VERSION ""

NS_ :

BS_:

BU_: SBW iBooster IMG ESB EBB TM ACC SRS SMART NAVI AHU FCM EPS HDS SS30 METER CVT STR ENG ABS VSA EAT RTC PUH EPT2 EPT1 EPB ASC ACM BCM E4WD ANC TPMS APS

BO_ 3221225472 VECTOR__INDEPENDENT_SIG_MSG: 0 Vector__XXX
 SG_ VSA_MC_PRESSURE_05D_2 : 0|10@1- (1,0) [0|0] "" Vector__XXX
 SG_ VSA_ACC_INHBIT_ACC_BRK_PAD_TMP_1 : 0|1@0+ (1,0) [0|1] "" Vector__XXX
 SG_ VSA_INH_MODE13_2 : 0|1@0+ (1,0) [0|1] "" Vector__XXX
 SG_ VSA_INH_MODE15_2 : 0|1@0+ (1,0) [0|1] "" Vector__XXX
 SG_ VSA_INH_MODE14_2 : 0|1@0+ (1,0) [0|1] "" Vector__XXX
 SG_ VSA_INH_MODE6_2 : 0|1@0+ (1,0) [0|1] "" Vector__XXX
 SG_ VSA_INH_MODE5_2 : 0|1@0+ (1,0) [0|1] "" Vector__XXX
 SG_ VSA_INH_MODE4_2 : 0|1@0+ (1,0) [0|1] "" Vector__XXX
 SG_ VSA_INH_MODE_CHANGE_2 : 0|1@0+ (1,0) [0|1] "" Vector__XXX
 SG_ VSA_INH_MODE0_2 : 0|1@0+ (1,0) [0|1] "" Vector__XXX
 SG_ VSA_INH_MODE1_2 : 0|1@0+ (1,0) [0|1] "" Vector__XXX
 SG_ VSA_INH_MODE2_2 : 0|1@0+ (1,0) [0|1] "" Vector__XXX
 SG_ VSA_INH_MODE3_2 : 0|1@0+ (1,0) [0|1] "" Vector__XXX
 SG_ VSA_INH_MODE7_2 : 0|1@0+ (1,0) [0|1] "" Vector__XXX
 SG_ ENG_CAS_REQ_2 : 0|1@0+ (1,0) [0|1] "" Vector__XXX
 SG_ IMG_REQ_BRKRELAY_STATUS_2 : 0|1@0+ (1,0) [0|1] "" Vector__XXX
 SG_ METER_STRG_SW_PUSH_FOR_VSA_OFF_2 : 0|1@0+ (1,0) [0|0] "" Vector__XXX

BO_ 2209174799 VSA_03AD550F_CH2: 3 VSA
 SG_ VSA_ALIVE_COUNTER_03AD550F_2 : 21|2@0+ (1,0) [0|3] ""  EPS
 SG_ VSA_CHECKSUM_03AD550F_2 : 19|4@0+ (1,0) [0|15] ""  EPS
 SG_ VSA_MAC_stRegMacKey_2 : 15|3@0+ (1,0) [0|7] ""  EPS
 SG_ VSA_MAC_stCompMacAccum_2 : 7|2@0+ (1,0) [0|3] ""  EPS
 SG_ VSA_MAC_stCompMacCont_2 : 5|3@0+ (1,0) [0|7] ""  EPS
 SG_ VSA_MAC_stGenMac_2 : 2|3@0+ (1,0) [0|7] ""  EPS

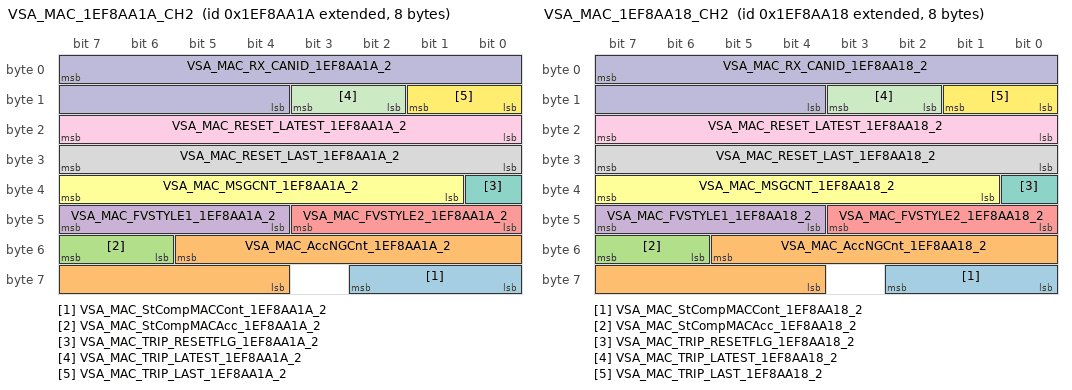
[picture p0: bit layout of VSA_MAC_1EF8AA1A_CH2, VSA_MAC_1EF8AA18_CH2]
BO_ 2667096602 VSA_MAC_1EF8AA1A_CH2: 8 Vector__XXX
 SG_ VSA_MAC_StCompMACCont_1EF8AA1A_2 : 58|3@0+ (1,0) [0|7] ""  SRS
 SG_ VSA_MAC_AccNGCnt_1EF8AA1A_2 : 53|10@0+ (1,0) [0|1023] ""  SRS
 SG_ VSA_MAC_StCompMACAcc_1EF8AA1A_2 : 55|2@0+ (1,0) [0|3] ""  SRS
 SG_ VSA_MAC_FVSTYLE1_1EF8AA1A_2 : 47|4@0+ (1,0) [0|15] ""  SRS
 SG_ VSA_MAC_FVSTYLE2_1EF8AA1A_2 : 43|4@0+ (1,0) [0|15] ""  SRS
 SG_ VSA_MAC_MSGCNT_1EF8AA1A_2 : 39|7@0+ (1,0) [0|127] ""  SRS
 SG_ VSA_MAC_TRIP_RESETFLG_1EF8AA1A_2 : 32|1@0+ (1,0) [0|1] ""  SRS
 SG_ VSA_MAC_RESET_LAST_1EF8AA1A_2 : 31|8@0+ (1,0) [0|255] ""  SRS
 SG_ VSA_MAC_RESET_LATEST_1EF8AA1A_2 : 23|8@0+ (1,0) [0|255] ""  SRS
 SG_ VSA_MAC_RX_CANID_1EF8AA1A_2 : 7|12@0+ (1,0) [0|4095] ""  SRS
 SG_ VSA_MAC_TRIP_LATEST_1EF8AA1A_2 : 11|2@0+ (1,0) [0|3] ""  SRS
 SG_ VSA_MAC_TRIP_LAST_1EF8AA1A_2 : 9|2@0+ (1,0) [0|3] ""  SRS

BO_ 2667096600 VSA_MAC_1EF8AA18_CH2: 8 VSA
 SG_ VSA_MAC_StCompMACCont_1EF8AA18_2 : 58|3@0+ (1,0) [0|7] ""  EBB
 SG_ VSA_MAC_AccNGCnt_1EF8AA18_2 : 53|10@0+ (1,0) [0|1023] ""  EBB
 SG_ VSA_MAC_StCompMACAcc_1EF8AA18_2 : 55|2@0+ (1,0) [0|3] ""  EBB
 SG_ VSA_MAC_FVSTYLE1_1EF8AA18_2 : 47|4@0+ (1,0) [0|15] ""  EBB
 SG_ VSA_MAC_FVSTYLE2_1EF8AA18_2 : 43|4@0+ (1,0) [0|15] ""  EBB
 SG_ VSA_MAC_MSGCNT_1EF8AA18_2 : 39|7@0+ (1,0) [0|127] ""  EBB
 SG_ VSA_MAC_TRIP_RESETFLG_1EF8AA18_2 : 32|1@0+ (1,0) [0|1] ""  EBB
 SG_ VSA_MAC_RESET_LAST_1EF8AA18_2 : 31|8@0+ (1,0) [0|255] ""  EBB
 SG_ VSA_MAC_RESET_LATEST_1EF8AA18_2 : 23|8@0+ (1,0) [0|255] ""  EBB
 SG_ VSA_MAC_RX_CANID_1EF8AA18_2 : 7|12@0+ (1,0) [0|4095] ""  EBB
 SG_ VSA_MAC_TRIP_LATEST_1EF8AA18_2 : 11|2@0+ (1,0) [0|3] ""  EBB
 SG_ VSA_MAC_TRIP_LAST_1EF8AA18_2 : 9|2@0+ (1,0) [0|3] ""  EBB

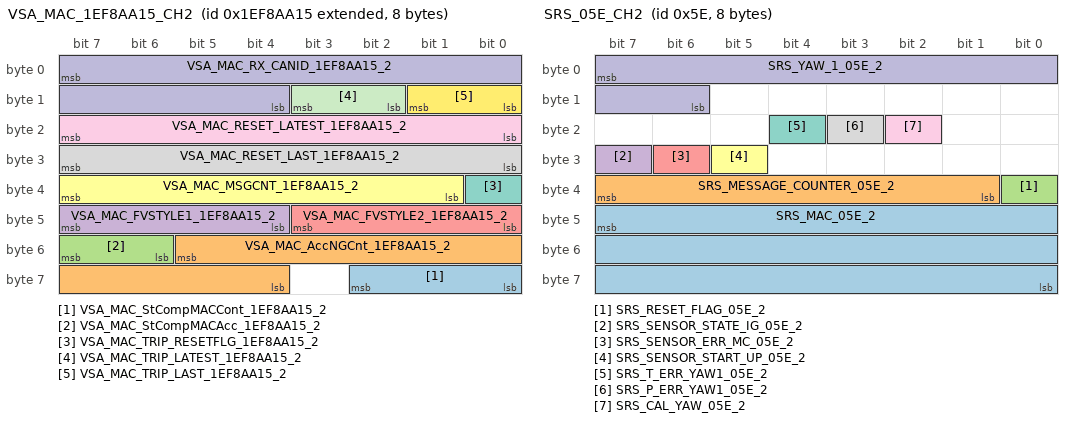
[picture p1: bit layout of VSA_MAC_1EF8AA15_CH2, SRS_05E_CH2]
BO_ 2667096597 VSA_MAC_1EF8AA15_CH2: 8 VSA
 SG_ VSA_MAC_StCompMACCont_1EF8AA15_2 : 58|3@0+ (1,0) [0|7] ""  ESB
 SG_ VSA_MAC_AccNGCnt_1EF8AA15_2 : 53|10@0+ (1,0) [0|1023] ""  ESB
 SG_ VSA_MAC_StCompMACAcc_1EF8AA15_2 : 55|2@0+ (1,0) [0|3] ""  ESB
 SG_ VSA_MAC_FVSTYLE1_1EF8AA15_2 : 47|4@0+ (1,0) [0|15] ""  ESB
 SG_ VSA_MAC_FVSTYLE2_1EF8AA15_2 : 43|4@0+ (1,0) [0|15] ""  ESB
 SG_ VSA_MAC_MSGCNT_1EF8AA15_2 : 39|7@0+ (1,0) [0|127] ""  ESB
 SG_ VSA_MAC_TRIP_RESETFLG_1EF8AA15_2 : 32|1@0+ (1,0) [0|1] ""  ESB
 SG_ VSA_MAC_RESET_LAST_1EF8AA15_2 : 31|8@0+ (1,0) [0|255] ""  ESB
 SG_ VSA_MAC_RESET_LATEST_1EF8AA15_2 : 23|8@0+ (1,0) [0|255] ""  ESB
 SG_ VSA_MAC_RX_CANID_1EF8AA15_2 : 7|12@0+ (1,0) [0|4095] ""  ESB
 SG_ VSA_MAC_TRIP_LATEST_1EF8AA15_2 : 11|2@0+ (1,0) [0|3] ""  ESB
 SG_ VSA_MAC_TRIP_LAST_1EF8AA15_2 : 9|2@0+ (1,0) [0|3] ""  ESB

BO_ 524 EBB_20C_CH2: 8 iBooster
 SG_ EBB_MAC_20C_2 : 47|24@0+ (1,0) [0|16777216] "-"  VSA
 SG_ EBB_MESSAGE_COUNTER_20C_2 : 39|7@0+ (1,0) [0|127] "-"  VSA
 SG_ EBB_RESET_FLAG_20C_2 : 32|1@0+ (1,0) [0|1] "-"  VSA
 SG_ EBB_TARGET_PRESSURE_20C_2 : 15|10@0+ (1,0) [0|1023] "-"  VSA
 SG_ EBB_STATUS_20C_2 : 2|3@0+ (1,0) [0|7] "-"  VSA
 SG_ EBB_BRKMODE_STATUS_20C_2 : 7|3@0+ (1,0) [0|7] "-"  VSA

BO_ 94 SRS_05E_CH2: 8 SRS
 SG_ SRS_MAC_05E_2 : 47|24@0+ (1,0) [0|16777216] ""  VSA
 SG_ SRS_MESSAGE_COUNTER_05E_2 : 39|7@0+ (1,0) [0|127] ""  VSA
 SG_ SRS_RESET_FLAG_05E_2 : 32|1@0+ (1,0) [0|1] ""  VSA
 SG_ SRS_SENSOR_STATE_IG_05E_2 : 31|1@0+ (1,0) [0|1] ""  VSA
 SG_ SRS_SENSOR_ERR_MC_05E_2 : 30|1@0+ (1,0) [0|1] "-"  VSA
 SG_ SRS_SENSOR_START_UP_05E_2 : 29|1@0+ (1,0) [0|1] ""  VSA
 SG_ SRS_T_ERR_YAW1_05E_2 : 20|1@0+ (1,0) [0|1] "-"  VSA
 SG_ SRS_P_ERR_YAW1_05E_2 : 19|1@0+ (1,0) [0|1] "-"  VSA
 SG_ SRS_CAL_YAW_05E_2 : 18|1@0+ (1,0) [0|1] "-"  VSA
 SG_ SRS_YAW_1_05E_2 : 7|10@0+ (0.244141,-125) [0|124.756] "deg/sec"  VSA

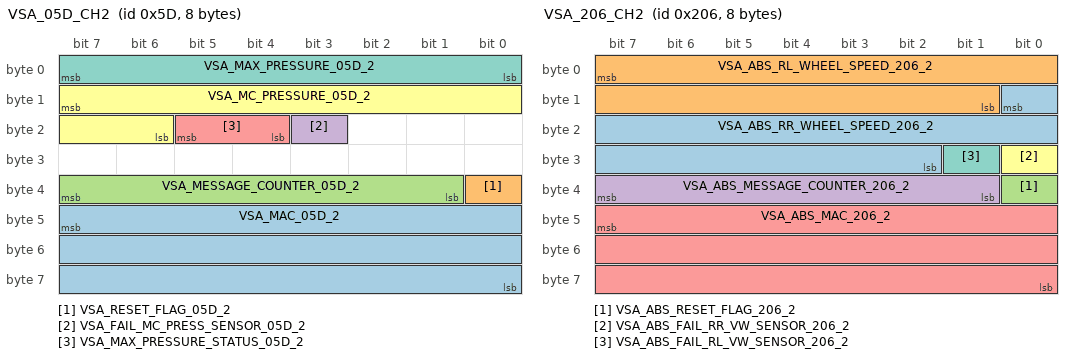
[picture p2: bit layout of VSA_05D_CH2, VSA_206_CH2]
BO_ 93 VSA_05D_CH2: 8 VSA
 SG_ VSA_MAC_05D_2 : 47|24@0+ (1,0) [0|16777215] ""  iBooster
 SG_ VSA_RESET_FLAG_05D_2 : 32|1@0+ (1,0) [0|1] ""  iBooster
 SG_ VSA_MESSAGE_COUNTER_05D_2 : 39|7@0+ (1,0) [0|127] ""  iBooster
 SG_ VSA_FAIL_MC_PRESS_SENSOR_05D_2 : 19|1@0+ (1,0) [0|1] ""  iBooster
 SG_ VSA_MAX_PRESSURE_STATUS_05D_2 : 21|2@0+ (1,0) [0|3] ""  iBooster
 SG_ VSA_MC_PRESSURE_05D_2 : 15|10@0+ (30,-3000) [-3000|27690] "KPa"  iBooster
 SG_ VSA_MAX_PRESSURE_05D_2 : 7|8@0+ (100,0) [0|25500] ""  iBooster

BO_ 777 METER_309_CH2: 8 METER
 SG_ METER_CHECKSUM_309_2 : 59|4@0+ (1,0) [0|0] ""  VSA
 SG_ METER_ALIVE_COUNTER_309_2 : 61|2@0+ (1,0) [0|0] ""  VSA
 SG_ METER_SPEED_UNIT_2 : 63|1@0+ (1,0) [0|0] ""  VSA
 SG_ METER_DIGITAL_SPEED_DISPLAY_2 : 31|8@0+ (1,0) [0|0] "km/h or mp/h"  VSA

BO_ 2588256839 VSA_1A45AA47_CH2: 8 VSA
 SG_ VSA_ALIVE_COUNTER_1A45AA47_2 : 61|2@0+ (1,0) [0|3] "" Vector__XXX
 SG_ VSA_CHECKSUM_1A45AA47_2 : 59|4@0+ (1,0) [0|15] "" Vector__XXX
 SG_ VSA_SUBRECO_UPDATE_2 : 19|2@0+ (1,0) [0|3] "" Vector__XXX
 SG_ VSA_FREEZE_UPDATE_2 : 17|2@0+ (1,0) [0|0] "" Vector__XXX
 SG_ VSA_OBS_UPDATE_2 : 3|2@0+ (1,0) [0|3] "" Vector__XXX
 SG_ VSA_DTC_UPDATE_2 : 1|2@0+ (1,0) [0|3] "" Vector__XXX

BO_ 1 New_Message_92: 8 Vector__XXX
 SG_ New_Signal_819 : 40|8@1+ (1,0) [0|0] "" Vector__XXX

BO_ 315 ENG_13B_CH2: 7 ENG
 SG_ VSA_CHECKSUM_13B_2 : 51|4@0+ (1,0) [0|15] ""  VSA
 SG_ VSA_ALIVE_COUNTER_13B_2 : 53|2@0+ (1,0) [0|3] ""  VSA
 SG_ ENG_POWER_PLANT_SPEED_2 : 7|15@0+ (1,0) [0|32767] "rpm"  VSA

BO_ 179 IMG_0B3_CH2: 8 IMG
 SG_ IMG_CHECKSUM_0B3_2 : 59|4@0+ (1,0) [0|15] ""  VSA
 SG_ IMG_ALIVE_COUNTER_0B3_2 : 61|2@0+ (1,0) [0|4] ""  VSA
 SG_ EBB_BRKMODE_STATUS_0B3_2 : 12|3@0+ (1,0) [0|8] ""  VSA
 SG_ EBB_TARGET_PRESSURE_0B3_2 : 7|10@0+ (25,0) [0|25575] "Kpa"  VSA

BO_ 780 ACC_30C_CH2: 8 ACC
 SG_ ACC_CHECKSUM_30C_2 : 59|4@0+ (1,0) [0|15] ""  VSA
 SG_ ACC_ALIVE_COUNTER_30C_2 : 61|2@0+ (1,0) [0|3] ""  VSA
 SG_ ACC_INFO_IND_ACCLSF_ENGAGE_2 : 32|1@0+ (1,0) [0|1] ""  VSA

BO_ 0 SBW_358_CH2: 7 SBW
 SG_ SBW_MID_N_HOLD_2 : 20|1@0+ (1,0) [0|1] ""  VSA
 SG_ SBW_CHECKSUM_358_2 : 51|4@0+ (1,0) [0|15] ""  VSA
 SG_ SBW_ALIVE_COUNTER_358_2 : 53|2@0+ (1,0) [0|3] ""  VSA

BO_ 669 VSA_29D_CH2: 8 VSA
 SG_ VSA_RESET_COUNTER_29D_2 : 7|24@0+ (1,0) [0|16777215] "-" Vector__XXX
 SG_ VSA_MAC_29D_2 : 31|40@0+ (1,0) [0|1099511627775] "-" Vector__XXX

BO_ 668 VSA_29C_CH2: 8 VSA
 SG_ VSA_TRIP_COUNTER_29C_2 : 7|24@0+ (1,0) [0|16777215] "-" Vector__XXX
 SG_ VSA_MAC_29C_2 : 31|40@0+ (1,0) [0|1099511627775] "-" Vector__XXX

BO_ 518 VSA_206_CH2: 8 VSA
 SG_ VSA_ABS_RR_WHEEL_SPEED_206_2 : 8|15@0+ (0.01,0) [0|327.67] "km/h" Vector__XXX
 SG_ VSA_ABS_RL_WHEEL_SPEED_206_2 : 7|15@0+ (0.01,0) [0|327.67] "km/h" Vector__XXX
 SG_ VSA_ABS_RESET_FLAG_206_2 : 32|1@1- (1,0) [0|1] "-" Vector__XXX
 SG_ VSA_ABS_MESSAGE_COUNTER_206_2 : 39|7@0+ (1,0) [0|127] "" Vector__XXX
 SG_ VSA_ABS_MAC_206_2 : 47|24@0+ (1,0) [0|16777215] "-" Vector__XXX
 SG_ VSA_ABS_FAIL_RR_VW_SENSOR_206_2 : 24|1@0+ (1,0) [0|1] "-" Vector__XXX
 SG_ VSA_ABS_FAIL_RL_VW_SENSOR_206_2 : 25|1@0+ (1,0) [0|1] "-" Vector__XXX

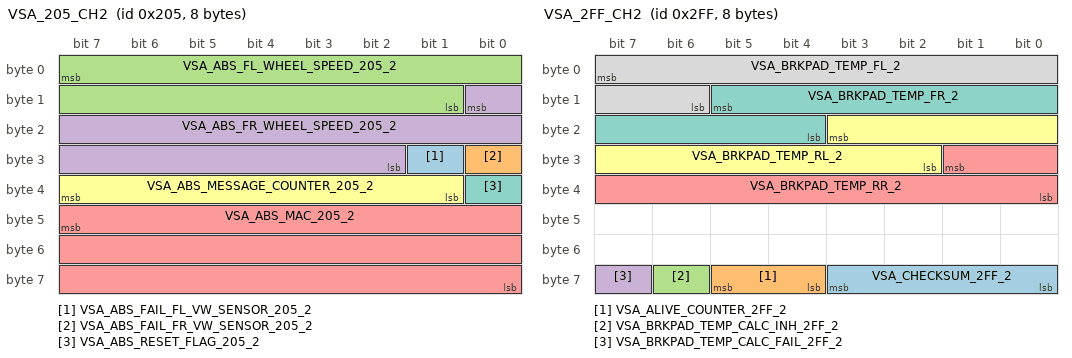
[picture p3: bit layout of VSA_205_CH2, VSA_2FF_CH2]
BO_ 517 VSA_205_CH2: 8 VSA
 SG_ VSA_ABS_FAIL_FL_VW_SENSOR_205_2 : 25|1@0+ (1,0) [0|1] "-" Vector__XXX
 SG_ VSA_ABS_FAIL_FR_VW_SENSOR_205_2 : 24|1@0+ (1,0) [0|1] "-" Vector__XXX
 SG_ VSA_ABS_FL_WHEEL_SPEED_205_2 : 7|15@0+ (0.01,0) [0|327.67] "km/h" Vector__XXX
 SG_ VSA_ABS_FR_WHEEL_SPEED_205_2 : 8|15@0+ (0.01,0) [0|327.67] "km/h" Vector__XXX
 SG_ VSA_ABS_MAC_205_2 : 47|24@0+ (1,0) [0|16777215] "-" Vector__XXX
 SG_ VSA_ABS_MESSAGE_COUNTER_205_2 : 39|7@0+ (1,0) [0|127] "-" Vector__XXX
 SG_ VSA_ABS_RESET_FLAG_205_2 : 32|1@0+ (1,0) [0|1] "-" Vector__XXX

BO_ 425 VSA_1A9_CH2: 8 VSA
 SG_ VSA_FZR_LIM_B_2 : 0|1@0+ (1,0) [0|1] ""  E4WD
 SG_ VSA_FZR_CTCS_B_2 : 4|1@0+ (1,0) [0|1] ""  E4WD
 SG_ VSA_E4WD_TRQ_UP_REQ_2 : 31|8@0+ (10,0) [0|2550] "Nm"  E4WD
 SG_ VSA_E4WD_TRQ_LIMITER_REQ_2 : 15|8@0+ (10,0) [0|2550] "Nm"  E4WD
 SG_ VSA_CHECKSUM_1A9_2 : 59|4@0+ (1,0) [0|15] ""  E4WD
 SG_ VSA_ALIVE_COUNTER_1A9_2 : 61|2@0+ (1,0) [0|3] ""  E4WD

BO_ 332 ESB_14C_CH2: 8 ESB
 SG_ ESB_RESET_FLAG_14C_2 : 32|1@0+ (1,0) [0|1] "" Vector__XXX
 SG_ ESB_REQ_HBC_14C_2 : 7|1@0+ (1,0) [0|1] "" Vector__XXX
 SG_ ESB_MESSAGE_COUNTER_14C_2 : 39|7@0+ (1,0) [0|127] "-" Vector__XXX
 SG_ ESB_MAC_14C_2 : 47|24@0+ (1,0) [0|16777215] ""  VSA

BO_ 767 VSA_2FF_CH2: 8 VSA
 SG_ VSA_CHECKSUM_2FF_2 : 59|4@0+ (1,0) [0|15] "" Vector__XXX
 SG_ VSA_ALIVE_COUNTER_2FF_2 : 61|2@0+ (1,0) [0|3] "" Vector__XXX
 SG_ VSA_BRKPAD_TEMP_CALC_INH_2FF_2 : 62|1@0+ (1,0) [0|1] "" Vector__XXX
 SG_ VSA_BRKPAD_TEMP_CALC_FAIL_2FF_2 : 63|1@0+ (1,0) [0|1] "" Vector__XXX
 SG_ VSA_BRKPAD_TEMP_RR_2 : 25|10@0+ (1,0) [0|1023] "degc" Vector__XXX
 SG_ VSA_BRKPAD_TEMP_RL_2 : 19|10@0+ (1,0) [0|1023] "degc" Vector__XXX
 SG_ VSA_BRKPAD_TEMP_FR_2 : 13|10@0+ (1,0) [0|1023] "degc" Vector__XXX
 SG_ VSA_BRKPAD_TEMP_FL_2 : 7|10@0+ (1,0) [0|1023] "degc" Vector__XXX

BO_ 555 IMG_22B_CH2: 8 IMG
 SG_ IMG_CHECKSUM_22B_2 : 59|4@0+ (1,0) [0|15] ""  VSA
 SG_ IMG_ALIVE_COUNTER_22B_2 : 61|2@0+ (1,0) [0|3] ""  VSA
 SG_ IMG_IDS_GRP_A3_MODE_2 : 15|4@0+ (1,0) [0|15] ""  VSA

BO_ 562 APS_232_CH2: 4 APS
 SG_ APS_ALIVE_COUNTER_232_2 : 29|2@0+ (1,0) [0|3] "" Vector__XXX
 SG_ APS_CHECKSUM_232_2 : 27|4@0+ (1,0) [0|16] "" Vector__XXX
 SG_ APS_SYSTEM_ACTIVE_2 : 2|1@0+ (1,0) [0|1] "" Vector__XXX

BO_ 1646 VSA_66E_CH2: 8 VSA
 SG_ VSA_CHECKSUM_66E_2 : 59|4@0+ (1,0) [0|15] ""  NAVI
 SG_ VSA_ALIVE_COUNTER_66E_2 : 61|2@0+ (1,0) [0|3] ""  NAVI
 SG_ VSA_OBS_OVERWRITE_2 : 62|1@0+ (1,0) [0|1] ""  NAVI
 SG_ VSA_OBS_TRIGGER_2 : 63|1@0+ (1,0) [0|1] ""  NAVI
 SG_ VSA_MCPS_OFFSET_2 : 35|4@0+ (100,-700) [0|0] ""  NAVI
 SG_ VSA_CALIB_STATUS_STR_2 : 36|1@0+ (1,0) [0|1] ""  NAVI
 SG_ VSA_CALIB_STATUS_LONG_2 : 37|1@0+ (1,0) [0|1] ""  NAVI
 SG_ VSA_CALIB_STATUS_LATG_2 : 38|1@0+ (1,0) [0|1] ""  NAVI
 SG_ VSA_CALIB_STATUS_YAW_2 : 39|1@0+ (1,0) [0|1] ""  NAVI
 SG_ VSA_ADDFUNC_ACT_2 : 27|4@0+ (1,0) [0|15] ""  NAVI
 SG_ VSA_MAINFUNC_ACT_AHA_2 : 31|1@0+ (1,0) [0|1] ""  NAVI
 SG_ VSA_MAINFUNC_ACT_ABH_2 : 16|1@0+ (1,0) [0|1] ""  NAVI
 SG_ VSA_MAINFUNC_ACT_HSA_2 : 17|1@0+ (1,0) [0|1] ""  NAVI
 SG_ VSA_MAINFUNC_ACT_AYC_2 : 18|1@0+ (1,0) [0|1] ""  NAVI
 SG_ VSA_MAINFUNC_ACT_ETCS_2 : 19|1@0+ (1,0) [0|1] ""  NAVI
 SG_ VSA_MAINFUNC_ACT_BTCS_2 : 20|1@0+ (1,0) [0|1] ""  NAVI
 SG_ VSA_MAINFUNC_ACT_BAS_2 : 21|1@0+ (1,0) [0|1] ""  NAVI
 SG_ VSA_MAINFUNC_ACT_ABS_2 : 22|1@0+ (1,0) [0|1] ""  NAVI
 SG_ VSA_MAINFUNC_ACT_EBD_2 : 23|1@0+ (1,0) [0|1] ""  NAVI
 SG_ VSA_OFFMODE_INFO_2 : 11|2@0+ (1,0) [0|3] ""  NAVI
 SG_ VSA_VEHICLE_MODE_INFO_2 : 15|4@0+ (1,0) [0|15] ""  NAVI
 SG_ VSA_IG_VOLTAGE_2 : 7|8@0+ (0.1,0) [0|255] ""  NAVI

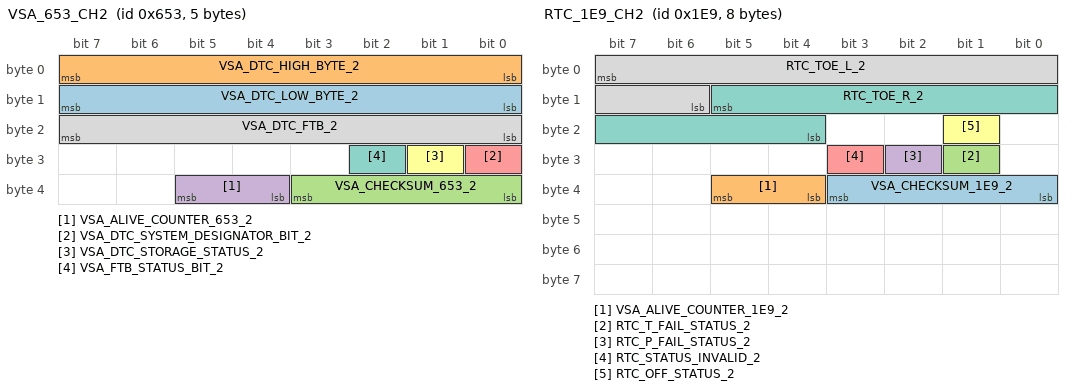
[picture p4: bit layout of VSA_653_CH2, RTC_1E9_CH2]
BO_ 1619 VSA_653_CH2: 5 VSA
 SG_ VSA_DTC_LOW_BYTE_2 : 15|8@0+ (1,0) [0|0] "" Vector__XXX
 SG_ VSA_DTC_HIGH_BYTE_2 : 7|8@0+ (1,0) [0|0] "" Vector__XXX
 SG_ VSA_CHECKSUM_653_2 : 35|4@0+ (1,0) [0|15] "" Vector__XXX
 SG_ VSA_ALIVE_COUNTER_653_2 : 37|2@0+ (1,0) [0|3] "" Vector__XXX
 SG_ VSA_DTC_SYSTEM_DESIGNATOR_BIT_2 : 24|1@0+ (1,0) [0|1] "" Vector__XXX
 SG_ VSA_DTC_STORAGE_STATUS_2 : 25|1@0+ (1,0) [0|1] "" Vector__XXX
 SG_ VSA_FTB_STATUS_BIT_2 : 26|1@0+ (1,0) [0|1] "" Vector__XXX
 SG_ VSA_DTC_FTB_2 : 23|8@0+ (1,0) [0|0] "" Vector__XXX

BO_ 546 METER_222_CH2: 3 METER
 SG_ METER_CHECKSUM_222_2 : 19|4@0+ (1,0) [0|15] "" Vector__XXX
 SG_ METER_ALIVE_COUNTER_222_2 : 21|2@0+ (1,0) [0|3] "" Vector__XXX
 SG_ METER_IDS_MODE_2 : 7|2@0+ (1,0) [0|3] "" Vector__XXX

BO_ 845 VSA_34D_CH2: 2 VSA
 SG_ VSA_CHECKSUM_34D_2 : 11|4@0+ (1,0) [0|15] "" Vector__XXX
 SG_ VSA_ALIVE_COUNTER_34D_2 : 13|2@0+ (1,0) [0|3] "" Vector__XXX
 SG_ VSA_VSA_MODE_STATUS_2 : 2|3@0+ (1,0) [0|7] "" Vector__XXX

BO_ 489 RTC_1E9_CH2: 8 RTC
 SG_ VSA_CHECKSUM_1E9_2 : 35|4@0+ (1,0) [0|15] ""  VSA
 SG_ VSA_ALIVE_COUNTER_1E9_2 : 37|2@0+ (1,0) [0|3] ""  VSA
 SG_ RTC_T_FAIL_STATUS_2 : 25|1@0+ (1,0) [0|1] ""  VSA
 SG_ RTC_P_FAIL_STATUS_2 : 26|1@0+ (1,0) [0|1] ""  VSA
 SG_ RTC_STATUS_INVALID_2 : 27|1@0+ (1,0) [0|1] ""  VSA
 SG_ RTC_OFF_STATUS_2 : 17|1@0+ (1,0) [0|1] ""  VSA
 SG_ RTC_TOE_R_2 : 13|10@0- (0.0043,0) [-2.2016|2.2016] "deg"  VSA
 SG_ RTC_TOE_L_2 : 7|10@0- (0.0043,0) [-2.2016|2.2016] "deg"  VSA

BO_ 493 ENG_1ED_CH2: 8 ENG
 SG_ ENG_CHECKSUM_1ED_2 : 43|4@0+ (1,0) [0|15] ""  VSA
 SG_ ENG_ALIVE_COUNTER_1ED_2 : 45|2@0+ (1,0) [0|3] ""  VSA
 SG_ ENG_POWER_PLANT_SPEED_2 : 29|15@0+ (1,0) [0|32767] "rpm"  VSA

BO_ 446 EBB_1BE_CH2: 3 EBB
 SG_ EBB_BRAKE_PEDAL_ON_STATUS : 3|2@0+ (1,0) [0|0] ""  VSA
 SG_ EBB_IG_ON_2 : 1|1@0+ (1,0) [0|1] ""  VSA
 SG_ EBB_BRAKE_PEDAL_ON : 4|1@0+ (1,0) [0|1] ""  VSA
 SG_ EBB_CHECKSUM_1BE_2 : 19|4@0+ (1,0) [0|15] ""  VSA
 SG_ EBB_ALIVE_COUNTER_1BE_2 : 21|2@0+ (1,0) [0|3] ""  VSA
 SG_ EBB_STATUS_1BE_2 : 7|3@0+ (1,0) [0|7] ""  VSA

BO_ 1108 ENG_454_CH2: 8 ENG
 SG_ ENG_CHECKSUM_454_2 : 59|4@0+ (1,0) [0|15] "" Vector__XXX
 SG_ ENG_ALIVE_COUNTER_454_2 : 61|2@0+ (1,0) [0|3] "" Vector__XXX
 SG_ ENG_FAIL_PA_2 : 20|1@0+ (1,0) [0|1] ""  VSA
 SG_ ENG_ATMOSPHERIC_PRESSURE_2 : 15|8@0+ (2.685,91.4) [91.4|776.075] "mmHg"  VSA

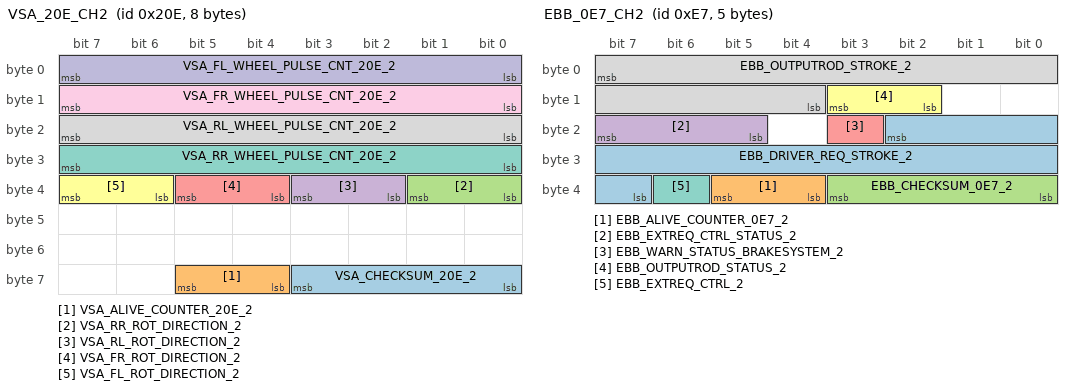
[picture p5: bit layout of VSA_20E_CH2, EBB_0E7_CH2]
BO_ 526 VSA_20E_CH2: 8 VSA
 SG_ VSA_CHECKSUM_20E_2 : 59|4@0+ (1,0) [0|15] "" Vector__XXX
 SG_ VSA_ALIVE_COUNTER_20E_2 : 61|2@0+ (1,0) [0|3] "" Vector__XXX
 SG_ VSA_RR_ROT_DIRECTION_2 : 33|2@0+ (1,0) [0|3] "" Vector__XXX
 SG_ VSA_RL_ROT_DIRECTION_2 : 35|2@0+ (1,0) [0|3] "" Vector__XXX
 SG_ VSA_FR_ROT_DIRECTION_2 : 37|2@0+ (1,0) [0|3] "" Vector__XXX
 SG_ VSA_FL_ROT_DIRECTION_2 : 39|2@0+ (1,0) [0|3] "" Vector__XXX
 SG_ VSA_RR_WHEEL_PULSE_CNT_20E_2 : 31|8@0+ (1,0) [0|255] "" Vector__XXX
 SG_ VSA_RL_WHEEL_PULSE_CNT_20E_2 : 23|8@0+ (1,0) [0|255] "" Vector__XXX
 SG_ VSA_FR_WHEEL_PULSE_CNT_20E_2 : 15|8@0+ (1,0) [0|255] "" Vector__XXX
 SG_ VSA_FL_WHEEL_PULSE_CNT_20E_2 : 7|8@0+ (1,0) [0|255] "" Vector__XXX

BO_ 1571 VSA_623_CH2: 3 VSA
 SG_ VSA_CHECKSUM_623_2 : 19|4@0+ (1,0) [0|0] "" Vector__XXX
 SG_ VSA_ALIVE_COUNTER_623_2 : 21|2@0+ (1,0) [0|0] "" Vector__XXX
 SG_ VSA_ID_2 : 7|16@0+ (1,0) [0|0] ""  BCM

BO_ 1302 METER_516_CH2: 8 METER
 SG_ METER_UNDER10V_516_2 : 42|1@0+ (1,0) [0|1] ""  VSA
 SG_ METER_CHECKSUM_516_2 : 59|4@0+ (1,0) [0|15] ""  VSA
 SG_ METER_ALIVE_COUNTER_516_2 : 61|2@0+ (1,0) [0|3] ""  VSA
 SG_ METER_ODO_DATA_2 : 7|24@0+ (1,0) [0|16777215] "Km"  VSA

BO_ 1568 BCM_620_CH2: 2 BCM
 SG_ BCM_CHECKSUM_620_2 : 11|4@0+ (1,0) [0|0] ""  VSA
 SG_ BCM_ALIVE_COUNTER_620_2 : 13|2@0+ (1,0) [0|0] ""  VSA
 SG_ BCM_ID_REQ_VSA_REC_2 : 3|1@0+ (1,0) [0|0] ""  VSA
 SG_ BCM_ID_REQ_VSA_2 : 6|1@0+ (1,0) [0|0] ""  VSA

BO_ 231 EBB_0E7_CH2: 5 EBB
 SG_ EBB_DRIVER_REQ_STROKE_2 : 18|12@0+ (0.015625,-5) [-5|58.984375] "mm"  VSA
 SG_ EBB_ALIVE_COUNTER_0E7_2 : 37|2@0+ (1,0) [0|3] ""  VSA
 SG_ EBB_CHECKSUM_0E7_2 : 35|4@0+ (1,0) [0|15] ""  VSA
 SG_ EBB_EXTREQ_CTRL_STATUS_2 : 23|3@0+ (1,0) [0|7] ""  VSA
 SG_ EBB_WARN_STATUS_BRAKESYSTEM_2 : 19|1@0+ (1,0) [0|1] ""  VSA
 SG_ EBB_OUTPUTROD_STATUS_2 : 11|2@0+ (1,0) [0|3] ""  VSA
 SG_ EBB_EXTREQ_CTRL_2 : 38|1@0+ (1,0) [0|1] ""  VSA
 SG_ EBB_OUTPUTROD_STROKE_2 : 7|12@0+ (0.015625,-5) [-5|58.9844] "mm"  VSA

BO_ 929 METER_3A1_CH2: 8 METER
 SG_ METER_CHECKSUM_3A1_2 : 59|4@0+ (1,0) [0|15] ""  VSA
 SG_ METER_ALIVE_COUNTER_3A1_2 : 61|2@0+ (1,0) [0|3] ""  VSA
 SG_ METER_DWS_INIT_REQ_SW_2 : 18|1@0+ (1,0) [0|1] ""  VSA
 SG_ METER_DWS_INIT_REQ_2 : 19|1@0+ (1,0) [0|1] ""  VSA

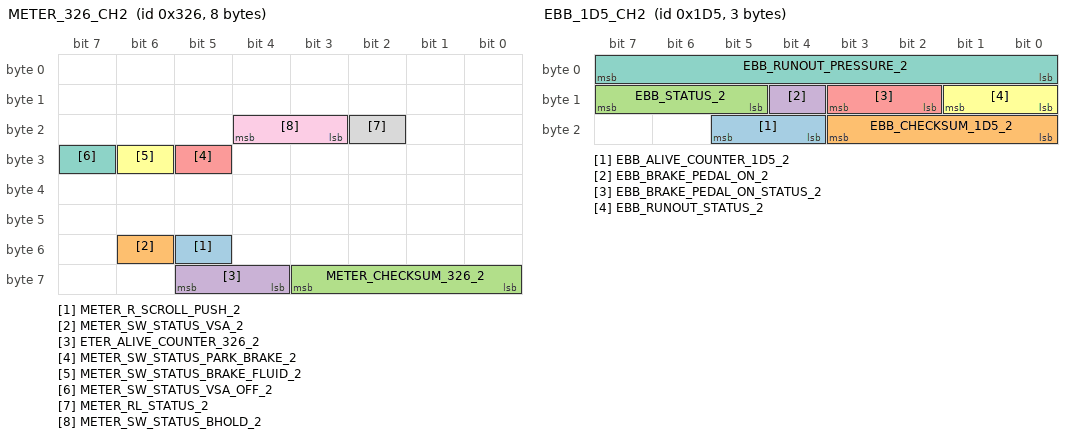
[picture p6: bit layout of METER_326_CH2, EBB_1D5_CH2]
BO_ 806 METER_326_CH2: 8 METER
 SG_ METER_R_SCROLL_PUSH_2 : 53|1@0+ (1,0) [0|1] ""  VSA
 SG_ METER_SW_STATUS_VSA_2 : 54|1@0+ (1,0) [0|1] ""  VSA
 SG_ METER_CHECKSUM_326_2 : 59|4@0+ (1,0) [0|15] ""  VSA
 SG_ ETER_ALIVE_COUNTER_326_2 : 61|2@0+ (1,0) [0|3] ""  VSA
 SG_ METER_SW_STATUS_PARK_BRAKE_2 : 29|1@0+ (1,0) [0|1] ""  VSA
 SG_ METER_SW_STATUS_BRAKE_FLUID_2 : 30|1@0+ (1,0) [0|1] ""  VSA
 SG_ METER_SW_STATUS_VSA_OFF_2 : 31|1@0+ (1,0) [0|1] ""  VSA
 SG_ METER_RL_STATUS_2 : 18|1@0+ (1,0) [0|1] ""  VSA
 SG_ METER_SW_STATUS_BHOLD_2 : 20|2@0+ (1,0) [0|3] ""  VSA

BO_ 469 EBB_1D5_CH2: 3 EBB
 SG_ EBB_ALIVE_COUNTER_1D5_2 : 21|2@0+ (1,0) [0|3] ""  VSA
 SG_ EBB_CHECKSUM_1D5_2 : 19|4@0+ (1,0) [0|15] ""  VSA
 SG_ EBB_STATUS_2 : 15|3@0+ (1,0) [0|7] ""  VSA
 SG_ EBB_BRAKE_PEDAL_ON_2 : 12|1@0+ (1,0) [0|1] ""  VSA
 SG_ EBB_BRAKE_PEDAL_ON_STATUS_2 : 11|2@0+ (1,0) [0|3] ""  VSA
 SG_ EBB_RUNOUT_STATUS_2 : 9|2@0+ (1,0) [0|3] ""  VSA
 SG_ EBB_RUNOUT_PRESSURE_2 : 7|8@0+ (100,0) [0|25500] "KPa"  VSA

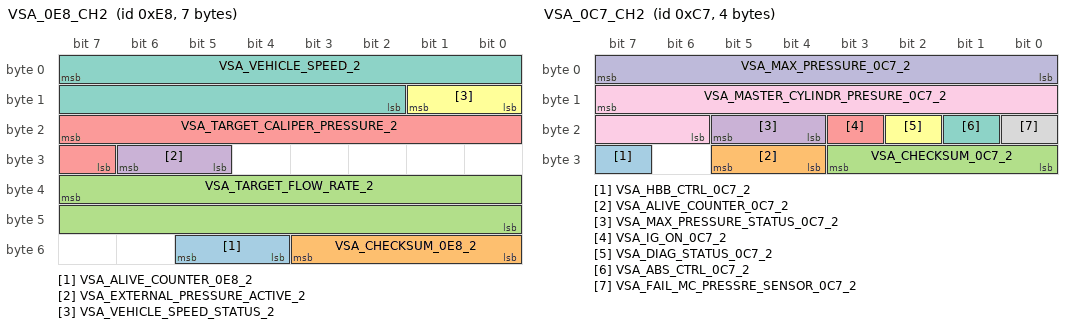
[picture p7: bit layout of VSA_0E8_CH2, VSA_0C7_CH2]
BO_ 232 VSA_0E8_CH2: 7 VSA
 SG_ VSA_ALIVE_COUNTER_0E8_2 : 53|2@0+ (1,0) [0|3] ""  ENG
 SG_ VSA_CHECKSUM_0E8_2 : 51|4@0+ (1,0) [0|15] "" Vector__XXX
 SG_ VSA_TARGET_FLOW_RATE_2 : 39|16@0+ (0.0078125,-252) [-252|252] "ml/s" Vector__XXX
 SG_ VSA_EXTERNAL_PRESSURE_ACTIVE_2 : 30|2@0+ (1,0) [0|3] "" Vector__XXX
 SG_ VSA_TARGET_CALIPER_PRESSURE_2 : 23|9@0+ (12.5,0) [0|6387.5] "KPa" Vector__XXX
 SG_ VSA_VEHICLE_SPEED_STATUS_2 : 9|2@0+ (1,0) [0|3] "" Vector__XXX
 SG_ VSA_VEHICLE_SPEED_2 : 7|14@0+ (0.015625,0) [0|255.984375] "m/s" Vector__XXX

BO_ 199 VSA_0C7_CH2: 4 VSA
 SG_ VSA_HBB_CTRL_0C7_2 : 31|1@0+ (1,0) [0|1] ""  EBB
 SG_ VSA_ALIVE_COUNTER_0C7_2 : 29|2@0+ (1,0) [0|3] ""  EBB
 SG_ VSA_CHECKSUM_0C7_2 : 27|4@0+ (1,0) [0|15] ""  EBB
 SG_ VSA_MAX_PRESSURE_STATUS_0C7_2 : 21|2@0+ (1,0) [0|3] ""  EBB
 SG_ VSA_IG_ON_0C7_2 : 19|1@0+ (1,0) [0|1] ""  EBB
 SG_ VSA_DIAG_STATUS_0C7_2 : 18|1@0+ (1,0) [0|1] ""  EBB
 SG_ VSA_ABS_CTRL_0C7_2 : 17|1@0+ (1,0) [0|1] ""  EBB
 SG_ VSA_FAIL_MC_PRESSRE_SENSOR_0C7_2 : 16|1@0+ (1,0) [0|1] ""  EBB
 SG_ VSA_MASTER_CYLINDR_PRESURE_0C7_2 : 15|10@0+ (30,-3000) [-3000|27690] "KPa"  EBB
 SG_ VSA_MAX_PRESSURE_0C7_2 : 7|8@0+ (100,0) [0|25000] "KPa"  EBB

BO_ 465 VSA_1D1_CH2: 4 VSA
 SG_ VSA_MP_PRESSURE_START_UP_2 : 12|1@0+ (1,0) [0|1] ""  ENG
 SG_ VSA_MP_PRESSURE_ERR_1_2 : 13|1@0+ (1,0) [0|1] ""  ENG
 SG_ VSA_MP_PRESSURE_1_2 : 7|10@0+ (0.1,0) [-102.3|0] "kPa"  ENG
 SG_ VSA_CHECKSUM_1D1_2 : 27|4@0+ (1,0) [0|15] ""  ENG
 SG_ VSA_ALIVE_COUNTER_1D1_2 : 29|2@0+ (1,0) [0|3] ""  ENG

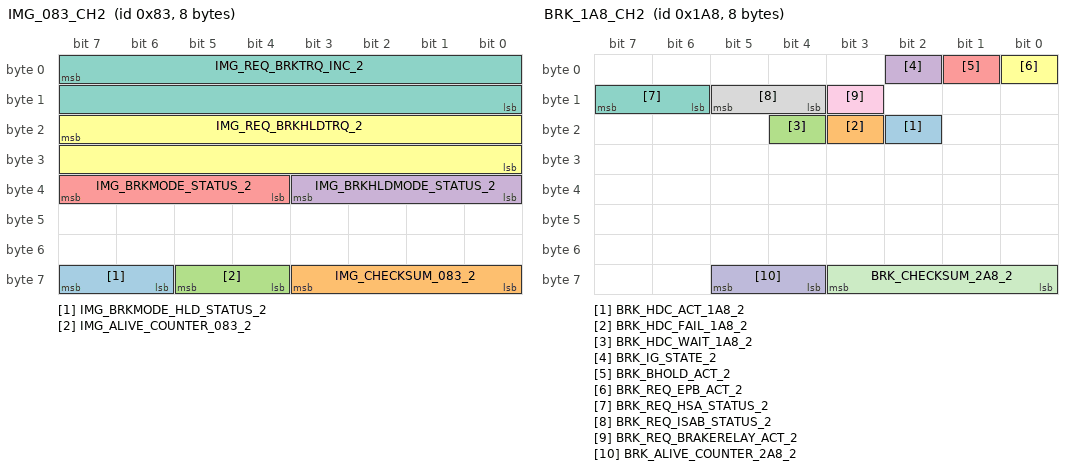
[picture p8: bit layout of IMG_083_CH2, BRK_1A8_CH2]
BO_ 131 IMG_083_CH2: 8 IMG
 SG_ IMG_BRKMODE_HLD_STATUS_2 : 63|2@0+ (1,0) [0|3] ""  VSA
 SG_ IMG_CHECKSUM_083_2 : 59|4@0+ (1,0) [0|15] ""  VSA
 SG_ IMG_ALIVE_COUNTER_083_2 : 61|2@0+ (1,0) [0|3] ""  VSA
 SG_ IMG_BRKHLDMODE_STATUS_2 : 35|4@0+ (1,0) [0|15] ""  VSA
 SG_ IMG_BRKMODE_STATUS_2 : 39|4@0+ (1,0) [0|15] ""  VSA
 SG_ IMG_REQ_BRKHLDTRQ_2 : 23|16@0+ (0.1,0) [0|6553.5] "Nm"  VSA
 SG_ IMG_REQ_BRKTRQ_INC_2 : 7|16@0+ (1,0) [0|65535] "Nm"  VSA

BO_ 424 BRK_1A8_CH2: 8 IMG
 SG_ BRK_HDC_ACT_1A8_2 : 18|1@0+ (1,0) [0|1] "" Vector__XXX
 SG_ BRK_HDC_FAIL_1A8_2 : 19|1@0+ (1,0) [0|1] "" Vector__XXX
 SG_ BRK_HDC_WAIT_1A8_2 : 20|1@0+ (1,0) [0|1] "" Vector__XXX
 SG_ BRK_IG_STATE_2 : 2|1@0+ (1,0) [0|1] ""  VSA
 SG_ BRK_BHOLD_ACT_2 : 1|1@0+ (1,0) [0|1] ""  VSA
 SG_ BRK_REQ_EPB_ACT_2 : 0|1@0+ (1,0) [0|1] ""  VSA
 SG_ BRK_REQ_HSA_STATUS_2 : 15|2@0+ (1,0) [0|3] ""  VSA
 SG_ BRK_REQ_ISAB_STATUS_2 : 13|2@0+ (1,0) [0|3] ""  VSA
 SG_ BRK_REQ_BRAKERELAY_ACT_2 : 11|1@0+ (1,0) [0|1] ""  VSA
 SG_ BRK_ALIVE_COUNTER_2A8_2 : 61|2@0+ (1,0) [0|3] ""  VSA
 SG_ BRK_CHECKSUM_2A8_2 : 59|4@0+ (1,0) [0|15] ""  VSA

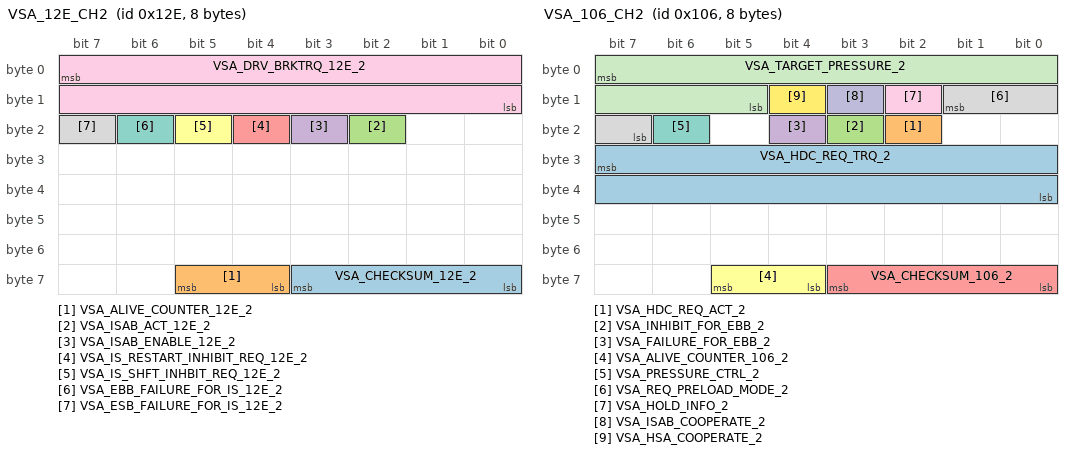
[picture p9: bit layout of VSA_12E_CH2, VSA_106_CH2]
BO_ 302 VSA_12E_CH2: 8 VSA
 SG_ VSA_CHECKSUM_12E_2 : 59|4@0+ (1,0) [0|15] "" Vector__XXX
 SG_ VSA_ALIVE_COUNTER_12E_2 : 61|2@0+ (1,0) [0|3] "" Vector__XXX
 SG_ VSA_ISAB_ACT_12E_2 : 18|1@0+ (1,0) [0|1] "" Vector__XXX
 SG_ VSA_ISAB_ENABLE_12E_2 : 19|1@0+ (1,0) [0|1] "" Vector__XXX
 SG_ VSA_IS_RESTART_INHIBIT_REQ_12E_2 : 20|1@0+ (1,0) [0|1] "" Vector__XXX
 SG_ VSA_IS_SHFT_INHBIT_REQ_12E_2 : 21|1@0+ (1,0) [0|1] "" Vector__XXX
 SG_ VSA_EBB_FAILURE_FOR_IS_12E_2 : 22|1@0+ (1,0) [0|1] "" Vector__XXX
 SG_ VSA_ESB_FAILURE_FOR_IS_12E_2 : 23|1@0+ (1,0) [0|1] "" Vector__XXX
 SG_ VSA_DRV_BRKTRQ_12E_2 : 7|16@0+ (1,0) [0|65535] "Nm" Vector__XXX

BO_ 262 VSA_106_CH2: 8 VSA
 SG_ VSA_HDC_REQ_TRQ_2 : 31|16@0+ (1,0) [0|65535] "" Vector__XXX
 SG_ VSA_HDC_REQ_ACT_2 : 18|1@0+ (1,0) [0|1] "" Vector__XXX
 SG_ VSA_INHIBIT_FOR_EBB_2 : 19|1@0+ (1,0) [0|1] "" Vector__XXX
 SG_ VSA_FAILURE_FOR_EBB_2 : 20|1@0+ (1,0) [0|1] "" Vector__XXX
 SG_ VSA_CHECKSUM_106_2 : 59|4@0+ (1,0) [0|15] "" Vector__XXX
 SG_ VSA_ALIVE_COUNTER_106_2 : 61|2@0+ (1,0) [0|3] "" Vector__XXX
 SG_ VSA_PRESSURE_CTRL_2 : 22|1@0+ (1,0) [0|1] "" Vector__XXX
 SG_ VSA_REQ_PRELOAD_MODE_2 : 9|3@0+ (1,0) [0|7] "" Vector__XXX
 SG_ VSA_HOLD_INFO_2 : 10|1@0+ (1,0) [0|1] "" Vector__XXX
 SG_ VSA_ISAB_COOPERATE_2 : 11|1@0+ (1,0) [0|1] "" Vector__XXX
 SG_ VSA_TARGET_PRESSURE_2 : 7|11@0+ (23.96,0) [0|49046.12] "kPa" Vector__XXX
 SG_ VSA_HSA_COOPERATE_2 : 12|1@0+ (1,0) [0|1] "" Vector__XXX

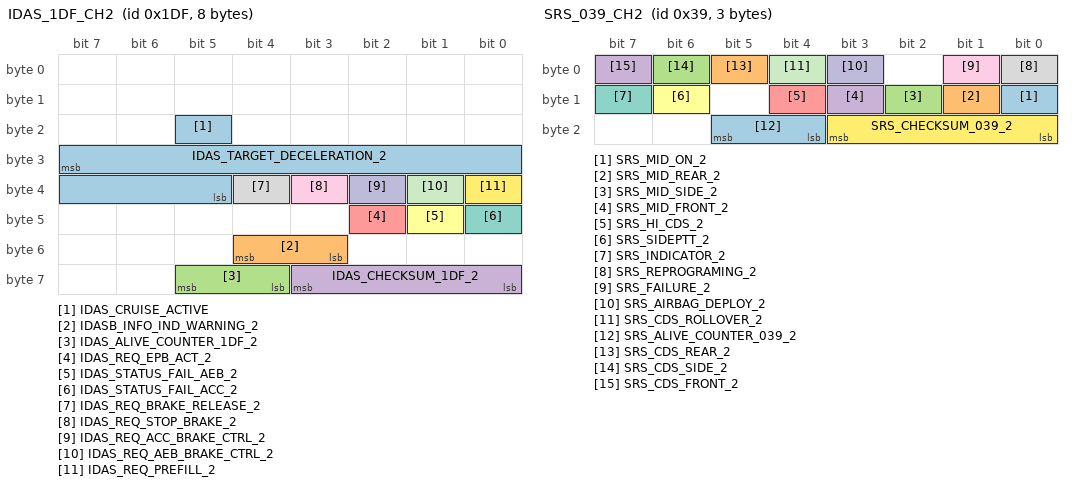
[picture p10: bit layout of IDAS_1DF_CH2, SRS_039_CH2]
BO_ 479 IDAS_1DF_CH2: 8 ACC
 SG_ IDAS_CRUISE_ACTIVE : 21|1@0+ (1,0) [0|1] "" Vector__XXX
 SG_ IDASB_INFO_IND_WARNING_2 : 52|2@0+ (1,0) [0|3] "" Vector__XXX
 SG_ IDAS_ALIVE_COUNTER_1DF_2 : 61|2@0+ (1,0) [0|3] ""  VSA
 SG_ IDAS_CHECKSUM_1DF_2 : 59|4@0+ (1,0) [0|15] ""  VSA
 SG_ IDAS_REQ_EPB_ACT_2 : 42|1@0+ (1,0) [0|1] ""  VSA
 SG_ IDAS_STATUS_FAIL_AEB_2 : 41|1@0+ (1,0) [0|1] ""  VSA
 SG_ IDAS_STATUS_FAIL_ACC_2 : 40|1@0+ (1,0) [0|1] ""  VSA
 SG_ IDAS_REQ_BRAKE_RELEASE_2 : 36|1@0+ (1,0) [0|1] ""  VSA
 SG_ IDAS_REQ_STOP_BRAKE_2 : 35|1@0+ (1,0) [0|1] ""  VSA
 SG_ IDAS_REQ_ACC_BRAKE_CTRL_2 : 34|1@0+ (1,0) [0|1] ""  VSA
 SG_ IDAS_REQ_AEB_BRAKE_CTRL_2 : 33|1@0+ (1,0) [0|1] ""  VSA
 SG_ IDAS_REQ_PREFILL_2 : 32|1@0+ (1,0) [0|1] ""  VSA
 SG_ IDAS_TARGET_DECELERATION_2 : 31|11@0- (0.01,0) [-10.24|10.23] "m/s2"  VSA

BO_ 423 EAT_1A7_CH2: 2 EAT
 SG_ EAT_CHECKSUM_1A7_2 : 11|4@0+ (1,0) [0|15] ""  VSA
 SG_ EAT_ALIVE_COUNTER_1A7_2 : 13|2@0+ (1,0) [0|3] ""  VSA
 SG_ EAT_FAILURE_FOR_EPB_2 : 5|1@0+ (1,0) [0|1] ""  VSA
 SG_ EAT_ATRVS_SW_STATUS_2 : 6|1@0+ (1,0) [0|1] ""  VSA
 SG_ EAT_ATFWD_SW_STATUS_2 : 7|1@0+ (1,0) [0|1] ""  VSA

BO_ 57 SRS_039_CH2: 3 SRS
 SG_ SRS_MID_ON_2 : 8|1@0+ (1,0) [0|1] ""  VSA
 SG_ SRS_MID_REAR_2 : 9|1@0+ (1,0) [0|1] ""  VSA
 SG_ SRS_MID_SIDE_2 : 10|1@0+ (1,0) [0|1] ""  VSA
 SG_ SRS_MID_FRONT_2 : 11|1@0+ (1,0) [0|1] ""  VSA
 SG_ SRS_HI_CDS_2 : 12|1@0+ (1,0) [0|1] ""  VSA
 SG_ SRS_SIDEPTT_2 : 14|1@0+ (1,0) [0|1] ""  VSA
 SG_ SRS_INDICATOR_2 : 15|1@0+ (1,0) [0|1] ""  VSA
 SG_ SRS_REPROGRAMING_2 : 0|1@0+ (1,0) [0|1] ""  VSA
 SG_ SRS_FAILURE_2 : 1|1@0+ (1,0) [0|1] ""  VSA
 SG_ SRS_AIRBAG_DEPLOY_2 : 3|1@0+ (1,0) [0|1] ""  VSA
 SG_ SRS_CDS_ROLLOVER_2 : 4|1@0+ (1,0) [0|1] ""  VSA
 SG_ SRS_CHECKSUM_039_2 : 19|4@0+ (1,0) [0|15] ""  VSA
 SG_ SRS_ALIVE_COUNTER_039_2 : 21|2@0+ (1,0) [0|3] ""  VSA
 SG_ SRS_CDS_REAR_2 : 5|1@0+ (1,0) [0|1] ""  VSA
 SG_ SRS_CDS_SIDE_2 : 6|1@0+ (1,0) [0|1] ""  VSA
 SG_ SRS_CDS_FRONT_2 : 7|1@0+ (1,0) [0|1] ""  VSA

BO_ 773 SRS_305_CH2: 7 SRS
 SG_ SRS_CHECKSUM_305_2 : 51|4@0+ (1,0) [0|15] ""  VSA
 SG_ SRS_ALIVE_COUNTER_305_2 : 53|2@0+ (1,0) [0|3] ""  VSA
 SG_ SRS_DR_BELT_STATUS_2 : 13|2@0+ (1,0) [0|3] ""  VSA
 SG_ SRS_DR_BELT_2 : 7|1@0+ (1,0) [0|1] ""  VSA

BO_ 320 ENG_140_CH2: 8 ENG
 SG_ ENG_REQUEST_EPB_ACT_2 : 6|1@0+ (1,0) [0|1] "" Vector__XXX
 SG_ ENG_DEC_NSS_BHOLD_2 : 7|1@0+ (1,0) [0|1] ""  VSA,SMART,METER,EPS
 SG_ ENG_CHECKSUM_140_2 : 59|4@0+ (1,0) [0|15] ""  VSA,SMART,METER,EPS
 SG_ ENG_ALIVE_COUNTER_140_2 : 61|2@0+ (1,0) [0|3] ""  VSA,SMART,METER,EPS

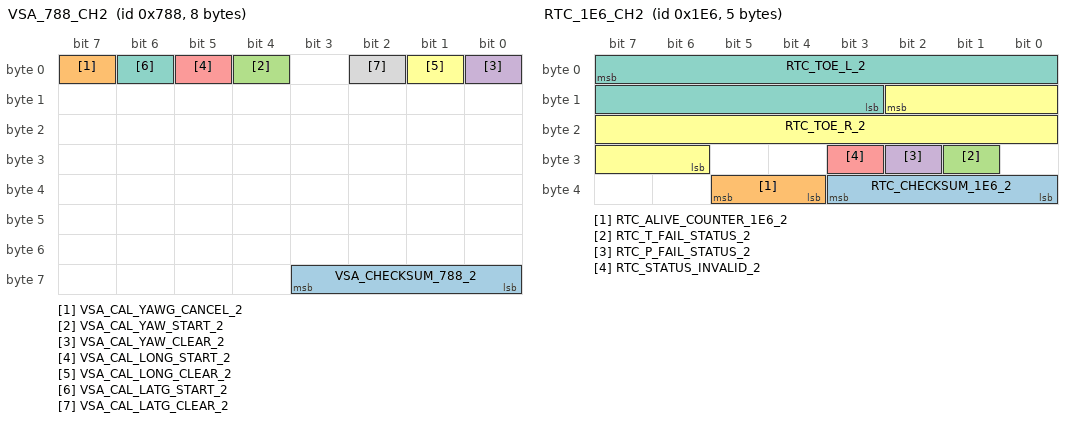
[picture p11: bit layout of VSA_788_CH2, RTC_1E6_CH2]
BO_ 1928 VSA_788_CH2: 8 VSA
 SG_ VSA_CHECKSUM_788_2 : 59|4@0+ (1,0) [0|15] "" Vector__XXX
 SG_ VSA_CAL_YAWG_CANCEL_2 : 7|1@0+ (1,0) [0|1] "" Vector__XXX
 SG_ VSA_CAL_YAW_START_2 : 4|1@0+ (1,0) [0|1] "" Vector__XXX
 SG_ VSA_CAL_YAW_CLEAR_2 : 0|1@0+ (1,0) [0|1] "" Vector__XXX
 SG_ VSA_CAL_LONG_START_2 : 5|1@0+ (1,0) [0|1] "" Vector__XXX
 SG_ VSA_CAL_LONG_CLEAR_2 : 1|1@0+ (1,0) [0|1] "" Vector__XXX
 SG_ VSA_CAL_LATG_START_2 : 6|1@0+ (1,0) [0|1] ""  SRS
 SG_ VSA_CAL_LATG_CLEAR_2 : 2|1@0+ (1,0) [0|1] "" Vector__XXX

BO_ 148 SRS_094_CH2: 8 SRS
 SG_ SRS_STATE_MAC_KEY_2 : 43|1@0+ (1,0) [0|1] ""  VSA
 SG_ SRS_POST_COLLISION_BRK_FAILURE_2 : 40|1@0+ (1,0) [0|1] ""  VSA
 SG_ SRS_POST_COLLISION_BRK_2 : 42|2@0+ (1,0) [0|3] ""  VSA
 SG_ SRS_SENSOR_STATE_IG_2 : 49|1@0+ (1,0) [0|1] ""  VSA,EPS,CVT
 SG_ SRS_SENSOR_START_UP_2 : 63|1@0+ (1,0) [0|1] ""  VSA,SS30,EPS,CVT
 SG_ SRS_SENSOR_ERR_MC_2 : 48|1@0+ (1,0) [0|1] ""  VSA,EPS,CVT
 SG_ SRS_YAW_1_2 : 7|10@0+ (0.244140625,-125) [-125|124.75585938] "deg/sec"  VSA,SS30,EPS
 SG_ SRS_T_ERR_YAW1_2 : 47|1@0+ (1,0) [0|1] ""  VSA,EPS
 SG_ SRS_T_ERR_LON_G_2 : 44|1@0+ (1,0) [0|1] ""  VSA,CVT
 SG_ SRS_T_ERR_LAT_G_2 : 45|1@0+ (1,0) [0|1] ""  VSA,EPS
 SG_ SRS_T_ERR_DEGC_2 : 46|1@0+ (1,0) [0|1] ""  VSA
 SG_ SRS_P_ERR_YAW1_2 : 55|1@0+ (1,0) [0|1] ""  VSA,EPS
 SG_ SRS_P_ERR_LON_G_2 : 52|1@0+ (1,0) [0|1] ""  VSA,CVT
 SG_ SRS_P_ERR_LAT_G_2 : 53|1@0+ (1,0) [0|1] ""  VSA,EPS
 SG_ SRS_P_ERR_DEGC_2 : 54|1@0+ (1,0) [0|1] ""  VSA
 SG_ SRS_LON_G_2 : 25|10@0+ (0.047851563,-24.5) [-24.5|24.452148949] "m/sec^2"  VSA,CVT
 SG_ SRS_LAT_G_2 : 19|10@0+ (0.047851563,-24.5) [-24.5|24.452148949] "m/sec^2"  VSA,SS30,EPS
 SG_ SRS_DEGC_2 : 13|8@0+ (1,-103) [-103|152] ""  VSA
 SG_ SRS_CAL_YAW_2 : 62|1@0+ (1,0) [0|1] ""  VSA
 SG_ SRS_CAL_LON_G_2 : 50|1@0+ (1,0) [0|1] ""  VSA
 SG_ SRS_CAL_LAT_G_2 : 51|1@0+ (1,0) [0|1] ""  VSA
 SG_ SRS_CHECKSUM_094_2 : 59|4@0+ (1,0) [0|15] ""  VSA,SS30,FCM,EPS,CVT
 SG_ SRS_ALIVE_COUNTER_094_2 : 61|2@0+ (1,0) [0|3] ""  VSA,SS30,FCM,EPS,CVT

BO_ 486 RTC_1E6_CH2: 5 RTC
 SG_ RTC_CHECKSUM_1E6_2 : 35|4@0+ (1,0) [0|15] ""  VSA
 SG_ RTC_ALIVE_COUNTER_1E6_2 : 37|2@0+ (1,0) [0|3] ""  VSA
 SG_ RTC_T_FAIL_STATUS_2 : 25|1@0+ (1,0) [0|1] ""  VSA
 SG_ RTC_P_FAIL_STATUS_2 : 26|1@0+ (1,0) [0|1] ""  VSA
 SG_ RTC_STATUS_INVALID_2 : 27|1@0+ (1,0) [0|1] ""  VSA
 SG_ RTC_TOE_R_2 : 10|13@0- (0.0015,0) [-6.144|6.1425] "deg"  VSA
 SG_ RTC_TOE_L_2 : 7|13@0- (0.0015,0) [-6.144|6.1425] "deg"  VSA

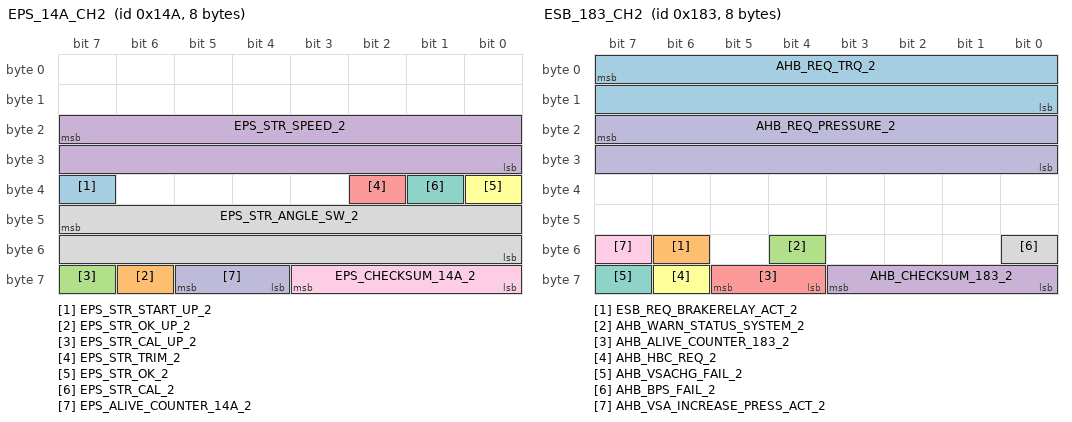
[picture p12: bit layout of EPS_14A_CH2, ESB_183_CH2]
BO_ 330 EPS_14A_CH2: 8 EPS
 SG_ EPS_STR_START_UP_2 : 39|1@0+ (1,0) [0|1] ""  VSA
 SG_ EPS_STR_OK_UP_2 : 62|1@0+ (1,0) [0|1] ""  VSA
 SG_ EPS_STR_CAL_UP_2 : 63|1@0+ (1,0) [0|1] ""  VSA
 SG_ EPS_STR_SPEED_2 : 23|16@0- (1,0) [-2000|2000] "deg/sec"  VSA
 SG_ EPS_STR_TRIM_2 : 34|1@0+ (1,0) [0|1] ""  VSA,SS30,SRS,METER,EPS
 SG_ EPS_STR_OK_2 : 32|1@0+ (1,0) [0|1] ""  VSA,SS30,SRS,METER,EPS
 SG_ EPS_STR_CAL_2 : 33|1@0+ (1,0) [0|1] ""  VSA,SS30,METER,EPS
 SG_ EPS_STR_ANGLE_SW_2 : 47|16@0- (0.1,0) [-3276.8|3276.7] "deg"  VSA,SS30,SRS,METER,EPS
 SG_ EPS_CHECKSUM_14A_2 : 59|4@0+ (1,0) [0|15] ""  VSA,SS30,SRS,METER,FCM,EPS
 SG_ EPS_ALIVE_COUNTER_14A_2 : 61|2@0+ (1,0) [0|3] ""  VSA,SS30,SRS,METER,FCM,EPS

BO_ 441 VSA_1B9_CH2: 5 VSA
 SG_ VSA_CHECKSUM_1B9_2 : 35|4@0+ (1,0) [0|15] "" Vector__XXX
 SG_ VSA_ALIVE_COUNTER_1B9_2 : 37|2@0+ (1,0) [0|3] "" Vector__XXX
 SG_ VSA_ABS_RR_WHEEL_PULSE_CNT_1B9_2 : 31|8@0+ (1,0) [0|255] "" Vector__XXX
 SG_ VSA_ABS_RL_WHEEL_PULSE_CNT_1B9_2 : 23|8@0+ (1,0) [0|255] "" Vector__XXX
 SG_ VSA_ABS_FR_WHEEL_PULSE_CNT_1B9_2 : 15|8@0+ (1,0) [0|255] "" Vector__XXX
 SG_ VSA_ABS_FL_WHEEL_PULSE_CNT_1B9_2 : 7|8@0+ (1,0) [0|255] ""  ABS

BO_ 795 VSA_31B_CH2: 8 VSA
 SG_ VSA_SYSTEM_STATUS_2 : 55|1@0+ (1,0) [0|0] "" Vector__XXX
 SG_ VSA_SYSTEM_STATUS_2 : 42|1@0+ (1,0) [0|0] "" Vector__XXX
 SG_ VSA_MID_WARN_STATUS_DWS_INIT_2 : 32|1@0+ (1,0) [0|1] "" Vector__XXX
 SG_ VSA_REJECT_OFF_SW_OPTN_MID_2 : 63|1@0+ (1,0) [0|1] "" Vector__XXX
 SG_ VSA_DWS_AUTOJUDGE_2 : 36|1@0+ (1,0) [0|1] "" Vector__XXX
 SG_ VSA_MID_REQ_HDC_SW_STATUS_2 : 20|2@0+ (1,0) [0|0] "" Vector__XXX
 SG_ VSA_HDC_CONTROL_STATUS_2 : 22|2@0+ (1,0) [0|0] "" Vector__XXX
 SG_ VSA_HDC_SPEED_UNIT_2 : 23|1@0+ (1,0) [0|0] "" Vector__XXX
 SG_ VSA_HDC_DISPLAY_SPEED_TARGET_2 : 12|5@0+ (1,0) [0|0] "" Vector__XXX
 SG_ VSA_MID_REQ_MAINTENANCE_MODE_2 : 62|1@0+ (1,0) [0|1] "" Vector__XXX
 SG_ VSA_MID_HDC_OP_GUIDE_2 : 18|3@0+ (1,0) [0|7] "" Vector__XXX
 SG_ VSA_MID_REQUEST_IDS_2 : 47|4@0+ (1,0) [0|15] "" Vector__XXX
 SG_ VSA_MID_REQUEST_VSA_OFF_2 : 37|1@0+ (1,0) [0|1] "" Vector__XXX
 SG_ VSA_MID_REQUEST_TCS_OFF_2 : 38|1@0+ (1,0) [0|1] "" Vector__XXX
 SG_ VSA_MID_REQ_EPB_MISOP_GUIDE_2 : 25|2@0+ (1,0) [0|3] "" Vector__XXX
 SG_ VSA_MID_LMP_STATS_OPRTE_BHOLD_2 : 26|1@0+ (1,0) [0|1] "" Vector__XXX
 SG_ VSA_MID_LAMP_STATUS_HDC_OFF_2 : 29|1@0+ (1,0) [0|1] "" Vector__XXX
 SG_ VSA_WARN_STATUS_HDC_2 : 13|1@0+ (1,0) [0|1] "" Vector__XXX
 SG_ VSA_MID_WARN_STATUS_TSA_2 : 2|1@0+ (1,0) [0|1] "" Vector__XXX
 SG_ VSA_MID_WARN_STATUS_BRAKESYSTM_2 : 4|1@0+ (1,0) [0|1] "" Vector__XXX
 SG_ VSA_CHECKSUM_31B_2 : 59|4@0+ (1,0) [0|15] "" Vector__XXX
 SG_ VSA_ALIVE_COUNTER_31B_2 : 61|2@0+ (1,0) [0|3] "" Vector__XXX
 SG_ VSA_WARN_STATUS_HSA_31B_2 : 3|1@0+ (1,0) [0|1] "" Vector__XXX
 SG_ VSA_MID_WARN_STATUS_BRAKE_2 : 5|1@0+ (1,0) [0|1] "" Vector__XXX
 SG_ VSA_MID_WARN_STATUS_ABS_2 : 7|1@0+ (1,0) [0|1] "" Vector__XXX
 SG_ VSA_MID_REQUEST_VSA_31B_2 : 6|1@0+ (1,0) [0|1] "" Vector__XXX
 SG_ VSA_MID_LAMP_STATUS_VSA_OFF_2 : 39|1@0+ (1,0) [0|1] ""  ACC
 SG_ VSA_MID_REQ_BHOLD_STANDBY_2 : 31|1@0+ (1,0) [0|0] "" Vector__XXX
 SG_ VSA_MID_REQ_BHOLD_EPB_OP_INFO_2 : 30|1@0+ (1,0) [0|0] "" Vector__XXX
 SG_ VSA_MID_REQ_BHOLD_MISOP_GUIDE_2 : 28|2@0+ (1,0) [0|3] "" Vector__XXX
 SG_ VSA_MID_REQ_BHOLD_APPLY_BRAKE_2 : 15|1@0+ (1,0) [0|0] "" Vector__XXX
 SG_ VSA_WARN_STATUS_BHOLD_2 : 14|1@0+ (1,0) [0|0] "" Vector__XXX
 SG_ VSA_MID_WARN_STATUS_DWS_2 : 1|1@0+ (1,0) [0|0] "" Vector__XXX
 SG_ VSA_MID_WARN_STATUS_PUNCTURE_2 : 0|1@0+ (1,0) [0|0] "" Vector__XXX

BO_ 387 ESB_183_CH2: 8 E4WD
 SG_ AHB_REQ_TRQ_2 : 7|16@0+ (0.1,0) [0|6553.5] "Nm"  VSA
 SG_ ESB_REQ_BRAKERELAY_ACT_2 : 54|1@0+ (1,0) [0|0] ""  VSA
 SG_ AHB_WARN_STATUS_SYSTEM_2 : 52|1@0+ (1,0) [0|0] ""  VSA
 SG_ AHB_CHECKSUM_183_2 : 59|4@0+ (1,0) [0|15] ""  VSA
 SG_ AHB_ALIVE_COUNTER_183_2 : 61|2@0+ (1,0) [0|3] ""  VSA
 SG_ AHB_HBC_REQ_2 : 62|1@0+ (1,0) [0|1] ""  VSA
 SG_ AHB_VSACHG_FAIL_2 : 63|1@0+ (1,0) [0|1] ""  VSA
 SG_ AHB_BPS_FAIL_2 : 48|1@0+ (1,0) [0|1] ""  VSA
 SG_ AHB_VSA_INCREASE_PRESS_ACT_2 : 55|1@0+ (1,0) [0|1] ""  VSA
 SG_ AHB_REQ_PRESSURE_2 : 23|16@0- (1,0) [-32768|32767] "kpa"  VSA

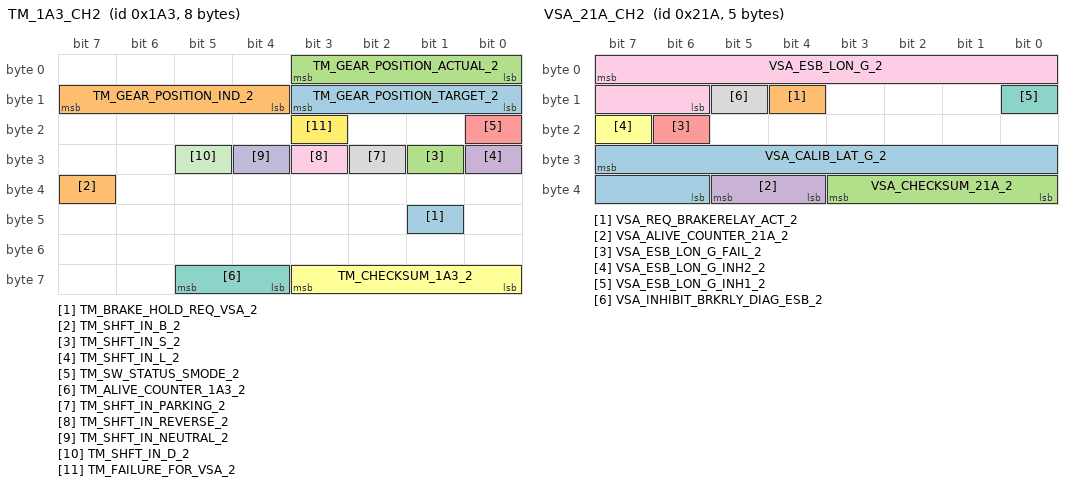
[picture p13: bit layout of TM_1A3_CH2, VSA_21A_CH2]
BO_ 419 TM_1A3_CH2: 8 TM
 SG_ TM_BRAKE_HOLD_REQ_VSA_2 : 41|1@0+ (1,0) [0|1] ""  VSA
 SG_ TM_SHFT_IN_B_2 : 39|1@0+ (1,0) [0|0] ""  VSA
 SG_ TM_SHFT_IN_S_2 : 25|1@0+ (1,0) [0|0] ""  VSA
 SG_ TM_SHFT_IN_L_2 : 24|1@0+ (1,0) [0|1] ""  VSA
 SG_ TM_SW_STATUS_SMODE_2 : 16|1@0+ (1,0) [0|1] ""  VSA
 SG_ TM_CHECKSUM_1A3_2 : 59|4@0+ (1,0) [0|15] ""  VSA
 SG_ TM_ALIVE_COUNTER_1A3_2 : 61|2@0+ (1,0) [0|3] ""  VSA
 SG_ TM_SHFT_IN_PARKING_2 : 26|1@0+ (1,0) [0|1] ""  VSA
 SG_ TM_SHFT_IN_REVERSE_2 : 27|1@0+ (1,0) [0|1] ""  VSA
 SG_ TM_SHFT_IN_NEUTRAL_2 : 28|1@0+ (1,0) [0|1] ""  VSA
 SG_ TM_SHFT_IN_D_2 : 29|1@0+ (1,0) [0|1] ""  VSA
 SG_ TM_FAILURE_FOR_VSA_2 : 19|1@0+ (1,0) [0|1] ""  VSA
 SG_ TM_GEAR_POSITION_TARGET_2 : 11|4@0+ (1,0) [0|15] ""  VSA
 SG_ TM_GEAR_POSITION_IND_2 : 15|4@0+ (1,0) [0|15] ""  VSA
 SG_ TM_GEAR_POSITION_ACTUAL_2 : 3|4@0+ (1,0) [0|15] ""  VSA

BO_ 538 VSA_21A_CH2: 5 VSA
 SG_ VSA_CALIB_LAT_G_2 : 31|10@0+ (0.0478,-24.5) [-24.5|24.3994] "m/s^2" Vector__XXX
 SG_ VSA_REQ_BRAKERELAY_ACT_2 : 12|1@0+ (1,0) [0|1] "" Vector__XXX
 SG_ VSA_CHECKSUM_21A_2 : 35|4@0+ (1,0) [0|15] "" Vector__XXX
 SG_ VSA_ALIVE_COUNTER_21A_2 : 37|2@0+ (1,0) [0|3] "" Vector__XXX
 SG_ VSA_ESB_LON_G_FAIL_2 : 22|1@0+ (1,0) [0|1] "" Vector__XXX
 SG_ VSA_ESB_LON_G_INH2_2 : 23|1@0+ (1,0) [0|1] "" Vector__XXX
 SG_ VSA_ESB_LON_G_INH1_2 : 8|1@0+ (1,0) [0|1] "" Vector__XXX
 SG_ VSA_INHIBIT_BRKRLY_DIAG_ESB_2 : 13|1@0+ (1,0) [0|1] "" Vector__XXX
 SG_ VSA_ESB_LON_G_2 : 7|10@0+ (0.047851563,-24.5) [-24.5|24.452148949] ""  ESB

BO_ 470 ENG_1D6_CH2: 2 ENG
 SG_ ENG_IS_BRK_PRESSURE_1D6_2 : 7|8@0+ (10,0) [0|2550] "KPa"  VSA
 SG_ ENG_ALIVE_COUNTER_1D6_2 : 13|2@0+ (1,0) [0|3] ""  VSA
 SG_ ENG_CHECKSUM_1D6_2 : 11|4@0+ (1,0) [0|15] ""  VSA
 SG_ ENG_ISAB_REQUEST_1D6_2 : 15|1@0+ (1,0) [0|1] ""  VSA

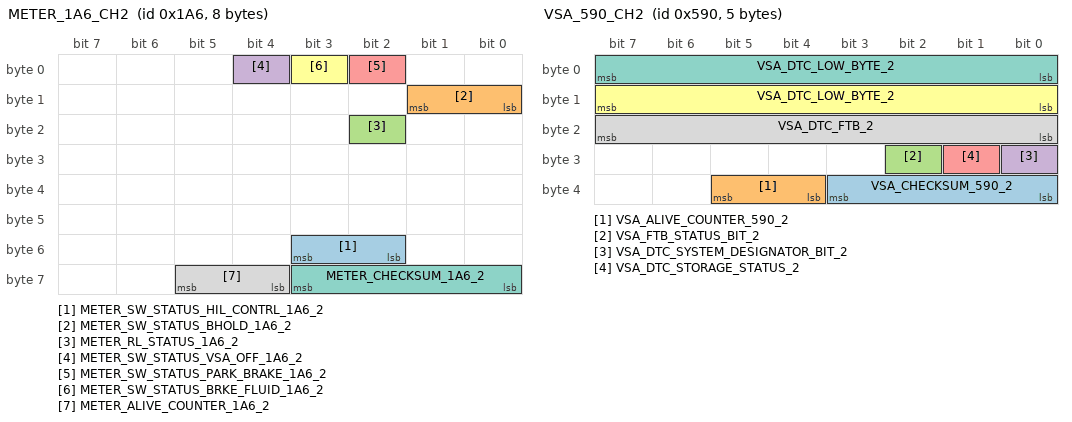
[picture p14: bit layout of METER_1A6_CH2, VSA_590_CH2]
BO_ 422 METER_1A6_CH2: 8 METER
 SG_ METER_SW_STATUS_HIL_CONTRL_1A6_2 : 51|2@0+ (1,0) [0|3] ""  VSA
 SG_ METER_SW_STATUS_BHOLD_1A6_2 : 9|2@0+ (1,0) [0|3] ""  VSA
 SG_ METER_RL_STATUS_1A6_2 : 18|1@0+ (1,0) [0|1] ""  VSA
 SG_ METER_SW_STATUS_VSA_OFF_1A6_2 : 4|1@0+ (1,0) [0|1] ""  VSA
 SG_ METER_SW_STATUS_PARK_BRAKE_1A6_2 : 2|1@0+ (1,0) [0|1] ""  VSA
 SG_ METER_SW_STATUS_BRKE_FLUID_1A6_2 : 3|1@0+ (1,0) [0|1] ""  VSA
 SG_ METER_CHECKSUM_1A6_2 : 59|4@0+ (1,0) [0|15] ""  VSA
 SG_ METER_ALIVE_COUNTER_1A6_2 : 61|2@0+ (1,0) [0|3] ""  VSA

BO_ 884 METER_374_CH2: 8 METER
 SG_ METER_STRG_SW_PUSH_FOR_VSA_OFF_2 : 8|1@0+ (1,0) [0|0] "" Vector__XXX
 SG_ METER_CHECKSUM_374_2 : 59|4@0+ (1,0) [0|15] ""  VSA
 SG_ METER_ALIVE_COUNTER_374_2 : 61|2@0+ (1,0) [0|3] ""  VSA
 SG_ METER_OUTTEMP_2 : 7|8@0+ (1,0) [0|255] ""  VSA

BO_ 1424 VSA_590_CH2: 5 VSA
 SG_ VSA_CHECKSUM_590_2 : 35|4@0+ (1,0) [0|15] "" Vector__XXX
 SG_ VSA_ALIVE_COUNTER_590_2 : 37|2@0+ (1,0) [0|3] "" Vector__XXX
 SG_ VSA_FTB_STATUS_BIT_2 : 26|1@0+ (1,0) [0|1] "" Vector__XXX
 SG_ VSA_DTC_SYSTEM_DESIGNATOR_BIT_2 : 24|1@0+ (1,0) [0|1] "" Vector__XXX
 SG_ VSA_DTC_STORAGE_STATUS_2 : 25|1@0+ (1,0) [0|1] "" Vector__XXX
 SG_ VSA_DTC_LOW_BYTE_2 : 15|8@0+ (1,0) [0|255] "" Vector__XXX
 SG_ VSA_DTC_LOW_BYTE_2 : 7|8@0+ (1,0) [0|255] ""  NAVI
 SG_ VSA_DTC_FTB_2 : 23|8@0+ (1,0) [0|255] "" Vector__XXX

BO_ 661 METER_295_CH2: 4 METER
 SG_ METER_SW_STATUS_HIL_CONTRL_295_2 : 31|2@0+ (1,0) [0|3] ""  VSA
 SG_ METER_DWS_INIT_REQ_SW_2 : 12|1@0+ (1,0) [0|1] ""  VSA
 SG_ METER_CHECKSUM_295_2 : 27|4@0+ (1,0) [0|15] ""  VSA
 SG_ METER_ALIVE_COUNTER_295_2 : 29|2@0+ (1,0) [0|3] ""  VSA
 SG_ METER_DWS_INIT_REQ_2 : 13|1@0+ (1,0) [0|1] ""  VSA

BO_ 660 METER_294_CH2: 8 METER
 SG_ METER_CHECKSUM_294_2 : 59|4@0+ (1,0) [0|15] "" Vector__XXX
 SG_ METER_ALIVE_COUNTER_294_2 : 61|2@0+ (1,0) [0|3] "" Vector__XXX
 SG_ METER_ODO_DATA_2 : 31|24@0+ (1,0) [0|16777215] "km"  VSA

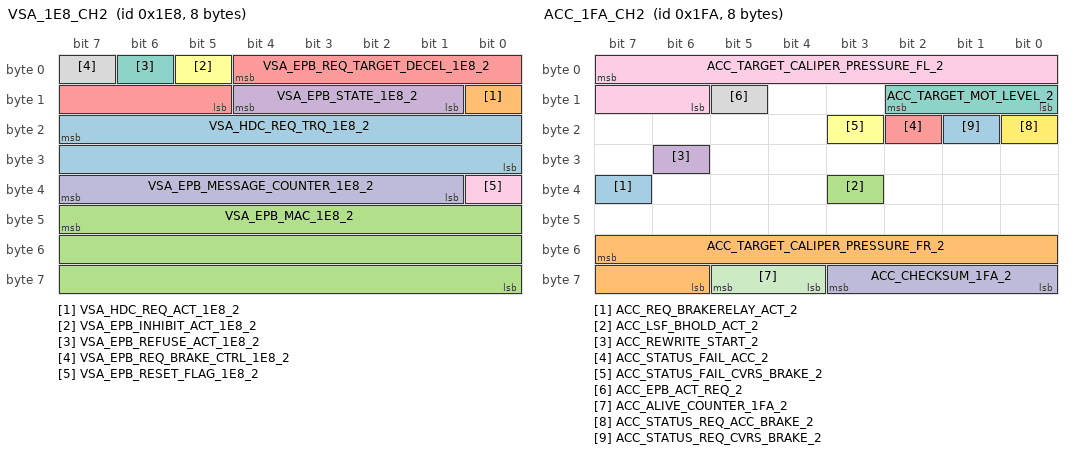
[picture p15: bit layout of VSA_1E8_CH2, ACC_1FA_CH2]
BO_ 488 VSA_1E8_CH2: 8 VSA
 SG_ VSA_HDC_REQ_TRQ_1E8_2 : 23|16@0+ (1,0) [0|65535] "" Vector__XXX
 SG_ VSA_HDC_REQ_ACT_1E8_2 : 8|1@0+ (1,0) [0|1] "" Vector__XXX
 SG_ VSA_EPB_MAC_1E8_2 : 47|24@0+ (1,0) [0|0] "" Vector__XXX
 SG_ VSA_EPB_STATE_1E8_2 : 12|4@0+ (1,0) [0|15] "" Vector__XXX
 SG_ VSA_EPB_REQ_TARGET_DECEL_1E8_2 : 4|8@0+ (1,0) [0|255] "" Vector__XXX
 SG_ VSA_EPB_INHIBIT_ACT_1E8_2 : 5|1@0+ (1,0) [0|1] "" Vector__XXX
 SG_ VSA_EPB_REFUSE_ACT_1E8_2 : 6|1@0+ (1,0) [0|1] "" Vector__XXX
 SG_ VSA_EPB_REQ_BRAKE_CTRL_1E8_2 : 7|1@0+ (1,0) [0|1] "" Vector__XXX
 SG_ VSA_EPB_RESET_FLAG_1E8_2 : 32|1@0+ (1,0) [0|1] "" Vector__XXX
 SG_ VSA_EPB_MESSAGE_COUNTER_1E8_2 : 39|7@0+ (1,0) [0|127] "" Vector__XXX

BO_ 426 VSA_1AA_CH2: 8 VSA
 SG_ VSA_IG_ON_2 : 55|1@0+ (1,0) [0|1] "" Vector__XXX
 SG_ VSA_IDS_INHIBIT_DISABLED_STATE_2 : 44|1@0+ (1,0) [0|1] "" Vector__XXX
 SG_ VSA_IDS_INHIBIT_ACT_2 : 45|1@0+ (1,0) [0|1] "" Vector__XXX
 SG_ VSA_EBB_FAILURE_FOR_IS_2 : 41|1@0+ (1,0) [0|1] "" Vector__XXX
 SG_ VSA_HAC_CUT_REQ_2 : 32|1@0+ (1,0) [0|1] "" Vector__XXX
 SG_ VSA_HBB_IS_REFUSE_REQ_2 : 33|1@0+ (1,0) [0|1] "" Vector__XXX
 SG_ VSA_LOW_VAC_IS_SHFT_INHBIT_REQ_2 : 34|1@0+ (1,0) [0|1] "" Vector__XXX
 SG_ VSA_HBB_IS_SHIFT_INHIBIT_REQ_2 : 35|1@0+ (1,0) [0|1] "" Vector__XXX
 SG_ VSA_MNTMODE_STATUS_2 : 24|1@0+ (1,0) [0|1] "" Vector__XXX
 SG_ VSA_REVERSE_SWITCH_FAIL_2 : 25|1@0+ (1,0) [0|1] "" Vector__XXX
 SG_ VSA_SHFT_IN_REVERSE_2 : 26|1@0+ (1,0) [0|1] "" Vector__XXX
 SG_ VSA_ECD_ACT_2 : 27|1@0+ (1,0) [0|1] "" Vector__XXX
 SG_ VSA_FAIL_FOR_EPB_2 : 28|1@0+ (1,0) [0|1] "" Vector__XXX
 SG_ VSA_REQUEST_EPB_ACT_2 : 29|1@0+ (1,0) [0|1] "" Vector__XXX
 SG_ VSA_EPB_INHIBIT_BRAKE_2 : 30|1@0+ (1,0) [0|1] "" Vector__XXX
 SG_ VSA_EPB_REFUSE_BRAKE_2 : 31|1@0+ (1,0) [0|1] "" Vector__XXX
 SG_ VSA_TM_SUPPORT_BRKE_REFUSE_1AA_2 : 40|1@0+ (1,0) [0|1] "" Vector__XXX
 SG_ VSA_IS_RESTART_INHIBIT_REQ_1AA_2 : 46|1@0+ (1,0) [0|1] ""  EPB
 SG_ VSA_ISAB_ACT_1AA_2 : 42|1@0+ (1,0) [0|1] "" Vector__XXX
 SG_ VSA_BTCS_ACT_1AA_2 : 63|1@0+ (1,0) [0|0] "" Vector__XXX
 SG_ VSA_ISAB_ENABLE_1AA_2 : 43|1@0+ (1,0) [0|1] "" Vector__XXX
 SG_ VSA_IS_SHFT_INHBIT_REQUEST_1AA_2 : 47|1@0+ (1,0) [0|1] "" Vector__XXX
 SG_ VSA_SHIFT_REQ_1AA_2 : 19|2@0+ (1,0) [0|3] "" Vector__XXX
 SG_ VSA_TRQ_DOWN_REQ_FUEL_CUT_1AA_2 : 23|4@0+ (1,0) [0|15] "" Vector__XXX
 SG_ VSA_ALIVE_COUNTER_1AA_2 : 61|2@0+ (1,0) [0|3] "" Vector__XXX
 SG_ VSA_CHECKSUM_1AA_2 : 59|4@0+ (1,0) [0|15] "" Vector__XXX
 SG_ VSA_REQ_MSR_PLUS_TRQ_1AA_2 : 62|1@0+ (1,0) [0|1] "" Vector__XXX
 SG_ VSA_TRQ_CONTROL_MODE_1AA_2 : 17|2@0+ (1,0) [0|3] "" Vector__XXX
 SG_ VSA_REQ_TRQ_1AA_2 : 7|16@0- (0.2,0) [-6553.6|6553.4] "Nm" Vector__XXX

BO_ 506 ACC_1FA_CH2: 8 ACC
 SG_ ACC_REQ_BRAKERELAY_ACT_2 : 39|1@0+ (1,0) [0|1] "" Vector__XXX
 SG_ ACC_TARGET_CALIPER_PRESSURE_FR_2 : 55|10@0+ (12.5,0) [0|12787.5] "kPa" Vector__XXX
 SG_ ACC_LSF_BHOLD_ACT_2 : 35|1@0+ (1,0) [0|1] "" Vector__XXX
 SG_ ACC_REWRITE_START_2 : 30|1@0+ (1,0) [0|1] "" Vector__XXX
 SG_ ACC_STATUS_FAIL_ACC_2 : 18|1@0+ (1,0) [0|1] "" Vector__XXX
 SG_ ACC_STATUS_FAIL_CVRS_BRAKE_2 : 19|1@0+ (1,0) [0|1] "" Vector__XXX
 SG_ ACC_TARGET_MOT_LEVEL_2 : 10|3@0+ (1,0) [0|7] "" Vector__XXX
 SG_ ACC_EPB_ACT_REQ_2 : 13|1@0+ (1,0) [0|1] "" Vector__XXX
 SG_ ACC_TARGET_CALIPER_PRESSURE_FL_2 : 7|10@0+ (12.5,0) [0|12787.5] "kPa" Vector__XXX
 SG_ ACC_CHECKSUM_1FA_2 : 59|4@0+ (1,0) [0|15] "" Vector__XXX
 SG_ ACC_ALIVE_COUNTER_1FA_2 : 61|2@0+ (1,0) [0|3] "" Vector__XXX
 SG_ ACC_STATUS_REQ_ACC_BRAKE_2 : 16|1@0+ (1,0) [0|1] "" Vector__XXX
 SG_ ACC_STATUS_REQ_CVRS_BRAKE_2 : 17|1@0+ (1,0) [0|1] ""  VSA

BO_ 316 ENG_13C_CH2: 8 ENG
 SG_ ENG_IG1_10V_STATUS_2 : 52|1@0+ (1,0) [0|1] "" Vector__XXX
 SG_ ENG_CLUTCH_SW_SIL_2 : 51|1@0+ (1,0) [0|1] "" Vector__XXX
 SG_ ENG_BRK_ACCELE_PEDAL_ON_13C_2 : 44|1@0+ (1,0) [0|1] ""  VSA
 SG_ ENG_CAS_REQ_13C_2 : 53|1@0+ (1,0) [0|0] ""  VSA
 SG_ ENG_NEUTRAL_SENSOR_FAIL_13C_2 : 62|1@0+ (1,0) [0|1] ""  VSA
 SG_ ENG_SHFT_IN_NEUTRAL_13C_2 : 48|1@0+ (1,0) [0|1] ""  VSA
 SG_ ENG_SHFT_IN_REVERSE_13C_2 : 49|1@0+ (1,0) [0|1] ""  VSA
 SG_ ENG_CLUTCH_SW_CC_13C_2 : 50|1@0+ (1,0) [0|1] ""  VSA
 SG_ ENG_VSA_ACK1_13C_2 : 43|4@0+ (1,0) [0|15] ""  VSA
 SG_ ENG_VSA_PERMIT_PLUS_TRQ_13C_2 : 45|1@0+ (1,0) [0|1] ""  VSA
 SG_ ENG_ALIVE_COUNTER_13C_2 : 61|2@0+ (1,0) [0|3] ""  VSA
 SG_ ENG_CHECKSUM_13C_2 : 59|4@0+ (1,0) [0|15] ""  VSA
 SG_ ENG_RECEIVE_ERROR_1AA_2 : 63|1@0+ (1,0) [0|1] ""  VSA
 SG_ ENG_VSA_INHIBIT_VSA_CONTRL_13C_2 : 46|1@0+ (1,0) [0|1] ""  VSA
 SG_ ENG_VSA_REFUSED_VSA_CONTRL_13C_2 : 47|1@0+ (1,0) [0|1] ""  VSA
 SG_ ENG_SMART_ACCELE_PEDAL_POS_13C_2 : 39|8@0+ (0.39215686275,0) [0|100] "%"  VSA
 SG_ ENG_DRIVER_REQ_TRQ_13C_2 : 23|16@0- (0.2,0) [-6553.6|6553.4] "Nm"  VSA
 SG_ ENG_ENG_TRQ_13C_2 : 7|16@0- (0.2,0) [-6553.6|6553.4] "Nm"  VSA

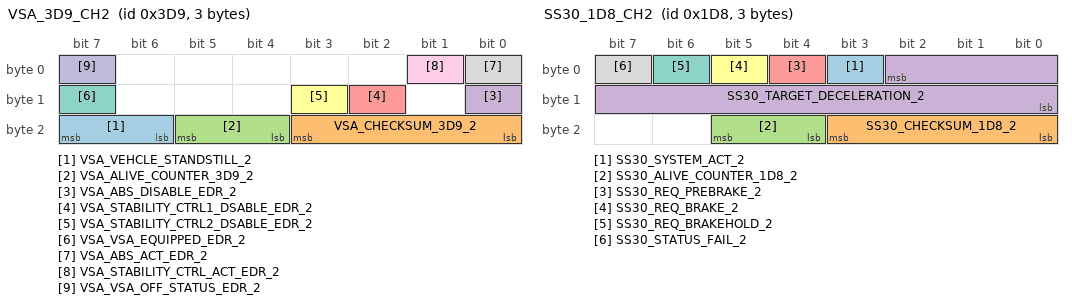
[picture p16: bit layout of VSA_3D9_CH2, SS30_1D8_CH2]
BO_ 985 VSA_3D9_CH2: 3 VSA
 SG_ VSA_VEHCLE_STANDSTILL_2 : 23|2@0+ (1,0) [0|3] "" Vector__XXX
 SG_ VSA_CHECKSUM_3D9_2 : 19|4@0+ (1,0) [0|15] ""  SRS
 SG_ VSA_ALIVE_COUNTER_3D9_2 : 21|2@0+ (1,0) [0|3] ""  SRS
 SG_ VSA_ABS_DISABLE_EDR_2 : 8|1@0+ (1,0) [0|1] ""  SRS
 SG_ VSA_STABILITY_CTRL1_DSABLE_EDR_2 : 10|1@0+ (1,0) [0|1] ""  SRS
 SG_ VSA_STABILITY_CTRL2_DSABLE_EDR_2 : 11|1@0+ (1,0) [0|1] ""  SRS
 SG_ VSA_VSA_EQUIPPED_EDR_2 : 15|1@0+ (1,0) [0|1] ""  SRS
 SG_ VSA_ABS_ACT_EDR_2 : 0|1@0+ (1,0) [0|1] ""  SRS
 SG_ VSA_STABILITY_CTRL_ACT_EDR_2 : 1|1@0+ (1,0) [0|1] ""  SRS
 SG_ VSA_VSA_OFF_STATUS_EDR_2 : 7|1@0+ (1,0) [0|1] ""  SRS

BO_ 2564550641 HDS_18DBEFF1_CH2: 8 HDS
 SG_ HDS_HDC_CAN_2 : 7|64@0+ (1,0) [0|1.8446744074E+019] ""  VSA,NAVI,METER,ENG,CVT,AHU

BO_ 808 ENG_328_CH2: 8 ENG
 SG_ ENG_CHECKSUM_328_2 : 59|4@0+ (1,0) [0|15] ""  VSA,SMART,METER,EPS
 SG_ ENG_ALIVE_COUNTER_328_2 : 61|2@0+ (1,0) [0|3] ""  VSA,SMART,METER,EPS
 SG_ ENG_STRNNEND_2 : 47|1@0+ (1,0) [0|1] ""  VSA,SMART,METER,EPS

BO_ 804 ENG_324_CH2: 8 ENG
 SG_ ENG_ENG_COOLANT_TEMP_2 : 7|8@0+ (1,-40) [0|0] "" Vector__XXX
 SG_ ENG_EM_TEST_MODE_ENABLE_2 : 62|1@0+ (1,0) [0|1] "" Vector__XXX
 SG_ ENG_CHECKSUM_324_2 : 59|4@0+ (1,0) [0|15] ""  VSA,SS30,SRS,METER,FCM,EPS,ABS
 SG_ ENG_ALIVE_COUNTER_324_2 : 61|2@0+ (1,0) [0|3] ""  VSA,SS30,SRS,METER,FCM,EPS,ABS
 SG_ ENG_SW_STATUS_SCS_2 : 48|1@0+ (1,0) [0|1] ""  VSA,SS30,SRS,METER,EPS,ABS

BO_ 472 SS30_1D8_CH2: 3 SS30
 SG_ SS30_SYSTEM_ACT_2 : 3|1@0+ (1,0) [0|1] "" Vector__XXX
 SG_ SS30_CHECKSUM_1D8_2 : 19|4@0+ (1,0) [0|15] "" Vector__XXX
 SG_ SS30_ALIVE_COUNTER_1D8_2 : 21|2@0+ (1,0) [0|3] "" Vector__XXX
 SG_ SS30_TARGET_DECELERATION_2 : 2|11@0- (0.01,0) [-10.24|10.23] "m/s2" Vector__XXX
 SG_ SS30_REQ_PREBRAKE_2 : 4|1@0+ (1,0) [0|1] ""  VSA
 SG_ SS30_REQ_BRAKE_2 : 5|1@0+ (1,0) [0|1] ""  VSA
 SG_ SS30_REQ_BRAKEHOLD_2 : 6|1@0+ (1,0) [0|1] "" Vector__XXX
 SG_ SS30_STATUS_FAIL_2 : 7|1@0+ (1,0) [0|1] "" Vector__XXX

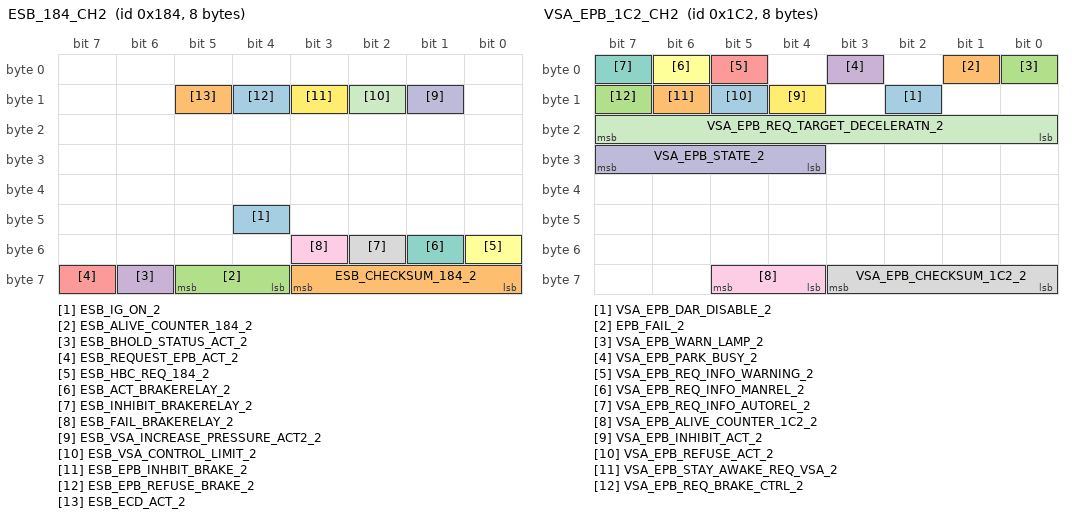
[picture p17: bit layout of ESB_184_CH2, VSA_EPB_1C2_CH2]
BO_ 388 ESB_184_CH2: 8 E4WD
 SG_ ESB_IG_ON_2 : 44|1@0+ (1,0) [0|1] "" Vector__XXX
 SG_ ESB_CHECKSUM_184_2 : 59|4@0+ (1,0) [0|15] ""  VSA
 SG_ ESB_ALIVE_COUNTER_184_2 : 61|2@0+ (1,0) [0|3] ""  VSA
 SG_ ESB_BHOLD_STATUS_ACT_2 : 62|1@0+ (1,0) [0|1] ""  VSA
 SG_ ESB_REQUEST_EPB_ACT_2 : 63|1@0+ (1,0) [0|1] ""  VSA
 SG_ ESB_HBC_REQ_184_2 : 48|1@0+ (1,0) [0|1] ""  VSA
 SG_ ESB_ACT_BRAKERELAY_2 : 49|1@0+ (1,0) [0|1] ""  VSA
 SG_ ESB_INHIBIT_BRAKERELAY_2 : 50|1@0+ (1,0) [0|1] ""  VSA
 SG_ ESB_FAIL_BRAKERELAY_2 : 51|1@0+ (1,0) [0|1] ""  VSA
 SG_ ESB_VSA_INCREASE_PRESSURE_ACT2_2 : 9|1@0+ (1,0) [0|1] ""  VSA
 SG_ ESB_VSA_CONTROL_LIMIT_2 : 10|1@0+ (1,0) [0|1] ""  VSA
 SG_ ESB_EPB_INHBIT_BRAKE_2 : 11|1@0+ (1,0) [0|1] ""  VSA
 SG_ ESB_EPB_REFUSE_BRAKE_2 : 12|1@0+ (1,0) [0|1] ""  VSA
 SG_ ESB_ECD_ACT_2 : 13|1@0+ (1,0) [0|1] ""  VSA

BO_ 450 VSA_EPB_1C2_CH2: 8 VSA
 SG_ VSA_EPB_DAR_DISABLE_2 : 10|1@0+ (1,0) [0|0] "" Vector__XXX
 SG_ EPB_FAIL_2 : 1|1@0+ (1,0) [0|0] "" Vector__XXX
 SG_ VSA_EPB_WARN_LAMP_2 : 0|1@0+ (1,0) [0|1] "" Vector__XXX
 SG_ VSA_EPB_PARK_BUSY_2 : 3|1@0+ (1,0) [0|1] "" Vector__XXX
 SG_ VSA_EPB_REQ_INFO_WARNING_2 : 5|1@0+ (1,0) [0|1] "" Vector__XXX
 SG_ VSA_EPB_REQ_INFO_MANREL_2 : 6|1@0+ (1,0) [0|1] "" Vector__XXX
 SG_ VSA_EPB_REQ_INFO_AUTOREL_2 : 7|1@0+ (1,0) [0|1] "" Vector__XXX
 SG_ VSA_EPB_CHECKSUM_1C2_2 : 59|4@0+ (1,0) [0|15] "" Vector__XXX
 SG_ VSA_EPB_ALIVE_COUNTER_1C2_2 : 61|2@0+ (1,0) [0|3] "" Vector__XXX
 SG_ VSA_EPB_STATE_2 : 31|4@0+ (1,0) [0|15] "" Vector__XXX
 SG_ VSA_EPB_REQ_TARGET_DECELERATN_2 : 23|8@0+ (0.03125,0) [0|7.96875] "m/s2" Vector__XXX
 SG_ VSA_EPB_INHIBIT_ACT_2 : 12|1@0+ (1,0) [0|1] "" Vector__XXX
 SG_ VSA_EPB_REFUSE_ACT_2 : 13|1@0+ (1,0) [0|1] "" Vector__XXX
 SG_ VSA_EPB_STAY_AWAKE_REQ_VSA_2 : 14|1@0+ (1,0) [0|1] "" Vector__XXX
 SG_ VSA_EPB_REQ_BRAKE_CTRL_2 : 15|1@0+ (1,0) [0|1] ""  EPB

BO_ 274 VSA_EPB_112_CH2: 3 VSA
 SG_ VSA_EPB_CLUTCH_PEDAL_STROKE_2 : 7|8@0+ (0.39215686275,0) [0|100] "%" Vector__XXX
 SG_ VSA_EPB_CLUTCH_PEDAL_FAIL_2 : 23|1@0+ (1,0) [0|1] ""  EPB
 SG_ VSA_EPB_CHECKSUM_112_2 : 19|4@0+ (1,0) [0|15] "" Vector__XXX
 SG_ VSA_EPB_ALIVE_COUNTER_112_2 : 21|2@0+ (1,0) [0|3] "" Vector__XXX

BO_ 356 METER_164_CH2: 8 METER
 SG_ METER_SW_STATUS_BHOLD_SENKOSYA_2 : 62|1@0+ (1,0) [0|1] "" Vector__XXX
 SG_ METER_CHECKSUM_164_2 : 59|4@0+ (1,0) [0|15] ""  VSA,SRS,ENG
 SG_ METER_ALIVE_COUNTER_164_2 : 61|2@0+ (1,0) [0|3] ""  VSA,SRS,ENG
 SG_ METER_SW_STATUS_PARK_BRAKE_2 : 2|1@0+ (1,0) [0|1] ""  VSA,SRS
 SG_ METER_SW_STATUS_BRAKE_FLUID_2 : 3|1@0+ (1,0) [0|1] ""  VSA
 SG_ METER_SW_STATUS_VSA_OFF_2 : 4|1@0+ (1,0) [0|1] ""  VSA

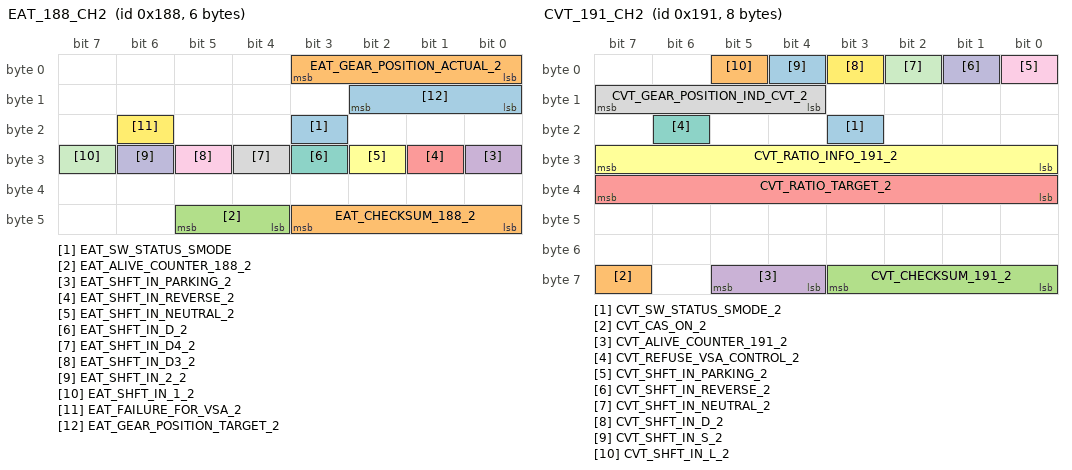
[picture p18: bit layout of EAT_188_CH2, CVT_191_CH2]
BO_ 392 EAT_188_CH2: 6 EAT
 SG_ EAT_SW_STATUS_SMODE : 19|1@0+ (1,0) [0|1] "" Vector__XXX
 SG_ EAT_CHECKSUM_188_2 : 43|4@0+ (1,0) [0|15] ""  VSA,RTC,PUH,METER,EPT2,EPT1,EPS,EPB,ASC,ACM,ACC
 SG_ EAT_ALIVE_COUNTER_188_2 : 45|2@0+ (1,0) [0|3] ""  VSA,RTC,PUH,METER,EPT2,EPT1,EPS,EPB,ASC,ACM,ACC
 SG_ EAT_SHFT_IN_PARKING_2 : 24|1@0+ (1,0) [0|1] ""  VSA,METER,EPS,EPB,ASC,ACM,ACC
 SG_ EAT_SHFT_IN_REVERSE_2 : 25|1@0+ (1,0) [0|1] ""  VSA,METER,EPB,ACM,ACC
 SG_ EAT_SHFT_IN_NEUTRAL_2 : 26|1@0+ (1,0) [0|1] ""  VSA,METER,EPS,EPB,ACM,ACC
 SG_ EAT_SHFT_IN_D_2 : 27|1@0+ (1,0) [0|1] ""  VSA,METER,EPB,ACM,ACC
 SG_ EAT_SHFT_IN_D4_2 : 28|1@0+ (1,0) [0|1] ""  VSA,EPB,ACM,ACC
 SG_ EAT_SHFT_IN_D3_2 : 29|1@0+ (1,0) [0|1] ""  VSA,EPB,ACM,ACC
 SG_ EAT_SHFT_IN_2_2 : 30|1@0+ (1,0) [0|1] ""  VSA,EPB,ACM,ACC
 SG_ EAT_SHFT_IN_1_2 : 31|1@0+ (1,0) [0|1] ""  VSA,EPB,ACM,ACC
 SG_ EAT_FAILURE_FOR_VSA_2 : 22|1@0+ (1,0) [0|1] ""  VSA
 SG_ EAT_GEAR_POSITION_TARGET_2 : 10|3@0+ (1,0) [0|7] ""  VSA,EPB
 SG_ EAT_GEAR_POSITION_ACTUAL_2 : 3|4@0+ (1,0) [0|15] ""  VSA,EPT2,EPT1,EPB,ASC,ACC

BO_ 401 CVT_191_CH2: 8 CVT
 SG_ CVT_SW_STATUS_SMODE_2 : 19|1@0+ (1,0) [0|1] "" Vector__XXX
 SG_ CVT_CAS_ON_2 : 63|1@0+ (1,0) [0|1] "" Vector__XXX
 SG_ CVT_CHECKSUM_191_2 : 59|4@0+ (1,0) [0|15] ""  VSA,METER,FCM,EPS
 SG_ CVT_ALIVE_COUNTER_191_2 : 61|2@0+ (1,0) [0|3] ""  VSA,METER,FCM,EPS
 SG_ CVT_RATIO_TARGET_2 : 39|8@0+ (0.015625,0) [0|3.984375] ""  VSA
 SG_ CVT_RATIO_INFO_191_2 : 31|8@0+ (0.015625,0) [0|3.984375] ""  VSA
 SG_ CVT_REFUSE_VSA_CONTROL_2 : 22|1@0+ (1,0) [0|1] ""  VSA
 SG_ CVT_GEAR_POSITION_IND_CVT_2 : 15|4@0+ (1,0) [0|15] ""  VSA,METER
 SG_ CVT_SHFT_IN_PARKING_2 : 0|1@0+ (1,0) [0|1] ""  VSA,METER,EPS
 SG_ CVT_SHFT_IN_REVERSE_2 : 1|1@0+ (1,0) [0|1] ""  VSA,METER
 SG_ CVT_SHFT_IN_NEUTRAL_2 : 2|1@0+ (1,0) [0|1] ""  VSA,METER
 SG_ CVT_SHFT_IN_D_2 : 3|1@0+ (1,0) [0|1] ""  VSA
 SG_ CVT_SHFT_IN_S_2 : 4|1@0+ (1,0) [0|1] ""  VSA,METER
 SG_ CVT_SHFT_IN_L_2 : 5|1@0+ (1,0) [0|1] ""  VSA,METER

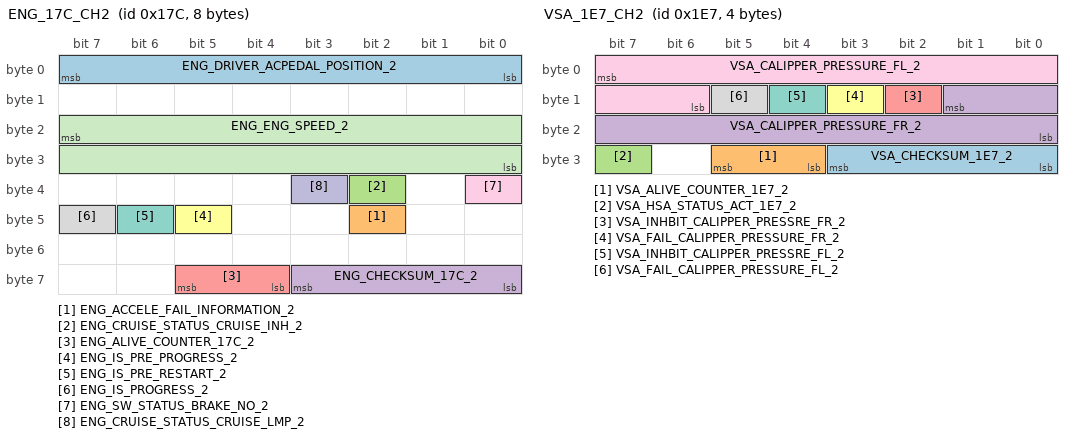
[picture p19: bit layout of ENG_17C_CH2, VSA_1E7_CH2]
BO_ 380 ENG_17C_CH2: 8 ENG
 SG_ ENG_DRIVER_ACPEDAL_POSITION_2 : 7|8@0+ (0.39215686275,0) [0|100] "%" Vector__XXX
 SG_ ENG_ACCELE_FAIL_INFORMATION_2 : 42|1@0+ (1,0) [0|1] "" Vector__XXX
 SG_ ENG_CRUISE_STATUS_CRUISE_INH_2 : 34|1@0+ (1,0) [0|1] "" Vector__XXX
 SG_ ENG_CHECKSUM_17C_2 : 59|4@0+ (1,0) [0|15] ""  VSA,SS30,SRS,SMART,METER,FCM,EPS
 SG_ ENG_ALIVE_COUNTER_17C_2 : 61|2@0+ (1,0) [0|3] ""  VSA,SS30,SRS,SMART,METER,FCM,EPS
 SG_ ENG_IS_PRE_PROGRESS_2 : 45|1@0+ (1,0) [0|1] ""  VSA,EPS
 SG_ ENG_IS_PRE_RESTART_2 : 46|1@0+ (1,0) [0|1] ""  VSA,SMART,METER,EPS
 SG_ ENG_IS_PROGRESS_2 : 47|1@0+ (1,0) [0|1] ""  VSA,SMART,METER,EPS
 SG_ ENG_SW_STATUS_BRAKE_NO_2 : 32|1@0+ (1,0) [0|1] ""  VSA,SRS,NAVI,AHU
 SG_ ENG_CRUISE_STATUS_CRUISE_LMP_2 : 35|1@0+ (1,0) [0|1] ""  VSA,METER
 SG_ ENG_ENG_SPEED_2 : 23|16@0+ (1,0) [0|15000] "rpm"  VSA,SRS,NAVI,EPS,AHU

BO_ 342 STR_156_CH2: 6 STR
 SG_ STR_TRIM_2 : 34|1@0+ (1,0) [0|1] "" Vector__XXX
 SG_ STR_CHECKSUM_156_2 : 43|4@0+ (1,0) [0|15] ""  VSA,SS30,SRS,METER,FCM,EPS
 SG_ STR_ALIVE_COUNTER_156_2 : 45|2@0+ (1,0) [0|3] ""  VSA,SS30,SRS,METER,FCM,EPS
 SG_ STR_OK_2 : 32|1@0+ (1,0) [0|1] ""  VSA,SS30,SRS,METER,EPS
 SG_ STR_CAL_2 : 33|1@0+ (1,0) [0|1] ""  VSA,SS30,METER,EPS
 SG_ STR_SPEED_2 : 23|16@0- (1,0) [-32768|32767] "deg/s"  VSA,SS30,METER,EPS
 SG_ STR_ANGLE_2 : 7|16@0- (0.1,0) [-3276.8|3276.7] "deg"  VSA,SS30,SRS,METER,EPS

BO_ 304 ENG_130_CH2: 8 ENG
 SG_ ENG_PP_DISABLE_2 : 43|1@0+ (1,0) [0|1] "" Vector__XXX
 SG_ ENG_PPTRQSTB_STANDBY_2 : 53|1@0+ (1,0) [0|1] "" Vector__XXX
 SG_ ENG_CLUTCH_SW_SIL_2 : 51|1@0+ (1,0) [0|1] "" Vector__XXX
 SG_ ENG_EV_DRIVE_STATE_2 : 55|1@0+ (1,0) [0|1] "" Vector__XXX
 SG_ ENG_BRK_ACCELE_PEDAL_ON_2 : 44|1@0+ (1,0) [0|1] "" Vector__XXX
 SG_ ENG_SHFT_IN_REVERSE_2 : 49|1@0+ (1,0) [0|1] "" Vector__XXX
 SG_ ENG_CHECKSUM_130_2 : 59|4@0+ (1,0) [0|15] ""  VSA,SRS,EPS
 SG_ ENG_ALIVE_COUNTER_130_2 : 61|2@0+ (1,0) [0|3] ""  VSA,SRS,EPS
 SG_ ENG_NEUTRAL_SENSOR_FAIL_2 : 62|1@0+ (1,0) [0|1] ""  VSA
 SG_ ENG_RECEIVE_ERROR_1AC_2 : 63|1@0+ (1,0) [0|1] ""  VSA
 SG_ ENG_SHFT_IN_NEUTRAL_2 : 48|1@0+ (1,0) [0|1] ""  VSA,EPS
 SG_ ENG_CLUTCH_SW_CC_2 : 50|1@0+ (1,0) [0|1] ""  VSA
 SG_ ENG_VSA_ACK1_2 : 41|2@0+ (1,0) [0|15] ""  VSA
 SG_ ENG_VSA_PERMIT_PLUS_TRQ_2 : 45|1@0+ (1,0) [0|1] ""  VSA
 SG_ ENG_VSA_INHIBIT_VSA_CONTROL_1_2 : 46|1@0+ (1,0) [0|1] ""  VSA
 SG_ ENG_VSA_REFUSED_VSA_CONTROL_1_2 : 47|1@0+ (1,0) [0|1] ""  VSA
 SG_ ENG_SMART_ACCELE_PEDAL_POS_2 : 39|8@0+ (0.39215686275,0) [0|100] "%"  VSA,SRS
 SG_ ENG_DRIVER_REQ_TRQ_130_2 : 23|16@0- (1,0) [-32768|32767] "Nm"  VSA
 SG_ ENG_ENG_TRQ_130_2 : 7|16@0- (1,0) [-32768|32767] "Nm"  VSA

BO_ 545 METER_221_CH2: 6 METER
 SG_ METER_ECONSW_ON_2 : 23|1@0+ (1,0) [0|1] "" Vector__XXX
 SG_ METER_SW_STATUS_MODE_2 : 39|4@0+ (1,0) [0|15] ""  VSA
 SG_ METER_CHECKSUM_221_2 : 43|4@0+ (1,0) [0|15] ""  VSA
 SG_ METER_ALIVE_COUNTER_221_2 : 45|2@0+ (1,0) [0|3] ""  VSA

BO_ 578 E4WD_242_CH2: 2 E4WD
 SG_ E4WD_REAR_DISTRIBUTION_242_2 : 7|4@0+ (1,0) [0|15] "Nm"  E4WD
 SG_ E4WD_CHECKSUM_242_2 : 11|4@0+ (1,0) [0|15] "" Vector__XXX
 SG_ E4WD_ALIVE_COUNTER_242_2 : 13|2@0+ (1,0) [0|3] ""  VSA

BO_ 1934 VSA_78E_CH2: 8 VSA
 SG_ VSA_CHECKSUM_78E_2 : 59|4@0+ (1,0) [0|15] ""  STR
 SG_ VSA_ALIVE_COUNTER_78E_2 : 61|2@0+ (1,0) [0|3] ""  STR
 SG_ VSA_COMMAND_CODE_2 : 7|8@0+ (1,0) [0|255] ""  STR

BO_ 476 ENG_1DC_CH2: 5 ENG
 SG_ ENG_CHECKSUM_1DC_2 : 35|4@0+ (1,0) [0|0] "" Vector__XXX
 SG_ ENG_ALIVE_COUNTER_1DC_2 : 37|2@0+ (1,0) [0|0] "" Vector__XXX
 SG_ ENG_IDS_MODE_TARGET_2 : 27|4@0+ (1,0) [0|0] "" Vector__XXX
 SG_ ENG_IDS_MODE_CONTROL_2 : 31|4@0+ (1,0) [0|0] ""  VSA

BO_ 1030 VSA_406_CH2: 5 VSA
 SG_ VSA_CHECKSUM_406_2 : 35|4@0+ (1,0) [0|15] "" Vector__XXX
 SG_ VSA_ALIVE_COUNTER_406_2 : 37|2@0+ (1,0) [0|3] "" Vector__XXX
 SG_ VSA_SPECIFY_CODE_SYS_2 : 24|1@0+ (1,0) [0|1] "" Vector__XXX
 SG_ VSA_DTC_STORAGE_2 : 25|1@0+ (1,0) [0|1] "" Vector__XXX
 SG_ VSA_DTC_LOW_2 : 15|8@0+ (1,0) [0|255] ""  NAVI,AHU
 SG_ VSA_DTC_HIGH_2 : 7|8@0+ (1,0) [0|255] ""  NAVI,AHU

BO_ 597 VSA_255_CH2: 8 VSA
 SG_ VSA_ABS_CHECKSUM_255_2 : 63|8@0+ (1,0) [0|255] ""  SMART,METER
 SG_ VSA_ABS_ALIVE_COUNTER_255_2 : 55|8@0+ (1,0) [0|255] ""  SMART,METER
 SG_ VSA_ABS_SPEED_FIXED_NUMBER2_2 : 47|8@0+ (1,0) [0|255] ""  SMART,METER
 SG_ VSA_ABS_SPEED_FIXED_NUMBER1_2 : 39|8@0+ (1,0) [0|255] ""  SMART,METER
 SG_ VSA_ABS_RR_WHEEL_SPEED_255_2 : 31|8@0+ (1,0) [0|255] "km/h"  SMART,METER
 SG_ VSA_ABS_RL_WHEEL_SPEED_255_2 : 23|8@0+ (1,0) [0|255] "km/h"  SMART,METER
 SG_ VSA_ABS_FR_WHEEL_SPEED_255_2 : 15|8@0+ (1,0) [0|255] "km/h"  SMART,METER
 SG_ VSA_ABS_FL_WHEEL_SPEED_255_2 : 7|8@0+ (1,0) [0|255] "km/h"  SMART,METER,ENG

BO_ 490 VSA_1EA_CH2: 8 VSA
 SG_ VSA_CHECKSUM_1EA_2 : 59|4@0+ (1,0) [0|15] ""  EPS
 SG_ VSA_ALIVE_COUNTER_1EA_2 : 61|2@0+ (1,0) [0|3] ""  EPS
 SG_ VSA_MAEPS_REVERSE_F_2 : 48|1@0+ (1,0) [0|1] ""  EPS
 SG_ VSA_SYSTEM_F_2 : 50|1@0+ (1,0) [0|1] ""  EPS
 SG_ VSA_MAEPS_MYU_VALUE_2 : 39|16@0- (3.90625E-005,0) [-1.28|1.2799609375] ""  EPS
 SG_ VSA_MAEPS_GX_VALUE_2 : 23|16@0- (0.00015258789063,0) [-5|4.9998474121] "G"  EPS
 SG_ VSA_MAEPS_US_VALUE_2 : 7|16@0- (0.0038146972656,0) [-125|124.9961853] "deg/s"  EPS

BO_ 334 E4WD_14E_CH2: 8 E4WD
 SG_ E4WD_ERROR_STATUS_14E_2 : 35|1@0+ (1,0) [0|1] ""  VSA
 SG_ E4WD_CHECKSUM_14E_2 : 59|4@0+ (1,0) [0|15] ""  VSA
 SG_ E4WD_ALIVECOUNTER_14E_2 : 61|2@0+ (1,0) [0|3] ""  VSA
 SG_ E4WD_MDTR_2 : 15|8@0+ (10,0) [0|2550] "Nm"  VSA
 SG_ E4WD_MDTL_2 : 7|8@0+ (10,0) [0|2550] "Nm"  VSA

BO_ 1029 METER_405_CH2: 8 METER
 SG_ METER_CHECKSUM_405_2 : 59|4@0+ (1,0) [0|15] ""  VSA,NAVI,ANC
 SG_ METER_ALIVE_COUNTER_405_2 : 61|2@0+ (1,0) [0|3] ""  VSA,NAVI,ANC
 SG_ METER_WARN_STATUS_TIRE_PRESS_2 : 12|1@0+ (1,0) [0|1] ""  VSA,NAVI
 SG_ METER_WARN_STATUS_TPMS_SYSTEM_2 : 13|1@0+ (1,0) [0|1] ""  VSA,NAVI

BO_ 819 TPMS_333_CH2: 7 TPMS
 SG_ TPMS_WARN_STATUS_ISO_2 : 0|1@0+ (1,0) [0|1] "" Vector__XXX
 SG_ TPMS_WARN_STATUS_SYSTEM_2 : 1|1@0+ (1,0) [0|1] "" Vector__XXX
 SG_ TPMS_ALIVE_COUNTER_333_2 : 53|2@0+ (1,0) [0|0] "" Vector__XXX
 SG_ TPMS_CHECKSUM_333_2 : 51|4@0+ (1,0) [0|0] ""  VSA

BO_ 487 VSA_1E7_CH2: 4 VSA
 SG_ VSA_CHECKSUM_1E7_2 : 27|4@0+ (1,0) [0|15] "" Vector__XXX
 SG_ VSA_ALIVE_COUNTER_1E7_2 : 29|2@0+ (1,0) [0|3] "" Vector__XXX
 SG_ VSA_HSA_STATUS_ACT_1E7_2 : 31|1@0+ (1,0) [0|1] "" Vector__XXX
 SG_ VSA_CALIPPER_PRESSURE_FR_2 : 9|10@0+ (23.96,-2443.92) [-2443.92|22067.16] "kPa" Vector__XXX
 SG_ VSA_INHBIT_CALIPPER_PRESSRE_FR_2 : 10|1@0+ (1,0) [0|1] "" Vector__XXX
 SG_ VSA_FAIL_CALIPPER_PRESSURE_FR_2 : 11|1@0+ (1,0) [0|1] "" Vector__XXX
 SG_ VSA_INHBIT_CALIPPER_PRESSRE_FL_2 : 12|1@0+ (1,0) [0|1] "" Vector__XXX
 SG_ VSA_FAIL_CALIPPER_PRESSURE_FL_2 : 13|1@0+ (1,0) [0|1] "" Vector__XXX
 SG_ VSA_CALIPPER_PRESSURE_FL_2 : 7|10@0+ (23.96,-2443.92) [-2443.92|22067.16] "kPa"  ABS

BO_ 464 VSA_1D0_CH2: 8 VSA
 SG_ VSA_ABS_CHECKSUM_1D0_2 : 59|4@0+ (1,0) [0|15] ""  SS30,EPS,ENG,CVT
 SG_ VSA_ABS_RR_WHEEL_SPEED_2 : 42|15@0+ (0.01,0) [0|327.67] "km/h"  SS30,EPS,ENG,CVT
 SG_ VSA_ABS_RL_WHEEL_SPEED_2 : 25|15@0+ (0.01,0) [0|327.67] "km/h"  SS30,EPS,ENG,CVT
 SG_ VSA_ABS_FR_WHEEL_SPEED_2 : 8|15@0+ (0.01,0) [0|327.67] "km/h"  SS30,EPS,ENG,CVT
 SG_ VSA_ABS_FL_WHEEL_SPEED_2 : 7|15@0+ (0.01,0) [0|327.67] "km/h"  SS30,EPS,ENG,CVT

BO_ 432 VSA_1B0_CH2: 7 VSA
 SG_ VSA_PLANT_INSPECTION_STATUS_2 : 25|1@0+ (1,0) [0|1] "" Vector__XXX
 SG_ VSA_INHIBIT_BRKRELAY_FOR_CMBS_2 : 16|1@0+ (1,0) [0|1] "" Vector__XXX
 SG_ VSA_BRKPAD_TEMP_CALC_FAIL_1B0_2 : 19|1@0+ (1,0) [0|1] "" Vector__XXX
 SG_ VSA_BRKPAD_TEMP_STATE_STOP_1B0_2 : 20|1@0+ (1,0) [0|1] "" Vector__XXX
 SG_ VSA_BRKPAD_TEMP_STATE_WAIT_1B0_2 : 21|1@0+ (1,0) [0|1] "" Vector__XXX
 SG_ VSA_BRKPAD_TEMP_CALC_INH_1B0_2 : 18|1@0+ (1,0) [0|1] "" Vector__XXX
 SG_ VSA_ABS_BUSY_2 : 55|1@0+ (1,0) [0|1] "" Vector__XXX
 SG_ VSA_EPT_COMFORT_TRIG_2 : 22|1@0+ (1,0) [0|1] "" Vector__XXX
 SG_ VSA_EPT_PRECRASH_TRIG_2 : 23|1@0+ (1,0) [0|1] "" Vector__XXX
 SG_ VSA_ABS_ENB_VW_SENSOR_ACT_2 : 54|1@0+ (1,0) [0|1] "" Vector__XXX
 SG_ VSA_INHBIT_LONG_G_SENSOR_2 : 2|1@0+ (1,0) [0|1] "" Vector__XXX
 SG_ VSA_FAIL_LONG_G_SENSOR_2 : 4|1@0+ (1,0) [0|1] "" Vector__XXX
 SG_ VSA_ACC_REFUSE_ACC_BRAKE_2 : 9|1@0+ (1,0) [0|1] "" Vector__XXX
 SG_ VSA_ACC_INHIBIT_ACC_BRAKE_2 : 8|1@0+ (1,0) [0|1] "" Vector__XXX
 SG_ VSA_ABS_VW_SENSOR_START_UP_2 : 15|1@0+ (1,0) [0|1] "" Vector__XXX
 SG_ VSA_INHIBIT_BRAKERELAY_2 : 5|1@0+ (1,0) [0|1] "" Vector__XXX
 SG_ VSA_INHBIT_LAT_G_SENSOR_2 : 1|1@0+ (1,0) [0|1] "" Vector__XXX
 SG_ VSA_FAIL_LAT_G_SENSOR_2 : 3|1@0+ (1,0) [0|1] "" Vector__XXX
 SG_ VSA_ACT_BRAKERELAY_2 : 0|1@0+ (1,0) [0|1] "" Vector__XXX
 SG_ VSA_CHECKSUM_1B0_2 : 51|4@0+ (1,0) [0|15] ""  SS30,METER,FCM,EPS,CVT
 SG_ VSA_ALIVE_COUNTER_1B0_2 : 53|2@0+ (1,0) [0|3] ""  SS30,METER,FCM,EPS,CVT
 SG_ VSA_REQ_CVT_TCS_2 : 40|1@0+ (1,0) [0|1] ""  CVT
 SG_ VSA_REQ_CVT_PRS_2 : 41|1@0+ (1,0) [0|1] ""  CVT
 SG_ VSA_CONTROL_MODE_CVT_2 : 43|2@0+ (1,0) [0|3] ""  CVT
 SG_ VSA_ABS_STATUS_FR_ABS_EBD_ACT_2 : 44|1@0+ (1,0) [0|1] "" Vector__XXX
 SG_ VSA_ABS_STATUS_FL_ABS_EBD_ACT_2 : 45|1@0+ (1,0) [0|1] "" Vector__XXX
 SG_ VSA_ABS_STATUS_RR_ABS_EBD_ACT_2 : 46|1@0+ (1,0) [0|1] "" Vector__XXX
 SG_ VSA_ABS_STATUS_RL_ABS_EBD_ACT_2 : 47|1@0+ (1,0) [0|1] "" Vector__XXX
 SG_ VSA_FAIL_STEERING_SENSOR_2 : 32|1@0+ (1,0) [0|1] "" Vector__XXX
 SG_ VSA_FAIL_YAW_RATE_SENSOR_2 : 33|1@0+ (1,0) [0|1] ""  SS30
 SG_ VSA_FAIL_MC_PRESSRE_SENSOR_1B0_2 : 34|1@0+ (1,0) [0|1] "" Vector__XXX
 SG_ VSA_ABS_FAIL_FR_VW_SENSOR_2 : 35|1@0+ (1,0) [0|1] ""  SS30,EPS,CVT
 SG_ VSA_ABS_FAIL_FL_VW_SENSOR_2 : 36|1@0+ (1,0) [0|1] ""  SS30,EPS,CVT
 SG_ VSA_ABS_FAIL_RR_VW_SENSOR_2 : 37|1@0+ (1,0) [0|1] ""  SS30,EPS,CVT
 SG_ VSA_ABS_FAIL_RL_VW_SENSOR_2 : 38|1@0+ (1,0) [0|1] ""  SS30,EPS,CVT
 SG_ VSA_ABS_INHBIT_VW_SENSOR_2 : 39|1@0+ (1,0) [0|1] ""  SS30,EPS
 SG_ VSA_ACC_INHIBIT_CVRS_BRAKE_2 : 10|1@0+ (1,0) [0|1] ""  SS30
 SG_ VSA_INHBIT_STEERING_SENSOR_2 : 13|1@0+ (1,0) [0|1] "" Vector__XXX
 SG_ VSA_ACC_REFUSE_CVRS_BRAKE_2 : 11|1@0+ (1,0) [0|1] ""  SS30
 SG_ VSA_VW_PULSE_CAPTURED_2 : 12|1@0+ (1,0) [0|1] ""  SS30
 SG_ VSA_INHBIT_YAW_RATE_SENSOR_2 : 14|1@0+ (1,0) [0|1] "-"  SS30
 SG_ VSA_FAIL_BRAKERELAY_2 : 6|1@0+ (1,0) [0|1] ""  SS30
 SG_ VSA_SS30_BRAKE_ACT_2 : 7|1@0+ (1,0) [0|1] ""  SS30

BO_ 150 VSA_096_CH2: 8 VSA
 SG_ VSA_CHECKSUM_096_2 : 59|4@0+ (1,0) [0|15] "" Vector__XXX
 SG_ VSA_ALIVE_COUNTER_096_2 : 61|2@0+ (1,0) [0|3] "" Vector__XXX
 SG_ VSA_YAW_2_2 : 7|10@0+ (0.244140625,-125) [0|922] "deg/sec"  STR

BO_ 428 VSA_1AC_CH2: 8 VSA
 SG_ VSA_BTCS_ACT_1AC_2 : 53|1@0+ (1,0) [0|1] "-" Vector__XXX
 SG_ VSA_IDS_TEMP_INHIBIT_2 : 54|1@0+ (1,0) [0|1] "" Vector__XXX
 SG_ VSA_IG_ON_2 : 55|1@0+ (1,0) [0|1] "" Vector__XXX
 SG_ VSA_EBB_FAILURE_FOR_IS_2 : 41|1@0+ (1,0) [0|1] "" Vector__XXX
 SG_ VSA_IDS_INHIBIT_DISABLED_STATE_2 : 44|1@0+ (1,0) [0|1] "" Vector__XXX
 SG_ VSA_IDS_INHIBIT_ACT_2 : 45|1@0+ (1,0) [0|1] "" Vector__XXX
 SG_ VSA_HAC_CUT_REQ_2 : 32|1@0+ (1,0) [0|1] "" Vector__XXX
 SG_ VSA_HBB_IS_REFUSE_REQ_2 : 33|1@0+ (1,0) [0|1] "" Vector__XXX
 SG_ VSA_LOW_VAC_IS_SHFT_INHBIT_REQ_2 : 34|1@0+ (1,0) [0|1] "" Vector__XXX
 SG_ VSA_MNTMODE_STATUS_2 : 24|1@0+ (1,0) [0|1] "" Vector__XXX
 SG_ VSA_REVERSE_SWITCH_FAIL_2 : 25|1@0+ (1,0) [0|1] "" Vector__XXX
 SG_ VSA_SHFT_IN_REVERSE_2 : 26|1@0+ (1,0) [0|1] "" Vector__XXX
 SG_ VSA_ECD_ACT_2 : 27|1@0+ (1,0) [0|1] "" Vector__XXX
 SG_ VSA_FAIL_FOR_EPB_2 : 28|1@0+ (1,0) [0|1] "" Vector__XXX
 SG_ VSA_REQUEST_EPB_ACT_2 : 29|1@0+ (1,0) [0|1] "" Vector__XXX
 SG_ VSA_EPB_INHIBIT_BRAKE_2 : 30|1@0+ (1,0) [0|1] "" Vector__XXX
 SG_ VSA_HBB_IS_SHIFT_INHIBIT_REQ_2 : 35|1@0+ (1,0) [0|1] "" Vector__XXX
 SG_ VSA_EPB_REFUSE_BRAKE_2 : 31|1@0+ (1,0) [0|1] "" Vector__XXX
 SG_ VSA_TSA_ACT_2 : 63|1@0+ (1,0) [0|1] "" Vector__XXX
 SG_ VSA_ISAB_ACT_2 : 42|1@0+ (1,0) [0|1] "" Vector__XXX
 SG_ VSA_IS_RESTART_INHIBIT_REQUEST_2 : 46|1@0+ (1,0) [0|1] "" Vector__XXX
 SG_ VSA_ISAB_ENABLE_2 : 43|1@0+ (1,0) [0|1] "" Vector__XXX
 SG_ VSA_IS_SHIFT_INHIBIT_REQUEST_1_2 : 47|1@0+ (1,0) [0|1] "" Vector__XXX
 SG_ VSA_SHIFT_REQ_1AC_2 : 19|2@0+ (1,0) [0|3] ""  EPB,ENG
 SG_ VSA_ALIVE_COUNTER_1AC_2 : 61|2@0+ (1,0) [0|3] "" Vector__XXX
 SG_ VSA_CHECKSUM_1AC_2 : 59|4@0+ (1,0) [0|15] "" Vector__XXX
 SG_ VSA_REQ_TRQ_1AC_2 : 7|16@0- (1,0) [-32768|32767] "Nm" Vector__XXX
 SG_ VSA_REQ_MSR_PLUS_TRQ_2 : 62|1@0+ (1,0) [0|1] "" Vector__XXX
 SG_ VSA_TRQ_CONTROL_MODE_2 : 17|2@0+ (1,0) [0|3] "" Vector__XXX
 SG_ VSA_TRQ_DOWN_REQ_FUEL_CUT_2 : 23|4@0+ (1,0) [0|15] "" Vector__XXX

BO_ 420 VSA_1A4_CH2: 8 VSA
 SG_ VSA_VSA_OS_CTRL_2 : 54|1@0+ (1,0) [0|1] "" Vector__XXX
 SG_ VSA_ESB_INCREASE_PRESS_ACT_2 : 55|1@0+ (1,0) [0|1] "" Vector__XXX
 SG_ VSA_WARN_STATUS_BHOLD_2 : 47|1@0+ (1,0) [0|0] "" Vector__XXX
 SG_ VSA_MID_REQ_BHOLD_STANDBY_2 : 41|1@0+ (1,0) [0|0] "" Vector__XXX
 SG_ VSA_MID_REQ_BHOLD_MISOP_GUIDE_2 : 43|2@0+ (1,0) [0|3] "" Vector__XXX
 SG_ VSA_MID_REQ_BHOLD_EPB_OP_INFO_2 : 44|1@0+ (1,0) [0|0] "" Vector__XXX
 SG_ VSA_MID_REQ_BHOLD_APPLY_BRAKE_2 : 40|1@0+ (1,0) [0|0] "" Vector__XXX
 SG_ VSA_LAMP_STATUS_VSA_OFF_TFT_2 : 33|1@0+ (1,0) [0|1] "" Vector__XXX
 SG_ VSA_WARN_STATUS_BRAKESYSTEM_2 : 36|1@0+ (1,0) [0|1] "" Vector__XXX
 SG_ VSA_LAMP_BHOLD_APPLY_BRAKE_2 : 53|1@0+ (1,0) [0|0] "" Vector__XXX
 SG_ VSA_BHOLD_STATUS_ACT_2 : 52|1@0+ (1,0) [0|0] "" Vector__XXX
 SG_ VSA_LAMP_STATUS_HDC_2 : 37|1@0+ (1,0) [0|1] "" Vector__XXX
 SG_ VSA_WARN_STATUS_HDC_2 : 38|1@0+ (1,0) [0|1] "" Vector__XXX
 SG_ VSA_LAMP_STATUS_OPERATE_BHOLD_2 : 46|1@0+ (1,0) [0|0] "" Vector__XXX
 SG_ VSA_LAMP_STATUS_STANBY_BHOLD_2 : 45|1@0+ (1,0) [0|0] "" Vector__XXX
 SG_ VSA_AHA_CTRL_2 : 39|1@0+ (1,0) [0|1] "" Vector__XXX
 SG_ VSA_ACC_BRAKE_ACT_2 : 23|1@0+ (1,0) [0|1] "" Vector__XXX
 SG_ VSA_WARN_STATUS_PUNCTURE_2 : 25|1@0+ (1,0) [0|1] "" Vector__XXX
 SG_ VSA_WARN_STATUS_DWS_2 : 26|1@0+ (1,0) [0|1] "" Vector__XXX
 SG_ VSA_ANSWER_DWS_INIT_REQ_2 : 24|1@0+ (1,0) [0|1] "" Vector__XXX
 SG_ VSA_L_MODE_ABS_EBD_2 : 32|1@0+ (1,0) [0|1] "" Vector__XXX
 SG_ VSA_CHECKSUM_1A4_2 : 59|4@0+ (1,0) [0|15] ""  SS30,SMART,METER,FCM,EPS,ENG,CVT
 SG_ VSA_ALIVE_COUNTER_1A4_2 : 61|2@0+ (1,0) [0|3] ""  SS30,SMART,METER,FCM,EPS,ENG,CVT
 SG_ VSA_ABS_CTRL_2 : 62|1@0+ (1,0) [0|1] ""  SS30
 SG_ VSA_VSA_CTRL_2 : 63|1@0+ (1,0) [0|1] ""  SS30
 SG_ VSA_WARN_STATUS_HSA_2 : 48|1@0+ (1,0) [0|1] ""  METER
 SG_ VSA_HSA_STATUS_ACT_2 : 49|1@0+ (1,0) [0|1] "" Vector__XXX
 SG_ VSA_ESS_ACT4_2 : 50|1@0+ (1,0) [0|1] ""  METER
 SG_ VSA_ESS_ACT3_2 : 51|1@0+ (1,0) [0|1] ""  METER
 SG_ VSA_REWRITE_START_2 : 34|1@0+ (1,0) [0|1] ""  SMART,EPS
 SG_ VSA_BUZZER_STATUS_2 : 35|1@0+ (1,0) [0|1] ""  METER
 SG_ VSA_MID_REQUEST_VSA_2 : 27|1@0+ (1,0) [0|1] ""  METER
 SG_ VSA_LAMP_STATUS_VSA_OFF_2 : 28|1@0+ (1,0) [0|1] ""  METER
 SG_ VSA_WARN_STATUS_VSA_2 : 29|1@0+ (1,0) [0|1] ""  METER
 SG_ VSA_WARN_STATUS_ABS_2 : 30|1@0+ (1,0) [0|1] ""  METER,ENG,CVT
 SG_ VSA_WARN_STATUS_BRAKE_2 : 31|1@0+ (1,0) [0|1] ""  METER
 SG_ VSA_VSA_TCS_ACT_2 : 16|1@0+ (1,0) [0|1] ""  NAVI,EPS,ENG,CVT,AHU
 SG_ VSA_ABS_EBD_ACT_2 : 17|1@0+ (1,0) [0|1] ""  NAVI,EPS,CVT,AHU
 SG_ VSA_VSA_TCS_MIL_2 : 18|1@0+ (1,0) [0|1] "" Vector__XXX
 SG_ VSA_ABS_EBD_MIL_2 : 19|1@0+ (1,0) [0|1] ""  SS30,ENG
 SG_ VSA_CASEN_2 : 20|1@0+ (1,0) [0|1] ""  CVT
 SG_ VSA_CAS_ACT_2 : 21|1@0+ (1,0) [0|1] ""  CVT
 SG_ VSA_BA_ACT_2 : 22|1@0+ (1,0) [0|1] ""  SS30
 SG_ VSA_MASTER_CYLINDER_PRESSURE_2 : 3|12@0+ (23.96,-2443.92) [-2443.92|95672.28] "kPa"  SS30,ENG
 SG_ VSA_FAIL_MC_PRESSURE_SENSOR_1_2 : 4|1@0+ (1,0) [0|1] ""  SS30,ENG
 SG_ VSA_INHBIT_MC_PRESSURE_SENSOR_2 : 5|1@0+ (1,0) [0|1] ""  SS30,ENG
 SG_ VSA_ESS_ACT2_2 : 6|1@0+ (1,0) [0|1] ""  METER
 SG_ VSA_ESS_ACT1_2 : 7|1@0+ (1,0) [0|1] ""  METER

BO_ 411 VSA_19B_CH2: 5 VSA
 SG_ VSA_CHECKSUM_19B_2 : 35|4@0+ (1,0) [0|15] "" Vector__XXX
 SG_ VSA_ALIVE_COUNTER_19B_2 : 37|2@0+ (1,0) [0|3] "" Vector__XXX
 SG_ VSA_ABS_RR_WHEEL_PULSE_COUNTER_2 : 31|8@0+ (1,0) [0|255] "" Vector__XXX
 SG_ VSA_ABS_RL_WHEEL_PULSE_COUNTER_2 : 23|8@0+ (1,0) [0|255] "" Vector__XXX
 SG_ VSA_ABS_FR_WHEEL_PULSE_COUNTER_2 : 15|8@0+ (1,0) [0|255] "" Vector__XXX
 SG_ VSA_ABS_FL_WHEEL_PULSE_COUNTER_2 : 7|8@0+ (1,0) [0|255] ""  ABS

BO_ 145 VSA_091_CH2: 8 VSA
 SG_ VSA_CHECKSUM_091_2 : 59|4@0+ (1,0) [0|15] ""  SS30,FCM,EPS,CVT
 SG_ VSA_ALIVE_COUNTER_091_2 : 61|2@0+ (1,0) [0|3] ""  SS30,FCM,EPS,CVT
 SG_ VSA_SENSOR_START_UP_2 : 63|1@0+ (1,0) [0|1] ""  SS30,EPS,CVT
 SG_ VSA_SENSOR_ERR_MC_2 : 48|1@0+ (1,0) [0|1] ""  EPS,CVT
 SG_ VSA_SENSOR_STATE_IG_2 : 49|1@0+ (1,0) [0|1] ""  EPS,CVT
 SG_ VSA_P_ERR_LON_G_2 : 52|1@0+ (1,0) [0|1] ""  CVT
 SG_ VSA_P_ERR_LAT_G_2 : 53|1@0+ (1,0) [0|1] ""  EPS
 SG_ VSA_P_ERR_DEGC_2 : 54|1@0+ (1,0) [0|1] "" Vector__XXX
 SG_ VSA_P_ERR_YAW1_2 : 55|1@0+ (1,0) [0|1] ""  EPS
 SG_ VSA_T_ERR_LON_G_2 : 44|1@0+ (1,0) [0|1] ""  CVT
 SG_ VSA_T_ERR_LAT_G_2 : 45|1@0+ (1,0) [0|1] ""  EPS
 SG_ VSA_T_ERR_DEGC_2 : 46|1@0+ (1,0) [0|1] "" Vector__XXX
 SG_ VSA_T_ERR_YAW1_2 : 47|1@0+ (1,0) [0|1] ""  EPS
 SG_ VSA_LON_G_2 : 25|10@0+ (0.047851563,-24.5) [-17.66|17.66] "m/sec^2"  CVT
 SG_ VSA_LAT_G_2 : 19|10@0+ (0.047851563,-24.5) [-17.66|17.66] "m/sec^2"  SS30,EPS
 SG_ VSA_DEGC_2 : 13|8@0+ (1,-103) [-40|125] "" Vector__XXX
 SG_ VSA_YAW_1_2 : 7|10@0+ (0.244140625,-125) [-100.1|100.1] "deg/sec"  SS30,EPS

CM_ BO_ 3221225472 "This is a message for not used signals, created by Vector CANdb++ DBC OLE DB Provider.";
CM_ SG_ 795 VSA_SYSTEM_STATUS_2 "VSA function valid / invalid notification in response to VSA OFF switch ON / OFF request.";
CM_ SG_ 795 VSA_DWS_AUTOJUDGE_2 "DWS/iDWS function application flag for meter autovariant";
CM_ SG_ 884 METER_STRG_SW_PUSH_FOR_VSA_OFF_2 "Steering switch push signal";
BA_DEF_ SG_  "ValueTableE" STRING ;
BA_DEF_ SG_  "DescriptionE" STRING ;
BA_DEF_ SG_  "DescriptionJ" STRING ;
BA_DEF_ SG_  "GenSigStartValue" INT 0 3000;
BA_DEF_ BO_  "PS" ENUM  "+B","ACC","IG1","IG2","*","vector_leerstring";
BA_DEF_ BO_  "FrameType" INT 0 2;
BA_DEF_ SG_  "GenSigSendType" ENUM  "Cyclic","OnWrite","OnWriteWithRepetition","OnChange","OnChangeWithRepetition","IfActive","IfActiveWithRepetition","NoSigSendType";
BA_DEF_ SG_  "GenSigInactiveValue" INT 0 0;
BA_DEF_ BO_  "GenMsgCycleTime" INT 0 0;
BA_DEF_ BO_  "GenMsgSendType" ENUM  "Cyclic","not_used","not_used","not_used","not_used","Cyclic","not_used","IfActive","NoMsgSendType";
BA_DEF_  "DBName" STRING ;
BA_DEF_  "BusType" STRING ;
BA_DEF_DEF_  "ValueTableE" "";
BA_DEF_DEF_  "DescriptionE" "";
BA_DEF_DEF_  "DescriptionJ" "";
BA_DEF_DEF_  "GenSigStartValue" 0;
BA_DEF_DEF_  "PS" "";
BA_DEF_DEF_  "FrameType" 2;
BA_DEF_DEF_  "GenSigSendType" "Cyclic";
BA_DEF_DEF_  "GenSigInactiveValue" 0;
BA_DEF_DEF_  "GenMsgCycleTime" 0;
BA_DEF_DEF_  "GenMsgSendType" "NoMsgSendType";
BA_DEF_DEF_  "DBName" "";
BA_DEF_DEF_  "BusType" "CAN";
BA_ "DBName" "Honda";
BA_ "GenMsgCycleTime" BO_ 524 20;
BA_ "GenMsgSendType" BO_ 524 0;
BA_ "GenMsgSendType" BO_ 94 0;
BA_ "GenMsgCycleTime" BO_ 94 10;
BA_ "GenMsgCycleTime" BO_ 93 10;
BA_ "GenMsgSendType" BO_ 93 0;
BA_ "GenMsgSendType" BO_ 2588256839 0;
BA_ "GenMsgCycleTime" BO_ 2588256839 1000;
BA_ "GenMsgSendType" BO_ 315 0;
BA_ "GenMsgCycleTime" BO_ 315 10;
BA_ "GenMsgCycleTime" BO_ 179 20;
BA_ "GenMsgSendType" BO_ 179 0;
BA_ "GenMsgSendType" BO_ 780 0;
BA_ "GenMsgCycleTime" BO_ 780 100;
BA_ "GenMsgCycleTime" BO_ 0 100;
BA_ "GenMsgCycleTime" BO_ 669 40;
BA_ "GenMsgSendType" BO_ 669 0;
BA_ "GenMsgCycleTime" BO_ 668 40;
BA_ "GenMsgSendType" BO_ 668 0;
BA_ "GenMsgSendType" BO_ 518 0;
BA_ "GenMsgCycleTime" BO_ 517 20;
BA_ "GenMsgSendType" BO_ 517 0;
BA_ "GenMsgCycleTime" BO_ 425 20;
BA_ "GenMsgSendType" BO_ 425 0;
BA_ "GenMsgCycleTime" BO_ 332 10;
BA_ "GenMsgSendType" BO_ 332 0;
BA_ "GenMsgSendType" BO_ 767 0;
BA_ "GenMsgCycleTime" BO_ 767 100;
BA_ "GenMsgSendType" BO_ 555 0;
BA_ "GenMsgCycleTime" BO_ 555 40;
BA_ "GenMsgSendType" BO_ 1646 0;
BA_ "GenMsgCycleTime" BO_ 1646 200;
BA_ "GenMsgCycleTime" BO_ 1619 1000;
BA_ "GenMsgCycleTime" BO_ 546 40;
BA_ "GenMsgCycleTime" BO_ 845 100;
BA_ "GenMsgCycleTime" BO_ 489 20;
BA_ "GenMsgSendType" BO_ 489 0;
BA_ "GenMsgCycleTime" BO_ 493 20;
BA_ "GenMsgSendType" BO_ 493 0;
BA_ "GenMsgCycleTime" BO_ 446 20;
BA_ "GenMsgSendType" BO_ 446 0;
BA_ "GenMsgCycleTime" BO_ 1108 300;
BA_ "GenMsgSendType" BO_ 1108 0;
BA_ "GenMsgCycleTime" BO_ 526 20;
BA_ "GenMsgSendType" BO_ 526 0;
BA_ "GenMsgCycleTime" BO_ 1302 500;
BA_ "GenMsgSendType" BO_ 1302 0;
BA_ "GenMsgCycleTime" BO_ 231 10;
BA_ "GenMsgSendType" BO_ 231 0;
BA_ "GenMsgCycleTime" BO_ 929 200;
BA_ "GenMsgSendType" BO_ 929 0;
BA_ "GenMsgCycleTime" BO_ 806 100;
BA_ "GenMsgSendType" BO_ 806 0;
BA_ "GenMsgCycleTime" BO_ 469 20;
BA_ "GenMsgSendType" BO_ 469 0;
BA_ "GenMsgCycleTime" BO_ 232 10;
BA_ "GenMsgSendType" BO_ 232 0;
BA_ "GenMsgCycleTime" BO_ 199 10;
BA_ "GenMsgSendType" BO_ 199 0;
BA_ "GenMsgCycleTime" BO_ 465 20;
BA_ "GenMsgSendType" BO_ 465 0;
BA_ "GenMsgSendType" BO_ 131 0;
BA_ "GenMsgCycleTime" BO_ 131 10;
BA_ "GenMsgSendType" BO_ 424 0;
BA_ "GenMsgCycleTime" BO_ 424 20;
BA_ "GenMsgCycleTime" BO_ 302 20;
BA_ "GenMsgSendType" BO_ 302 0;
BA_ "GenMsgCycleTime" BO_ 262 20;
BA_ "GenMsgSendType" BO_ 262 0;
BA_ "GenMsgCycleTime" BO_ 479 20;
BA_ "GenMsgSendType" BO_ 479 0;
BA_ "GenMsgCycleTime" BO_ 423 20;
BA_ "GenMsgSendType" BO_ 423 0;
BA_ "GenMsgCycleTime" BO_ 57 40;
BA_ "GenMsgSendType" BO_ 57 0;
BA_ "GenMsgSendType" BO_ 773 0;
BA_ "GenMsgCycleTime" BO_ 773 100;
BA_ "GenMsgSendType" BO_ 320 0;
BA_ "GenMsgCycleTime" BO_ 320 10;
BA_ "GenMsgSendType" BO_ 1928 0;
BA_ "GenMsgCycleTime" BO_ 148 10;
BA_ "GenMsgSendType" BO_ 148 0;
BA_ "GenMsgCycleTime" BO_ 486 20;
BA_ "GenMsgSendType" BO_ 486 0;
BA_ "GenMsgSendType" BO_ 330 0;
BA_ "GenMsgCycleTime" BO_ 330 10;
BA_ "GenMsgSendType" BO_ 441 0;
BA_ "GenMsgCycleTime" BO_ 441 20;
BA_ "GenMsgSendType" BO_ 795 0;
BA_ "GenMsgCycleTime" BO_ 795 100;
BA_ "PS" BO_ 795 5;
BA_ "GenMsgCycleTime" BO_ 387 10;
BA_ "GenMsgSendType" BO_ 387 0;
BA_ "GenMsgCycleTime" BO_ 419 20;
BA_ "GenMsgSendType" BO_ 419 0;
BA_ "GenMsgSendType" BO_ 538 0;
BA_ "GenMsgCycleTime" BO_ 538 40;
BA_ "GenMsgCycleTime" BO_ 470 20;
BA_ "GenMsgSendType" BO_ 470 0;
BA_ "GenMsgSendType" BO_ 422 0;
BA_ "GenMsgCycleTime" BO_ 422 20;
BA_ "PS" BO_ 422 5;
BA_ "PS" BO_ 884 5;
BA_ "GenMsgCycleTime" BO_ 884 100;
BA_ "GenMsgSendType" BO_ 884 0;
BA_ "GenMsgCycleTime" BO_ 1424 1000;
BA_ "GenMsgSendType" BO_ 1424 0;
BA_ "PS" BO_ 661 5;
BA_ "GenMsgCycleTime" BO_ 661 40;
BA_ "GenMsgSendType" BO_ 661 0;
BA_ "PS" BO_ 660 5;
BA_ "GenMsgCycleTime" BO_ 660 40;
BA_ "GenMsgSendType" BO_ 660 0;
BA_ "GenMsgCycleTime" BO_ 488 20;
BA_ "GenMsgSendType" BO_ 488 0;
BA_ "GenMsgSendType" BO_ 426 0;
BA_ "GenMsgCycleTime" BO_ 426 20;
BA_ "PS" BO_ 426 5;
BA_ "GenMsgSendType" BO_ 506 0;
BA_ "GenMsgCycleTime" BO_ 506 20;
BA_ "GenMsgSendType" BO_ 316 0;
BA_ "GenMsgCycleTime" BO_ 316 10;
BA_ "PS" BO_ 316 5;
BA_ "GenMsgSendType" BO_ 985 0;
BA_ "GenMsgCycleTime" BO_ 985 200;
BA_ "PS" BO_ 985 5;
BA_ "GenMsgSendType" BO_ 2564550641 0;
BA_ "PS" BO_ 2564550641 5;
BA_ "GenMsgSendType" BO_ 808 0;
BA_ "GenMsgCycleTime" BO_ 808 100;
BA_ "PS" BO_ 808 5;
BA_ "GenMsgSendType" BO_ 804 0;
BA_ "GenMsgCycleTime" BO_ 804 100;
BA_ "PS" BO_ 804 5;
BA_ "GenMsgSendType" BO_ 472 0;
BA_ "GenMsgCycleTime" BO_ 472 20;
BA_ "PS" BO_ 472 5;
BA_ "GenMsgCycleTime" BO_ 388 10;
BA_ "GenMsgSendType" BO_ 388 0;
BA_ "GenMsgCycleTime" BO_ 450 20;
BA_ "GenMsgSendType" BO_ 450 0;
BA_ "GenMsgCycleTime" BO_ 274 10;
BA_ "GenMsgSendType" BO_ 274 0;
BA_ "GenMsgSendType" BO_ 356 0;
BA_ "GenMsgCycleTime" BO_ 356 10;
BA_ "PS" BO_ 356 5;
BA_ "PS" BO_ 392 5;
BA_ "GenMsgCycleTime" BO_ 392 10;
BA_ "GenMsgSendType" BO_ 392 0;
BA_ "GenMsgSendType" BO_ 401 0;
BA_ "GenMsgCycleTime" BO_ 401 10;
BA_ "PS" BO_ 401 5;
BA_ "GenMsgSendType" BO_ 380 0;
BA_ "GenMsgCycleTime" BO_ 380 10;
BA_ "PS" BO_ 380 5;
BA_ "GenMsgSendType" BO_ 342 0;
BA_ "GenMsgCycleTime" BO_ 342 10;
BA_ "PS" BO_ 342 5;
BA_ "GenMsgSendType" BO_ 304 0;
BA_ "GenMsgCycleTime" BO_ 304 10;
BA_ "PS" BO_ 304 5;
BA_ "GenMsgCycleTime" BO_ 545 40;
BA_ "GenMsgSendType" BO_ 545 0;
BA_ "GenMsgCycleTime" BO_ 578 40;
BA_ "GenMsgSendType" BO_ 578 0;
BA_ "GenMsgSendType" BO_ 1934 0;
BA_ "PS" BO_ 1934 5;
BA_ "GenMsgCycleTime" BO_ 476 20;
BA_ "GenMsgSendType" BO_ 476 0;
BA_ "GenMsgSendType" BO_ 1030 0;
BA_ "GenMsgCycleTime" BO_ 1030 300;
BA_ "PS" BO_ 1030 5;
BA_ "GenMsgSendType" BO_ 597 0;
BA_ "GenMsgCycleTime" BO_ 597 40;
BA_ "PS" BO_ 597 5;
BA_ "GenMsgSendType" BO_ 490 0;
BA_ "GenMsgCycleTime" BO_ 490 20;
BA_ "PS" BO_ 490 5;
BA_ "GenMsgCycleTime" BO_ 334 10;
BA_ "GenMsgSendType" BO_ 334 0;
BA_ "GenMsgCycleTime" BO_ 1029 300;
BA_ "GenMsgSendType" BO_ 1029 0;
BA_ "GenMsgCycleTime" BO_ 819 100;
BA_ "GenMsgSendType" BO_ 819 0;
BA_ "GenMsgCycleTime" BO_ 487 20;
BA_ "GenMsgSendType" BO_ 487 0;
BA_ "GenMsgSendType" BO_ 464 0;
BA_ "GenMsgCycleTime" BO_ 464 20;
BA_ "PS" BO_ 464 5;
BA_ "GenMsgSendType" BO_ 432 0;
BA_ "GenMsgCycleTime" BO_ 432 20;
BA_ "PS" BO_ 432 5;
BA_ "GenMsgCycleTime" BO_ 150 10;
BA_ "GenMsgSendType" BO_ 150 0;
BA_ "GenMsgSendType" BO_ 428 0;
BA_ "GenMsgCycleTime" BO_ 428 20;
BA_ "PS" BO_ 428 5;
BA_ "GenMsgSendType" BO_ 420 0;
BA_ "GenMsgCycleTime" BO_ 420 20;
BA_ "PS" BO_ 420 5;
BA_ "PS" BO_ 411 5;
BA_ "GenMsgCycleTime" BO_ 411 10;
BA_ "GenMsgSendType" BO_ 411 0;
BA_ "GenMsgSendType" BO_ 145 0;
BA_ "GenMsgCycleTime" BO_ 145 10;
BA_ "PS" BO_ 145 5;
BA_ "GenSigInactiveValue" SG_ 3221225472 VSA_INH_MODE13_2 20;
BA_ "GenSigInactiveValue" SG_ 3221225472 VSA_INH_MODE15_2 20;
BA_ "GenSigInactiveValue" SG_ 3221225472 VSA_INH_MODE14_2 20;
BA_ "GenSigInactiveValue" SG_ 3221225472 VSA_INH_MODE6_2 20;
BA_ "GenSigInactiveValue" SG_ 3221225472 VSA_INH_MODE5_2 20;
BA_ "GenSigInactiveValue" SG_ 3221225472 VSA_INH_MODE4_2 20;
BA_ "GenSigInactiveValue" SG_ 3221225472 ENG_CAS_REQ_2 10;
BA_ "GenSigStartValue" SG_ 94 SRS_YAW_1_05E_2 511.999213569208;
BA_ "GenSigStartValue" SG_ 425 VSA_E4WD_TRQ_LIMITER_REQ_2 255;
BA_ "GenSigStartValue" SG_ 1646 VSA_MCPS_OFFSET_2 7;
BA_ "GenSigInactiveValue" SG_ 1619 VSA_DTC_LOW_BYTE_2 1000;
BA_ "GenSigInactiveValue" SG_ 1619 VSA_DTC_HIGH_BYTE_2 1000;
BA_ "GenSigInactiveValue" SG_ 1619 VSA_CHECKSUM_653_2 1000;
BA_ "GenSigInactiveValue" SG_ 1619 VSA_ALIVE_COUNTER_653_2 1000;
BA_ "GenSigInactiveValue" SG_ 1619 VSA_DTC_SYSTEM_DESIGNATOR_BIT_2 1000;
BA_ "GenSigInactiveValue" SG_ 1619 VSA_DTC_STORAGE_STATUS_2 1000;
BA_ "GenSigInactiveValue" SG_ 1619 VSA_FTB_STATUS_BIT_2 1000;
BA_ "GenSigInactiveValue" SG_ 1619 VSA_DTC_FTB_2 1000;
BA_ "GenSigInactiveValue" SG_ 546 METER_CHECKSUM_222_2 40;
BA_ "GenSigInactiveValue" SG_ 546 METER_ALIVE_COUNTER_222_2 40;
BA_ "GenSigInactiveValue" SG_ 546 METER_IDS_MODE_2 40;
BA_ "GenSigInactiveValue" SG_ 845 VSA_CHECKSUM_34D_2 100;
BA_ "GenSigInactiveValue" SG_ 845 VSA_ALIVE_COUNTER_34D_2 100;
BA_ "GenSigInactiveValue" SG_ 845 VSA_VSA_MODE_STATUS_2 100;
BA_ "GenSigInactiveValue" SG_ 446 EBB_IG_ON_2 20;
BA_ "GenSigInactiveValue" SG_ 446 EBB_BRAKE_PEDAL_ON 20;
BA_ "GenSigInactiveValue" SG_ 1108 ENG_CHECKSUM_454_2 300;
BA_ "GenSigInactiveValue" SG_ 1108 ENG_ALIVE_COUNTER_454_2 300;
BA_ "GenSigInactiveValue" SG_ 1108 ENG_FAIL_PA_2 300;
BA_ "GenSigInactiveValue" SG_ 1108 ENG_ATMOSPHERIC_PRESSURE_2 300;
BA_ "GenSigInactiveValue" SG_ 231 EBB_DRIVER_REQ_STROKE_2 10;
BA_ "GenSigStartValue" SG_ 231 EBB_DRIVER_REQ_STROKE_2 320;
BA_ "GenSigStartValue" SG_ 199 VSA_MASTER_CYLINDR_PRESURE_0C7_2 1023;
BA_ "GenSigInactiveValue" SG_ 479 IDAS_CRUISE_ACTIVE 20;
BA_ "GenSigInactiveValue" SG_ 320 ENG_REQUEST_EPB_ACT_2 10;
BA_ "GenSigInactiveValue" SG_ 148 SRS_POST_COLLISION_BRK_FAILURE_2 10;
BA_ "GenSigInactiveValue" SG_ 148 SRS_POST_COLLISION_BRK_2 10;
BA_ "GenSigStartValue" SG_ 330 EPS_STR_START_UP_2 1;
BA_ "GenSigInactiveValue" SG_ 330 EPS_STR_SPEED_2 10;
BA_ "GenSigInactiveValue" SG_ 795 VSA_REJECT_OFF_SW_OPTN_MID_2 100;
BA_ "GenSigInactiveValue" SG_ 795 VSA_MID_REQUEST_IDS_2 100;
BA_ "GenSigInactiveValue" SG_ 795 VSA_MID_REQUEST_VSA_OFF_2 100;
BA_ "GenSigInactiveValue" SG_ 795 VSA_MID_REQUEST_TCS_OFF_2 100;
BA_ "GenSigInactiveValue" SG_ 795 VSA_MID_REQ_EPB_MISOP_GUIDE_2 100;
BA_ "GenSigInactiveValue" SG_ 795 VSA_MID_LMP_STATS_OPRTE_BHOLD_2 100;
BA_ "GenSigInactiveValue" SG_ 795 VSA_MID_LAMP_STATUS_HDC_OFF_2 100;
BA_ "GenSigInactiveValue" SG_ 795 VSA_WARN_STATUS_HDC_2 100;
BA_ "GenSigInactiveValue" SG_ 795 VSA_MID_WARN_STATUS_TSA_2 100;
BA_ "GenSigStartValue" SG_ 795 VSA_MID_WARN_STATUS_BRAKESYSTM_2 1;
BA_ "DescriptionE" SG_ 795 VSA_ALIVE_COUNTER_31B_2 "Incremented by 1 every time a packet is refreshed.

(0 to 3 ring counters)";
BA_ "GenSigStartValue" SG_ 795 VSA_WARN_STATUS_HSA_31B_2 1;
BA_ "GenSigStartValue" SG_ 795 VSA_MID_WARN_STATUS_BRAKE_2 1;
BA_ "GenSigStartValue" SG_ 795 VSA_MID_WARN_STATUS_ABS_2 1;
BA_ "GenSigStartValue" SG_ 795 VSA_MID_REQUEST_VSA_31B_2 1;
BA_ "GenSigStartValue" SG_ 795 VSA_MID_LAMP_STATUS_VSA_OFF_2 1;
BA_ "GenSigStartValue" SG_ 538 VSA_CALIB_LAT_G_2 512.55230126;
BA_ "GenSigInactiveValue" SG_ 538 VSA_REQ_BRAKERELAY_ACT_2 40;
BA_ "ValueTableE" SG_ 422 METER_SW_STATUS_HIL_CONTRL_1A6_2 "1: HDC SW ON";
BA_ "ValueTableE" SG_ 422 METER_RL_STATUS_1A6_2 "1: Parking brake SW ON";
BA_ "ValueTableE" SG_ 422 METER_SW_STATUS_VSA_OFF_1A6_2 "1: VSA-off SW ON";
BA_ "ValueTableE" SG_ 422 METER_SW_STATUS_PARK_BRAKE_1A6_2 "1: Parking brake SW ON";
BA_ "ValueTableE" SG_ 422 METER_SW_STATUS_BRKE_FLUID_1A6_2 "1: Brake fluid level SW ON";
BA_ "DescriptionE" SG_ 422 METER_ALIVE_COUNTER_1A6_2 "Incremented by 1 every time a packet is refreshed.

(0 to 3 ring counters)";
BA_ "DescriptionE" SG_ 884 METER_ALIVE_COUNTER_374_2 "Incremented by 1 every time a packet is refreshed.(0 to 3 ring counters)";
BA_ "ValueTableE" SG_ 661 METER_DWS_INIT_REQ_SW_2 "1: Request DWS initialization";
BA_ "ValueTableE" SG_ 661 METER_DWS_INIT_REQ_2 "1: Request DWS initialization";
BA_ "GenSigInactiveValue" SG_ 488 VSA_EPB_STATE_1E8_2 20;
BA_ "GenSigInactiveValue" SG_ 488 VSA_EPB_REQ_TARGET_DECEL_1E8_2 20;
BA_ "GenSigInactiveValue" SG_ 488 VSA_EPB_INHIBIT_ACT_1E8_2 20;
BA_ "GenSigInactiveValue" SG_ 488 VSA_EPB_REFUSE_ACT_1E8_2 20;
BA_ "GenSigInactiveValue" SG_ 488 VSA_EPB_REQ_BRAKE_CTRL_1E8_2 20;
BA_ "GenSigInactiveValue" SG_ 426 VSA_IG_ON_2 20;
BA_ "GenSigInactiveValue" SG_ 426 VSA_IDS_INHIBIT_DISABLED_STATE_2 20;
BA_ "GenSigInactiveValue" SG_ 426 VSA_IDS_INHIBIT_ACT_2 20;
BA_ "GenSigInactiveValue" SG_ 426 VSA_EBB_FAILURE_FOR_IS_2 20;
BA_ "GenSigInactiveValue" SG_ 426 VSA_HAC_CUT_REQ_2 20;
BA_ "GenSigInactiveValue" SG_ 426 VSA_HBB_IS_REFUSE_REQ_2 20;
BA_ "GenSigInactiveValue" SG_ 426 VSA_LOW_VAC_IS_SHFT_INHBIT_REQ_2 20;
BA_ "GenSigInactiveValue" SG_ 426 VSA_HBB_IS_SHIFT_INHIBIT_REQ_2 20;
BA_ "GenSigInactiveValue" SG_ 426 VSA_MNTMODE_STATUS_2 20;
BA_ "GenSigInactiveValue" SG_ 426 VSA_REVERSE_SWITCH_FAIL_2 20;
BA_ "GenSigInactiveValue" SG_ 426 VSA_SHFT_IN_REVERSE_2 20;
BA_ "GenSigInactiveValue" SG_ 426 VSA_ECD_ACT_2 20;
BA_ "GenSigInactiveValue" SG_ 426 VSA_FAIL_FOR_EPB_2 20;
BA_ "GenSigInactiveValue" SG_ 426 VSA_REQUEST_EPB_ACT_2 20;
BA_ "GenSigInactiveValue" SG_ 426 VSA_EPB_INHIBIT_BRAKE_2 20;
BA_ "GenSigInactiveValue" SG_ 426 VSA_EPB_REFUSE_BRAKE_2 20;
BA_ "DescriptionE" SG_ 426 VSA_IS_SHFT_INHBIT_REQUEST_1AA_2 "When a side collision is detected, '1' is sent with each message which is output 10 times continuously.";
BA_ "DescriptionE" SG_ 426 VSA_SHIFT_REQ_1AA_2 "VSA shift control request

ID:?Valid only when the data of 1AAh 2.1-2.0 VSA_TRQ_CONTROL_MODE is '2.'";
BA_ "ValueTableE" SG_ 426 VSA_SHIFT_REQ_1AA_2 "0: No shift control request from VSA?(EAT?original control)

1: ?Request shift hold

2: Request upshift

3: Request downshift";
BA_ "DescriptionE" SG_ 426 VSA_TRQ_DOWN_REQ_FUEL_CUT_1AA_2 "Fuel control request signal

ID:?Valid only when the data of 1AAh 2.1-2.0 VSA_TRQ_CONTROL_MODE is '2.'";
BA_ "ValueTableE" SG_ 426 VSA_TRQ_DOWN_REQ_FUEL_CUT_1AA_2 "0: No fuel/ignition control (THL?control only)

1: Ignition retard

2: ?All cylinders F/C + Ignition?retard";
BA_ "DescriptionE" SG_ 426 VSA_ALIVE_COUNTER_1AA_2 "Incremented by 1 every time a packet is refreshed.

(0 to 3 ring counters)";
BA_ "DescriptionE" SG_ 426 VSA_REQ_MSR_PLUS_TRQ_1AA_2 "MSR?positive torque request flag";
BA_ "ValueTableE" SG_ 426 VSA_REQ_MSR_PLUS_TRQ_1AA_2 "1: ?Positive torque requested";
BA_ "DescriptionE" SG_ 426 VSA_TRQ_CONTROL_MODE_1AA_2 "Control mode

If the data has remained '3'?for 70 msec, the VSA is judged faulty and no request will be accepted from the VSA?until a reset is performed via IG?operation.";
BA_ "ValueTableE" SG_ 426 VSA_TRQ_CONTROL_MODE_1AA_2 "0: VSA/TCS control inactive (normal)

1: Request MSR?control

2: Request acceleration control (This value is set when engine control is required)

3: Inhibit VSA/TCS (VSA?failure)";
BA_ "DescriptionE" SG_ 426 VSA_REQ_TRQ_1AA_2 "Indicates the crankshaft torque.

-32768 to 32767 Nm

Indicates the crankshaft torque. ";
BA_ "GenSigStartValue" SG_ 506 ACC_REQ_BRAKERELAY_ACT_2 1;
BA_ "GenSigStartValue" SG_ 506 ACC_TARGET_CALIPER_PRESSURE_FR_2 1020;
BA_ "GenSigStartValue" SG_ 506 ACC_TARGET_CALIPER_PRESSURE_FL_2 1020;
BA_ "GenSigInactiveValue" SG_ 316 ENG_IG1_10V_STATUS_2 10;
BA_ "GenSigInactiveValue" SG_ 316 ENG_CLUTCH_SW_SIL_2 10;
BA_ "ValueTableE" SG_ 316 ENG_NEUTRAL_SENSOR_FAIL_13C_2 "1: NEUTRAL SENSOR FAIL";
BA_ "GenSigStartValue" SG_ 316 ENG_SHFT_IN_NEUTRAL_13C_2 1;
BA_ "DescriptionJ" SG_ 316 ENG_SHFT_IN_NEUTRAL_13C_2 "*";
BA_ "ValueTableE" SG_ 316 ENG_SHFT_IN_NEUTRAL_13C_2 "*";
BA_ "ValueTableE" SG_ 316 ENG_SHFT_IN_REVERSE_13C_2 "*";
BA_ "DescriptionJ" SG_ 316 ENG_SHFT_IN_REVERSE_13C_2 "*";
BA_ "GenSigStartValue" SG_ 316 ENG_SHFT_IN_REVERSE_13C_2 1;
BA_ "GenSigStartValue" SG_ 316 ENG_CLUTCH_SW_CC_13C_2 1;
BA_ "DescriptionE" SG_ 316 ENG_CLUTCH_SW_CC_13C_2 "Clutch sw signal for Cruise control";
BA_ "ValueTableE" SG_ 316 ENG_CLUTCH_SW_CC_13C_2 "1: Clutch pedal is not depressed(SW ON)

0: Clutch pedal is depressed(SW OFF)";
BA_ "DescriptionE" SG_ 316 ENG_VSA_ACK1_13C_2 "Response to VSA fuel control request";
BA_ "ValueTableE" SG_ 316 ENG_VSA_ACK1_13C_2 "0: No fuel/ignition control (THL?control only)

1: Ignition retard

2: ?All cylinders in the F/C mode";
BA_ "DescriptionE" SG_ 316 ENG_VSA_PERMIT_PLUS_TRQ_13C_2 "MSR?positive torque permission flag";
BA_ "ValueTableE" SG_ 316 ENG_VSA_PERMIT_PLUS_TRQ_13C_2 "1: Positive torque permitted";
BA_ "DescriptionE" SG_ 316 ENG_ALIVE_COUNTER_13C_2 "Incremented by 1 every time a packet is refreshed.

(0 to 3 ring counters)";
BA_ "DescriptionE" SG_ 316 ENG_RECEIVE_ERROR_1AA_2 "Flag indicating whether or not a reception error is present

ID:?'1'?if at least one of the 1AAh alive counter refresh error, checksum error or timeout has continued for 60 msec.";
BA_ "ValueTableE" SG_ 316 ENG_RECEIVE_ERROR_1AA_2 "1: Reception error detected";
BA_ "DescriptionE" SG_ 316 ENG_VSA_INHIBIT_VSA_CONTRL_13C_2 "VSA control permission/inhibition information";
BA_ "ValueTableE" SG_ 316 ENG_VSA_INHIBIT_VSA_CONTRL_13C_2 "1: VSA F/Ccontrol temporarily stopped";
BA_ "DescriptionE" SG_ 316 ENG_VSA_REFUSED_VSA_CONTRL_13C_2 "VSA control permission/inhibition information";
BA_ "ValueTableE" SG_ 316 ENG_VSA_REFUSED_VSA_CONTRL_13C_2 "1: Failure that disables VSA control is present";
BA_ "DescriptionE" SG_ 316 ENG_SMART_ACCELE_PEDAL_POS_13C_2 "Acceleration pedal position (%)

( at the time of a Smart Pedal System Application )";
BA_ "DescriptionE" SG_ 316 ENG_DRIVER_REQ_TRQ_13C_2 "Indicates the driver-requested crankshaft driving torque.

Cruise-requested crankshaft driving torque during cruise control.";
BA_ "DescriptionE" SG_ 316 ENG_ENG_TRQ_13C_2 "Indicates the crankshaft torque.

-32768 to 32767 Nm";
BA_ "DescriptionE" SG_ 985 VSA_ALIVE_COUNTER_3D9_2 "Incremented by 1 every time a packet is refreshed.

(0 to 3 ring counters)";
BA_ "ValueTableE" SG_ 985 VSA_STABILITY_CTRL1_DSABLE_EDR_2 "0: STABILITY CONTROL1 ENABLE

1: STABILITY CONTROL1 DISABLE";
BA_ "ValueTableE" SG_ 985 VSA_STABILITY_CTRL2_DSABLE_EDR_2 "0: STABILITY CONTROL2 ENABLE

1: STABILITY CONTROL2 DISABLE";
BA_ "DescriptionE" SG_ 2564550641 HDS_HDC_CAN_2 "Data frame for failure diagnosis/reprogramming

Refer to 'Function Request for ECU Not Implementing HDC_CAN Protocol.'";
BA_ "DescriptionE" SG_ 808 ENG_ALIVE_COUNTER_328_2 "Incremented by 1 every time a packet is refreshed.

(0 to 3 ring counters)";
BA_ "ValueTableE" SG_ 808 ENG_STRNNEND_2 "1: Complete combustion";
BA_ "DescriptionE" SG_ 808 ENG_STRNNEND_2 "Engine complete combustion judgment flag";
BA_ "GenSigStartValue" SG_ 804 ENG_ENG_COOLANT_TEMP_2 255;
BA_ "GenSigInactiveValue" SG_ 804 ENG_ENG_COOLANT_TEMP_2 100;
BA_ "DescriptionE" SG_ 804 ENG_ALIVE_COUNTER_324_2 "Incremented by 1 every time a packet is refreshed.

(0 to 3 ring counters)";
BA_ "ValueTableE" SG_ 804 ENG_SW_STATUS_SCS_2 "1: SCS SW ON";
BA_ "DescriptionE" SG_ 472 SS30_SYSTEM_ACT_2 "0";
BA_ "DescriptionJ" SG_ 472 SS30_SYSTEM_ACT_2 "*";
BA_ "DescriptionE" SG_ 472 SS30_ALIVE_COUNTER_1D8_2 "Incremented by 1 every time a packet is refreshed.

(0 to 3 ring counters)";
BA_ "DescriptionE" SG_ 472 SS30_STATUS_FAIL_2 "0";
BA_ "GenSigInactiveValue" SG_ 388 ESB_IG_ON_2 10;
BA_ "GenSigStartValue" SG_ 450 VSA_EPB_DAR_DISABLE_2 1;
BA_ "GenSigInactiveValue" SG_ 450 EPB_FAIL_2 20;
BA_ "GenSigInactiveValue" SG_ 356 METER_SW_STATUS_BHOLD_SENKOSYA_2 10;
BA_ "DescriptionE" SG_ 356 METER_ALIVE_COUNTER_164_2 "Incremented by 1 every time a packet is refreshed.

(0 to 3 ring counters)";
BA_ "ValueTableE" SG_ 356 METER_SW_STATUS_PARK_BRAKE_2 "1: Parking brake SW ON";
BA_ "ValueTableE" SG_ 356 METER_SW_STATUS_BRAKE_FLUID_2 "1: Brake fluid level SW ON";
BA_ "ValueTableE" SG_ 356 METER_SW_STATUS_VSA_OFF_2 "1: VSA-off SW ON";
BA_ "GenSigInactiveValue" SG_ 392 EAT_SW_STATUS_SMODE 10;
BA_ "ValueTableE" SG_ 392 EAT_SHFT_IN_PARKING_2 "1: 'P'";
BA_ "ValueTableE" SG_ 392 EAT_SHFT_IN_REVERSE_2 "1: 'R'";
BA_ "ValueTableE" SG_ 392 EAT_SHFT_IN_NEUTRAL_2 "1: 'N'";
BA_ "ValueTableE" SG_ 392 EAT_SHFT_IN_D_2 "1: 'D'";
BA_ "ValueTableE" SG_ 392 EAT_SHFT_IN_D4_2 "1: 'D4'";
BA_ "ValueTableE" SG_ 392 EAT_SHFT_IN_D3_2 "1: 'D3'";
BA_ "ValueTableE" SG_ 392 EAT_SHFT_IN_2_2 "1: '2' or 'L'";
BA_ "ValueTableE" SG_ 392 EAT_SHFT_IN_1_2 "1: '1'";
BA_ "ValueTableE" SG_ 392 EAT_FAILURE_FOR_VSA_2 "1: AT failure that disables VSA control is present";
BA_ "ValueTableE" SG_ 392 EAT_GEAR_POSITION_TARGET_2 "0: Neutral

1: 1st

2: 2nd

3: 3rd

4: 4th

5: 5th

6: Reverse

7: 6th";
BA_ "ValueTableE" SG_ 392 EAT_GEAR_POSITION_ACTUAL_2 "0: Neutral

1: 1st

2: 2nd

3: 3rd

4: 4th

5: 5th

6: Reverse

7: Shifting 

8: 6th";
BA_ "GenSigStartValue" SG_ 401 CVT_SW_STATUS_SMODE_2 1;
BA_ "ValueTableE" SG_ 401 CVT_CAS_ON_2 "1: CAS_ONrequest to VSA";
BA_ "DescriptionE" SG_ 401 CVT_ALIVE_COUNTER_191_2 "Incremented by 1 every time a packet is refreshed.

(0 to 3 ring counters)";
BA_ "GenSigStartValue" SG_ 401 CVT_RATIO_TARGET_2 64;
BA_ "DescriptionE" SG_ 401 CVT_RATIO_TARGET_2 "Target ratio information";
BA_ "GenSigStartValue" SG_ 401 CVT_RATIO_INFO_191_2 64;
BA_ "DescriptionE" SG_ 401 CVT_RATIO_INFO_191_2 "Ratio information";
BA_ "ValueTableE" SG_ 401 CVT_REFUSE_VSA_CONTROL_2 "1: CVTfailure that disables VSA control is present";
BA_ "ValueTableE" SG_ 401 CVT_GEAR_POSITION_IND_CVT_2 "0: OFF

1: 1st

2: 2nd

3: 3rd

4: 4th

5: 5th

6: 6th

7: 7th

8: 8th

F: ?L range control active";
BA_ "DescriptionE" SG_ 401 CVT_GEAR_POSITION_IND_CVT_2 "Shift position indication for S-Matic

For S-Matic LED indication

8-E: OFF";
BA_ "ValueTableE" SG_ 401 CVT_SHFT_IN_PARKING_2 "1: Parking";
BA_ "DescriptionE" SG_ 401 CVT_SHFT_IN_PARKING_2 "Select lever position";
BA_ "ValueTableE" SG_ 401 CVT_SHFT_IN_REVERSE_2 "1: Reverse";
BA_ "DescriptionE" SG_ 401 CVT_SHFT_IN_REVERSE_2 "Select lever position";
BA_ "ValueTableE" SG_ 401 CVT_SHFT_IN_NEUTRAL_2 "1: Neutral";
BA_ "DescriptionE" SG_ 401 CVT_SHFT_IN_NEUTRAL_2 "Select lever position";
BA_ "ValueTableE" SG_ 401 CVT_SHFT_IN_D_2 "1: 'D'";
BA_ "DescriptionE" SG_ 401 CVT_SHFT_IN_D_2 "Select lever position";
BA_ "ValueTableE" SG_ 401 CVT_SHFT_IN_S_2 "1: 'S'";
BA_ "DescriptionE" SG_ 401 CVT_SHFT_IN_S_2 "Select lever position

Meter 'S' lighting information

* S lighting information under the following two specifications

- 'S range' on the shift lever

 - 'Sports mode (SPO-IND)' effected by the S SW?";
BA_ "ValueTableE" SG_ 401 CVT_SHFT_IN_L_2 "1: 'L'";
BA_ "DescriptionE" SG_ 401 CVT_SHFT_IN_L_2 "Select lever position";
BA_ "DescriptionE" SG_ 380 ENG_CRUISE_STATUS_CRUISE_INH_2 "Indicates inhibition of cruise control.";
BA_ "DescriptionE" SG_ 380 ENG_ALIVE_COUNTER_17C_2 "Incremented by 1 every time a packet is refreshed.

(0 to 3 ring counters)";
BA_ "ValueTableE" SG_ 380 ENG_IS_PROGRESS_2 "1: Idle stop control started or in progress";
BA_ "DescriptionE" SG_ 380 ENG_SW_STATUS_BRAKE_NO_2 "The brake switch NO indicates the brake mode.

(SW ON)";
BA_ "ValueTableE" SG_ 380 ENG_CRUISE_STATUS_CRUISE_LMP_2 "1: Cruise control lamp ON";
BA_ "DescriptionE" SG_ 380 ENG_ENG_SPEED_2 "Engine speed

0 to 15000 rpm";
BA_ "GenSigInactiveValue" SG_ 342 STR_TRIM_2 10;
BA_ "DescriptionE" SG_ 342 STR_ALIVE_COUNTER_156_2 "Incremented by 1 every time a packet is refreshed.

(0 to 3 ring counters)";
BA_ "GenSigStartValue" SG_ 342 STR_OK_2 1;
BA_ "DescriptionE" SG_ 342 STR_OK_2 "OK flag: Indicates that the sensor is normal.

- 1 is output when normal.";
BA_ "GenSigStartValue" SG_ 342 STR_CAL_2 1;
BA_ "DescriptionE" SG_ 342 STR_CAL_2 "Calibration flag:?Indicates whether or not zero is set.

- 1 is output when set.

Becomes '1'?if zero is set after installation on the vehicle.";
BA_ "ValueTableE" SG_ 342 STR_ANGLE_2 "E278: -756[deg]

0000: 0[deg]

1D88: +756[deg]

7FFF: Invalid";
BA_ "DescriptionE" SG_ 342 STR_ANGLE_2 "Steering angle signal";
BA_ "GenSigInactiveValue" SG_ 304 ENG_CLUTCH_SW_SIL_2 10;
BA_ "GenSigInactiveValue" SG_ 304 ENG_EV_DRIVE_STATE_2 10;
BA_ "ValueTableE" SG_ 304 ENG_SHFT_IN_REVERSE_2 "*";
BA_ "DescriptionE" SG_ 304 ENG_SHFT_IN_REVERSE_2 "*";
BA_ "DescriptionJ" SG_ 304 ENG_SHFT_IN_REVERSE_2 "*";
BA_ "GenSigStartValue" SG_ 304 ENG_SHFT_IN_REVERSE_2 1;
BA_ "DescriptionE" SG_ 304 ENG_ALIVE_COUNTER_130_2 "Incremented by 1 every time a packet is refreshed.

(0 to 3 ring counters)";
BA_ "ValueTableE" SG_ 304 ENG_NEUTRAL_SENSOR_FAIL_2 "1: NEUTRAL SENSOR FAIL";
BA_ "ValueTableE" SG_ 304 ENG_RECEIVE_ERROR_1AC_2 "1: Reception error detected";
BA_ "DescriptionE" SG_ 304 ENG_RECEIVE_ERROR_1AC_2 "Flag indicating whether or not a reception error is present

ID:?'1'?if at least one of the 1AAh alive counter refresh error, checksum error or timeout has continued for 60 msec.";
BA_ "ValueTableE" SG_ 304 ENG_SHFT_IN_NEUTRAL_2 "1: SHIFT LEVER IS IN NEUTRAL";
BA_ "GenSigStartValue" SG_ 304 ENG_CLUTCH_SW_CC_2 1;
BA_ "ValueTableE" SG_ 304 ENG_CLUTCH_SW_CC_2 "1: Clutch pedal is not depressed(SW ON)

0: Clutch pedal is depressed(SW OFF)";
BA_ "DescriptionE" SG_ 304 ENG_CLUTCH_SW_CC_2 "Clutch sw signal for Cruise control";
BA_ "ValueTableE" SG_ 304 ENG_VSA_ACK1_2 "0: No fuel/ignition control (THL?control only)

1: Ignition retard

2: ?All cylinders in the F/C mode";
BA_ "DescriptionE" SG_ 304 ENG_VSA_ACK1_2 "Response to VSA fuel control request";
BA_ "ValueTableE" SG_ 304 ENG_VSA_PERMIT_PLUS_TRQ_2 "1: Positive torque permitted";
BA_ "DescriptionE" SG_ 304 ENG_VSA_PERMIT_PLUS_TRQ_2 "MSR?positive torque permission flag";
BA_ "ValueTableE" SG_ 304 ENG_VSA_INHIBIT_VSA_CONTROL_1_2 "1: VSA F/Ccontrol temporarily stopped";
BA_ "DescriptionE" SG_ 304 ENG_VSA_INHIBIT_VSA_CONTROL_1_2 "VSA control permission/inhibition information";
BA_ "ValueTableE" SG_ 304 ENG_VSA_REFUSED_VSA_CONTROL_1_2 "1: Failure that disables VSA control is present";
BA_ "DescriptionE" SG_ 304 ENG_VSA_REFUSED_VSA_CONTROL_1_2 "VSA control permission/inhibition information";
BA_ "DescriptionE" SG_ 304 ENG_SMART_ACCELE_PEDAL_POS_2 "Acceleration pedal position (%)

( at the time of a Smart Pedal System Application )";
BA_ "GenSigStartValue" SG_ 304 ENG_DRIVER_REQ_TRQ_130_2 32767;
BA_ "DescriptionE" SG_ 304 ENG_DRIVER_REQ_TRQ_130_2 "Indicates the driver-requested crankshaft driving torque.

Cruise-requested crankshaft driving torque during cruise control.";
BA_ "GenSigStartValue" SG_ 304 ENG_ENG_TRQ_130_2 32767;
BA_ "DescriptionE" SG_ 304 ENG_ENG_TRQ_130_2 "Indicates the crankshaft torque.

-32768 to 32767 Nm";
BA_ "GenSigInactiveValue" SG_ 545 METER_ECONSW_ON_2 40;
BA_ "ValueTableE" SG_ 1934 VSA_COMMAND_CODE_2 "3: Calibration

5: Reset of the Calibration";
BA_ "DescriptionE" SG_ 1030 VSA_ALIVE_COUNTER_406_2 "Incremented by 1 every time a packet is refreshed.

(0 to 3 ring counters)";
BA_ "GenSigStartValue" SG_ 1030 VSA_SPECIFY_CODE_SYS_2 1;
BA_ "DescriptionE" SG_ 597 VSA_ABS_CHECKSUM_255_2 "CAN checksum for ESL?(255h)";
BA_ "DescriptionE" SG_ 597 VSA_ABS_ALIVE_COUNTER_255_2 "CAN alive counter for ESL";
BA_ "GenSigStartValue" SG_ 597 VSA_ABS_SPEED_FIXED_NUMBER2_2 85;
BA_ "DescriptionE" SG_ 597 VSA_ABS_SPEED_FIXED_NUMBER2_2 "Fixed checksum value (ESL)

A fixed value of 0x55 is sent (also in the initial state).";
BA_ "GenSigStartValue" SG_ 597 VSA_ABS_SPEED_FIXED_NUMBER1_2 85;
BA_ "DescriptionE" SG_ 597 VSA_ABS_SPEED_FIXED_NUMBER1_2 "Fixed checksum value (ESL)

A fixed value of 0x55 is sent (also in the initial state).";
BA_ "GenSigStartValue" SG_ 597 VSA_ABS_RR_WHEEL_SPEED_255_2 250;
BA_ "DescriptionE" SG_ 597 VSA_ABS_RR_WHEEL_SPEED_255_2 "Right rear wheel speed  If failure occurs value is converted directly to speed. 

FFh shall be sent if the measured value has overflowed due to an open failure.

If Noise causes high vehicle speed shall be sent but, upper limit is clipped at 250 km/h.";
BA_ "GenSigStartValue" SG_ 597 VSA_ABS_RL_WHEEL_SPEED_255_2 250;
BA_ "DescriptionE" SG_ 597 VSA_ABS_RL_WHEEL_SPEED_255_2 "Left rear wheel speed  If failure occurs value is converted directly to speed. 

FFh shall be sent if the measured value has overflowed due to an open failure.

If Noise causes high vehicle speed shall be sent but, upper limit is clipped at 250 km/h.";
BA_ "GenSigStartValue" SG_ 597 VSA_ABS_FR_WHEEL_SPEED_255_2 250;
BA_ "DescriptionE" SG_ 597 VSA_ABS_FR_WHEEL_SPEED_255_2 "Right front wheel speed If failure occurs value is converted directly to speed. 

FFh shall be sent if the measured value has overflowed due to an open failure.

If Noise causes high vehicle speed shall be sent but, upper limit is clipped at 250 km/h.";
BA_ "GenSigStartValue" SG_ 597 VSA_ABS_FL_WHEEL_SPEED_255_2 250;
BA_ "DescriptionE" SG_ 597 VSA_ABS_FL_WHEEL_SPEED_255_2 "Left front wheel speed If failure occurs value is converted directly to speed. 

FFh shall be sent if the measured value has overflowed due to an open failure.

If Noise causes high vehicle speed shall be sent but, upper limit is clipped at 250 km/h.

";
BA_ "DescriptionE" SG_ 490 VSA_ALIVE_COUNTER_1EA_2 "Incremented by 1 every time a packet is refreshed.

(0 to 3 ring counters)";
BA_ "ValueTableE" SG_ 490 VSA_MAEPS_REVERSE_F_2 "1: Reverse";
BA_ "DescriptionE" SG_ 490 VSA_MAEPS_REVERSE_F_2 "VSA status signal 1";
BA_ "ValueTableE" SG_ 490 VSA_SYSTEM_F_2 "1: VSA system failure";
BA_ "DescriptionE" SG_ 490 VSA_SYSTEM_F_2 "VSA status signal 3";
BA_ "DescriptionE" SG_ 490 VSA_MAEPS_MYU_VALUE_2 "m ratio signal";
BA_ "DescriptionE" SG_ 490 VSA_MAEPS_GX_VALUE_2 "Estimate vehicle front/rear G signal";
BA_ "DescriptionE" SG_ 490 VSA_MAEPS_US_VALUE_2 "Yaw rate deviation signal";
BA_ "GenSigInactiveValue" SG_ 819 TPMS_WARN_STATUS_SYSTEM_2 100;
BA_ "GenSigStartValue" SG_ 487 VSA_CALIPPER_PRESSURE_FR_2 102;
BA_ "GenSigStartValue" SG_ 487 VSA_CALIPPER_PRESSURE_FL_2 102;
BA_ "DescriptionE" SG_ 464 VSA_ABS_RR_WHEEL_SPEED_2 "Right rear wheel speed

0~300 km/h

CAN outputs failed value even when sensor failure occurs. 

When Open 0000h shall be sent in overflow condition. If noise causes high vehicle speed the measured vehicle speed shall be sent but, upper limit is 300 km/h.";
BA_ "DescriptionE" SG_ 464 VSA_ABS_RL_WHEEL_SPEED_2 "Left rear wheel speed

0~300 km/h

CAN outputs failed value even when sensor failure occurs. 

When Open 0000h shall be sent in overflow condition. If noise causes high vehicle speed the measured vehicle speed shall be sent but, upper limit is 300 km/h.";
BA_ "DescriptionE" SG_ 464 VSA_ABS_FR_WHEEL_SPEED_2 "Right front wheel speed

0~300 km/h

CAN outputs failed value even when sensor failure occurs. 

When Open 0000h shall be sent in overflow condition. If noise causes high vehicle speed the measured vehicle speed shall be sent but, upper limit is 300 km/h";
BA_ "DescriptionE" SG_ 464 VSA_ABS_FL_WHEEL_SPEED_2 "Left front wheel speed 

0~300 km/h

CAN outputs failed value even when sensor failure occurs. 

When Open 0000h shall be sent in overflow condition. If noise causes high vehicle speed the measured vehicle speed shall be sent but, upper limit is 300 km/h";
BA_ "GenSigStartValue" SG_ 432 VSA_PLANT_INSPECTION_STATUS_2 1;
BA_ "GenSigInactiveValue" SG_ 432 VSA_PLANT_INSPECTION_STATUS_2 20;
BA_ "GenSigInactiveValue" SG_ 432 VSA_ABS_BUSY_2 20;
BA_ "GenSigStartValue" SG_ 432 VSA_ABS_ENB_VW_SENSOR_ACT_2 1;
BA_ "ValueTableE" SG_ 432 VSA_FAIL_LONG_G_SENSOR_2 "1: Fail LON G";
BA_ "DescriptionE" SG_ 432 VSA_ALIVE_COUNTER_1B0_2 "Incremented by 1 every time a packet is refreshed.

(0 to 3 ring counters)";
BA_ "ValueTableE" SG_ 432 VSA_REQ_CVT_TCS_2 "1: ?TCS operation permitted";
BA_ "DescriptionE" SG_ 432 VSA_REQ_CVT_TCS_2 "CVT?control request

CVT?coordination control request signal";
BA_ "ValueTableE" SG_ 432 VSA_REQ_CVT_PRS_2 "1: ?Pressurizing";
BA_ "DescriptionE" SG_ 432 VSA_REQ_CVT_PRS_2 "CVT?control request

CVT?coordination control request signal";
BA_ "ValueTableE" SG_ 432 VSA_CONTROL_MODE_CVT_2 "0: VSA control ready

1: ?TCS active

2: Reserved

3: Reserved";
BA_ "DescriptionE" SG_ 432 VSA_CONTROL_MODE_CVT_2 "CVT?coordination control mode

Dedicated CVT?coordination control mode";
BA_ "ValueTableE" SG_ 432 VSA_ABS_STATUS_FR_ABS_EBD_ACT_2 "1: ?FR?wheel ABS, EBD active";
BA_ "ValueTableE" SG_ 432 VSA_ABS_STATUS_FL_ABS_EBD_ACT_2 "1: ?FL?wheel ABS, EBD active";
BA_ "ValueTableE" SG_ 432 VSA_ABS_STATUS_RR_ABS_EBD_ACT_2 "1: ?RR?wheel ABS, EBD active";
BA_ "ValueTableE" SG_ 432 VSA_ABS_STATUS_RL_ABS_EBD_ACT_2 "1: ?RL?wheel ABS, EBD active";
BA_ "ValueTableE" SG_ 432 VSA_FAIL_YAW_RATE_SENSOR_2 "1: Yaw rate sensor error";
BA_ "ValueTableE" SG_ 432 VSA_ABS_FAIL_FR_VW_SENSOR_2 "1: ?Wheel speed sensor; FR?wheel error";
BA_ "ValueTableE" SG_ 432 VSA_ABS_FAIL_FL_VW_SENSOR_2 "1: ?Wheel speed sensor; FL?wheel error";
BA_ "ValueTableE" SG_ 432 VSA_ABS_FAIL_RR_VW_SENSOR_2 "1: ?Wheel speed sensor; RR?wheel error";
BA_ "ValueTableE" SG_ 432 VSA_ABS_FAIL_RL_VW_SENSOR_2 "1: ?Wheel speed sensor; RL?wheel error";
BA_ "GenSigStartValue" SG_ 432 VSA_ACC_INHIBIT_CVRS_BRAKE_2 1;
BA_ "ValueTableE" SG_ 432 VSA_ACC_INHIBIT_CVRS_BRAKE_2 "1: Temporarily inhibit CVRS brake";
BA_ "DescriptionE" SG_ 432 VSA_ACC_INHIBIT_CVRS_BRAKE_2 "ACC brake control inhibition information

The default value is sent if there is no ACC.";
BA_ "GenSigStartValue" SG_ 432 VSA_ACC_REFUSE_CVRS_BRAKE_2 1;
BA_ "ValueTableE" SG_ 432 VSA_ACC_REFUSE_CVRS_BRAKE_2 "1: ?Failure that disables CVRS brake occurred";
BA_ "DescriptionE" SG_ 432 VSA_ACC_REFUSE_CVRS_BRAKE_2 "ACC brake control inhibition information

The default value is sent if there is no ACC.";
BA_ "ValueTableE" SG_ 432 VSA_VW_PULSE_CAPTURED_2 "1: Wheel speed pulse available";
BA_ "DescriptionE" SG_ 432 VSA_VW_PULSE_CAPTURED_2 "Wheel speed pulse generation flag

The flag is set to '1' if a wheel speed pulse has generated at least once between the last transmission and this transmission.";
BA_ "DescriptionE" SG_ 432 VSA_INHBIT_YAW_RATE_SENSOR_2 "When a side collision is detected, '1' is sent with each message which is output 10 times continuously.";
BA_ "GenSigStartValue" SG_ 150 VSA_YAW_2_2 512;
BA_ "GenSigInactiveValue" SG_ 428 VSA_IG_ON_2 20;
BA_ "GenSigInactiveValue" SG_ 428 VSA_EBB_FAILURE_FOR_IS_2 20;
BA_ "GenSigInactiveValue" SG_ 428 VSA_IDS_INHIBIT_DISABLED_STATE_2 20;
BA_ "GenSigInactiveValue" SG_ 428 VSA_IDS_INHIBIT_ACT_2 20;
BA_ "GenSigInactiveValue" SG_ 428 VSA_HAC_CUT_REQ_2 20;
BA_ "GenSigInactiveValue" SG_ 428 VSA_HBB_IS_REFUSE_REQ_2 20;
BA_ "GenSigInactiveValue" SG_ 428 VSA_LOW_VAC_IS_SHFT_INHBIT_REQ_2 20;
BA_ "GenSigInactiveValue" SG_ 428 VSA_MNTMODE_STATUS_2 20;
BA_ "GenSigInactiveValue" SG_ 428 VSA_REVERSE_SWITCH_FAIL_2 20;
BA_ "GenSigInactiveValue" SG_ 428 VSA_SHFT_IN_REVERSE_2 20;
BA_ "GenSigInactiveValue" SG_ 428 VSA_ECD_ACT_2 20;
BA_ "GenSigInactiveValue" SG_ 428 VSA_FAIL_FOR_EPB_2 20;
BA_ "GenSigInactiveValue" SG_ 428 VSA_REQUEST_EPB_ACT_2 20;
BA_ "GenSigInactiveValue" SG_ 428 VSA_EPB_INHIBIT_BRAKE_2 20;
BA_ "GenSigInactiveValue" SG_ 428 VSA_HBB_IS_SHIFT_INHIBIT_REQ_2 20;
BA_ "GenSigInactiveValue" SG_ 428 VSA_EPB_REFUSE_BRAKE_2 20;
BA_ "GenSigInactiveValue" SG_ 428 VSA_TSA_ACT_2 20;
BA_ "DescriptionE" SG_ 428 VSA_IS_SHIFT_INHIBIT_REQUEST_1_2 "When a side collision is detected, '1' is sent with each message which is output 10 times continuously.";
BA_ "ValueTableE" SG_ 428 VSA_SHIFT_REQ_1AC_2 "0: No shift control request from VSA?(EAT?original control)

1: ?Request shift hold

2: Request upshift

3: Request downshift";
BA_ "DescriptionE" SG_ 428 VSA_SHIFT_REQ_1AC_2 "VSA shift control request

ID:?Valid only when the data of 1AAh 2.1-2.0 VSA_TRQ_CONTROL_MODE is '2.'";
BA_ "DescriptionE" SG_ 428 VSA_ALIVE_COUNTER_1AC_2 "Incremented by 1 every time a packet is refreshed.

(0 to 3 ring counters)";
BA_ "GenSigStartValue" SG_ 428 VSA_REQ_TRQ_1AC_2 32767;
BA_ "DescriptionE" SG_ 428 VSA_REQ_TRQ_1AC_2 "Indicates the crankshaft torque.

-32768 to 32767 Nm

Indicates the crankshaft torque. ";
BA_ "ValueTableE" SG_ 428 VSA_REQ_MSR_PLUS_TRQ_2 "1: ?Positive torque requested";
BA_ "DescriptionE" SG_ 428 VSA_REQ_MSR_PLUS_TRQ_2 "MSR?positive torque request flag";
BA_ "ValueTableE" SG_ 428 VSA_TRQ_CONTROL_MODE_2 "0: VSA/TCS control inactive (normal)

1: Request MSR?control

2: Request acceleration control (This value is set when engine control is required)

3: Inhibit VSA/TCS (VSA?failure)";
BA_ "DescriptionE" SG_ 428 VSA_TRQ_CONTROL_MODE_2 "Control mode

If the data has remained '3'?for 70 msec, the VSA is judged faulty and no request will be accepted from the VSA?until a reset is performed via IG?operation.";
BA_ "ValueTableE" SG_ 428 VSA_TRQ_DOWN_REQ_FUEL_CUT_2 "0: No fuel/ignition control (THL?control only)

1: Ignition retard

2: ?All cylinders F/C + Ignition?retard";
BA_ "DescriptionE" SG_ 428 VSA_TRQ_DOWN_REQ_FUEL_CUT_2 "Fuel control request signal

ID:?Valid only when the data of 1AAh 2.1-2.0 VSA_TRQ_CONTROL_MODE is '2.'";
BA_ "GenSigInactiveValue" SG_ 420 VSA_VSA_OS_CTRL_2 20;
BA_ "GenSigInactiveValue" SG_ 420 VSA_ESB_INCREASE_PRESS_ACT_2 20;
BA_ "ValueTableE" SG_ 420 VSA_LAMP_STATUS_VSA_OFF_TFT_2 "1: TSA warning is illuminated";
BA_ "DescriptionE" SG_ 420 VSA_WARN_STATUS_BRAKESYSTEM_2 "Brakesystem Warning Lamp Status";
BA_ "ValueTableE" SG_ 420 VSA_WARN_STATUS_BRAKESYSTEM_2 "1: Brakesystem Warning Lamp ON";
BA_ "GenSigStartValue" SG_ 420 VSA_LAMP_STATUS_HDC_2 1;
BA_ "DescriptionE" SG_ 420 VSA_LAMP_STATUS_HDC_2 "HDC Control Status";
BA_ "ValueTableE" SG_ 420 VSA_LAMP_STATUS_HDC_2 "1: HDC Standby";
BA_ "DescriptionE" SG_ 420 VSA_WARN_STATUS_HDC_2 "HDC Warn Status";
BA_ "ValueTableE" SG_ 420 VSA_WARN_STATUS_HDC_2 "1: HDC MID warning ON";
BA_ "GenSigStartValue" SG_ 420 VSA_AHA_CTRL_2 1;
BA_ "DescriptionE" SG_ 420 VSA_AHA_CTRL_2 "DWTB Control Active";
BA_ "ValueTableE" SG_ 420 VSA_AHA_CTRL_2 "1: DWTB CTRL Active";
BA_ "ValueTableE" SG_ 420 VSA_WARN_STATUS_PUNCTURE_2 "1: ABS control active";
BA_ "ValueTableE" SG_ 420 VSA_WARN_STATUS_DWS_2 "1: ABS control active";
BA_ "ValueTableE" SG_ 420 VSA_ANSWER_DWS_INIT_REQ_2 "1: ABS control active";
BA_ "ValueTableE" SG_ 420 VSA_L_MODE_ABS_EBD_2 "1: ABS, EBD L-MODE";
BA_ "DescriptionE" SG_ 420 VSA_ALIVE_COUNTER_1A4_2 "Incremented by 1 every time a packet is refreshed.

(0 to 3 ring counters)";
BA_ "ValueTableE" SG_ 420 VSA_ABS_CTRL_2 "1: ABS control active";
BA_ "ValueTableE" SG_ 420 VSA_VSA_CTRL_2 "1: VSA control active";
BA_ "ValueTableE" SG_ 420 VSA_WARN_STATUS_HSA_2 "1: HSA warning is illuminated";
BA_ "ValueTableE" SG_ 420 VSA_ESS_ACT4_2 "0: The continuation of an operation of ESS by ABS full cycle is forbidden.

1: The continuation of an operation of ESS by ABS full cycle is permitted.";
BA_ "DescriptionE" SG_ 420 VSA_ESS_ACT4_2 "When a head-on collision is detected, '1' is sent with each message which is output 10 times continuously.";
BA_ "ValueTableE" SG_ 420 VSA_ESS_ACT3_2 "0: The operation start of ESS by  ABS full cycle is forbidden.

1: The operation start of ESS by  ABS full cycle is permitted.";
BA_ "ValueTableE" SG_ 420 VSA_REWRITE_START_2 "1: Start VSA reprogramming at dealer";
BA_ "DescriptionE" SG_ 420 VSA_REWRITE_START_2 "VSA ECU reprogramming start flag";
BA_ "ValueTableE" SG_ 420 VSA_BUZZER_STATUS_2 "0: Buzzer OFF

1: Buzzer ON";
BA_ "ValueTableE" SG_ 420 VSA_MID_REQUEST_VSA_2 "1: Display VSA MID enlarged warning";
BA_ "DescriptionE" SG_ 420 VSA_MID_REQUEST_VSA_2 "VSA MID enlarged warning output flag ";
BA_ "GenSigStartValue" SG_ 420 VSA_LAMP_STATUS_VSA_OFF_2 1;
BA_ "ValueTableE" SG_ 420 VSA_LAMP_STATUS_VSA_OFF_2 "1: VSA OFF lamp ON";
BA_ "GenSigStartValue" SG_ 420 VSA_WARN_STATUS_VSA_2 1;
BA_ "ValueTableE" SG_ 420 VSA_WARN_STATUS_VSA_2 "1: VSA warning lamp ON";
BA_ "GenSigStartValue" SG_ 420 VSA_WARN_STATUS_ABS_2 1;
BA_ "ValueTableE" SG_ 420 VSA_WARN_STATUS_ABS_2 "1: ABS warning lamp ON";
BA_ "GenSigStartValue" SG_ 420 VSA_WARN_STATUS_BRAKE_2 1;
BA_ "ValueTableE" SG_ 420 VSA_WARN_STATUS_BRAKE_2 "1: Brake warning lamp ON";
BA_ "ValueTableE" SG_ 420 VSA_VSA_TCS_ACT_2 "1: VSA, TCS active";
BA_ "DescriptionE" SG_ 420 VSA_VSA_TCS_ACT_2 "If the TSA?becomes active and the brake lamp turns ON, the bit must be turned 1.";
BA_ "ValueTableE" SG_ 420 VSA_ABS_EBD_ACT_2 "1: ABS, EBD active";
BA_ "ValueTableE" SG_ 420 VSA_VSA_TCS_MIL_2 "1: VSA, TCS failure";
BA_ "ValueTableE" SG_ 420 VSA_ABS_EBD_MIL_2 "1: ABS, EBD failure";
BA_ "ValueTableE" SG_ 420 VSA_CASEN_2 "1: Permit CAS operation";
BA_ "ValueTableE" SG_ 420 VSA_CAS_ACT_2 "1:  CAS active";
BA_ "ValueTableE" SG_ 420 VSA_BA_ACT_2 "1: BA active ";
BA_ "GenSigStartValue" SG_ 420 VSA_MASTER_CYLINDER_PRESSURE_2 4095;
BA_ "ValueTableE" SG_ 420 VSA_MASTER_CYLINDER_PRESSURE_2 "0066: 0kPa

0399: 19623.24kPa";
BA_ "ValueTableE" SG_ 420 VSA_ESS_ACT2_2 "0: The continuation of an operation of ESS by deceleration is forbidden.

1: The continuation of an operation of ESS by deceleration is permitted.";
BA_ "ValueTableE" SG_ 420 VSA_ESS_ACT1_2 "0: The operation start of ESS by deceleration is forbidden.

1: The operation start of ESS by deceleration is permitted.";
BA_ "DescriptionE" SG_ 145 VSA_ALIVE_COUNTER_091_2 "Incremented by 1 every time a packet is refreshed.

(0 to 3 ring counters)";
BA_ "GenSigStartValue" SG_ 145 VSA_SENSOR_START_UP_2 1;
BA_ "DescriptionE" SG_ 145 VSA_SENSOR_START_UP_2 "During start-up process";
BA_ "DescriptionE" SG_ 145 VSA_SENSOR_ERR_MC_2 "Abnormal CPU";
BA_ "DescriptionE" SG_ 145 VSA_SENSOR_STATE_IG_2 "Abnormal supply voltage";
BA_ "DescriptionE" SG_ 145 VSA_P_ERR_YAW1_2 "YAW 1 failure";
BA_ "DescriptionE" SG_ 145 VSA_T_ERR_YAW1_2 "Temporarily abnormal YAW1";
BA_ "GenSigStartValue" SG_ 145 VSA_LON_G_2 511.99999465;
BA_ "GenSigStartValue" SG_ 145 VSA_LAT_G_2 511.99999465;
BA_ "GenSigStartValue" SG_ 145 VSA_DEGC_2 103;
BA_ "GenSigStartValue" SG_ 145 VSA_YAW_1_2 512;
BA_ "DescriptionE" SG_ 145 VSA_YAW_1_2 "YAW1 data

* Refer to the attachment for the definition of the output.

* Refer to SPEC for the guarantee range.";
VAL_ 3221225472 VSA_INH_MODE13_2 1 "Mode prohibited for VSA" 0 "Mode available for VSA" ;
VAL_ 3221225472 VSA_INH_MODE15_2 1 "Mode prohibited for VSA" 0 "Mode available for VSA" ;
VAL_ 3221225472 VSA_INH_MODE14_2 1 "Mode prohibited for VSA" 0 "Mode available for VSA" ;
VAL_ 3221225472 VSA_INH_MODE6_2 1 "Mode prohibited for VSA" 0 "Mode available for VSA" ;
VAL_ 3221225472 VSA_INH_MODE5_2 1 "Mode prohibited for VSA" 0 "Mode available for VSA" ;
VAL_ 3221225472 VSA_INH_MODE4_2 1 "Mode prohibited for VSA" 0 "Mode available for VSA" ;
VAL_ 3221225472 VSA_INH_MODE_CHANGE_2 1 "Mode change prohibited for VSA" 0 "Mode change allowed for VSA" ;
VAL_ 3221225472 VSA_INH_MODE0_2 1 "Mode prohibited for VSA" 0 "Mode available for VSA" ;
VAL_ 3221225472 VSA_INH_MODE1_2 1 "Mode prohibited for VSA" 0 "Mode available for VSA" ;
VAL_ 3221225472 VSA_INH_MODE2_2 1 "Mode prohibited for VSA" 0 "Mode available for VSA" ;
VAL_ 3221225472 VSA_INH_MODE3_2 1 "Mode prohibited for VSA" 0 "Mode available for VSA" ;
VAL_ 3221225472 VSA_INH_MODE7_2 1 "Mode prohibited for VSA" 0 "Mode available for VSA" ;
VAL_ 3221225472 ENG_CAS_REQ_2 1 "CAS is requested" 0 "CAS is NOT requested" ;
VAL_ 2209174799 VSA_MAC_stRegMacKey_2 7 "Reserved" 6 "Reserved" 5 "Reserved" 4 "Failed" 3 "Pre-Failed" 2 "Pre-Passed" 1 "Passed" 0 "Initial" ;
VAL_ 2209174799 VSA_MAC_stCompMacAccum_2 3 "Failed" 2 "Pre-Failed" 1 "Not-Failed" 0 "Initial" ;
VAL_ 2209174799 VSA_MAC_stCompMacCont_2 7 "Passed" 6 "Pre-Passed" 5 "Reserved" 4 "Initial" 3 "Reserved" 2 "Pre-Failed" 1 "Failed" 0 "Reserved" ;
VAL_ 2209174799 VSA_MAC_stGenMac_2 7 "Reserved" 6 "Reserved" 5 "Reserved" 4 "Failed" 3 "Pre-Failed" 2 "Pre-Passed" 1 "Passed" 0 "Initial" ;
VAL_ 777 METER_SPEED_UNIT_2 1 "km/h" 0 "mph" ;
VAL_ 1619 VSA_DTC_SYSTEM_DESIGNATOR_BIT_2 1 "Honda DTC" 0 "SAE code" ;
VAL_ 1619 VSA_DTC_STORAGE_STATUS_2 1 "When confirmed DTC is stored" 0 "When confirmed DTC is not stored" ;
VAL_ 1619 VSA_FTB_STATUS_BIT_2 1 " FTB used" 0 "Do not use FTB" ;
VAL_ 546 METER_IDS_MODE_2 3 "Sport +

" 2 "Comfort

" 1 "Sport

" 0 "Normal

" ;
VAL_ 845 VSA_VSA_MODE_STATUS_2 7 "Diagnostic Mode Active

" 6 "Dyno Mode 2 Active

" 5 "Dyno Mode 1 Active

" 4 "OFF Prohibition Mode Active

" 3 "VSA OFF Active

" 2 "TCS OFF Active

" 1 "Maintenance Mode Active

" 0 "VSA Mode Not Active

" ;
VAL_ 489 RTC_T_FAIL_STATUS_2 1 "No reliability" 0 "Reliable" ;
VAL_ 489 RTC_P_FAIL_STATUS_2 1 "RTC system fault determination" 0 "RTC system normal" ;
VAL_ 489 RTC_STATUS_INVALID_2 1 "RTC fault status invalid" 0 "RTC fault status valid" ;
VAL_ 489 RTC_OFF_STATUS_2 1 "RTC OFF state" 0 "RTC ON state" ;
VAL_ 446 EBB_BRAKE_PEDAL_ON_STATUS 3 "Reserved" 2 "Failure" 1 "Normal" 0 "Initialization" ;
VAL_ 446 EBB_BRAKE_PEDAL_ON 1 "Driver is operating brake pedal." 0 "Except the above" ;
VAL_ 446 EBB_STATUS_1BE_2 7 "Normal" 6 "Post running" 5 "Torq limit in low volt/high temp" 4 "CAN signal failure" 3 "Reserved" 2 "Diagnosis mode" 1 "Failure" 0 "Initialization" ;
VAL_ 1108 ENG_FAIL_PA_2 1 "PA sensor fails. 

" 0 "PA sensor does NOT fail. " ;
VAL_ 1571 VSA_ID_2 1 "Valid" 0 "Invalid" ;
VAL_ 1302 METER_UNDER10V_516_2 1 "Less than 10V" 0 "10V or more" ;
VAL_ 1568 BCM_ID_REQ_VSA_REC_2 1 "Tx fr immobilizer authnticatn" ;
VAL_ 1568 BCM_ID_REQ_VSA_2 1 "Tx fr immobilizer authnticatn" ;
VAL_ 231 EBB_EXTREQ_CTRL_STATUS_2 7 "Description for the value '0x7'" 6 "Reserved" 5 "Reserved" 4 "In control( functional limit)" 3 "In control" 2 "Operation possible" 1 "Operation impossible" 0 "Initialization" ;
VAL_ 231 EBB_WARN_STATUS_BRAKESYSTEM_2 1 "BRAKE SYSTEM warning lamp is ON" 0 "BRAKE SYSTEM warning lamp is OFF" ;
VAL_ 231 EBB_OUTPUTROD_STATUS_2 3 "Reserved" 2 "Failure" 1 "Normal" 0 "Initialization" ;
VAL_ 231 EBB_EXTREQ_CTRL_2 1 "In external brake control" 0 "Not in external brake control" ;
VAL_ 929 METER_DWS_INIT_REQ_SW_2 1 "DWS initialization req" 0 "No DWS initialization req" ;
VAL_ 929 METER_DWS_INIT_REQ_2 1 "Req for DWS initializtn" 0 "No Req for DWS initializtn" ;
VAL_ 806 METER_R_SCROLL_PUSH_2 1 "Steering switch ON" 0 "Steering switch OFF" ;
VAL_ 806 METER_SW_STATUS_VSA_2 1 "VSA ON request" 0 "VSA OFF request" ;
VAL_ 806 METER_SW_STATUS_PARK_BRAKE_2 1 "Parking Brake ON" 0 "Parking Brake OFF" ;
VAL_ 806 METER_SW_STATUS_BRAKE_FLUID_2 1 "Brake fluid level ON" 0 "Brake fluid level OFF" ;
VAL_ 806 METER_SW_STATUS_VSA_OFF_2 1 "VSA OFF switch ON" 0 "VSA OFF switch OFF" ;
VAL_ 806 METER_RL_STATUS_2 1 "Backlight switch ON" 0 "Backlight switch OFF" ;
VAL_ 806 METER_SW_STATUS_BHOLD_2 3 "Description for the value '0x3'" 2 "Brake hold switch disconnection" 1 "Brake hold switch ON" 0 "Brake hold switch OFF" ;
VAL_ 469 EBB_STATUS_2 7 "Normal" 6 "Post running" 5 "Torq limit in low volt/high temp" 4 "CAN signal failure" 3 "Reserved" 2 "Diagnosis mode" 1 "Failure" 0 "Initialization" ;
VAL_ 469 EBB_BRAKE_PEDAL_ON_2 1 "Driver is operating brake pedal." 0 "Except the above" ;
VAL_ 469 EBB_BRAKE_PEDAL_ON_STATUS_2 3 "Reserved" 2 "Failure" 1 "Normal" 0 "Initialization" ;
VAL_ 469 EBB_RUNOUT_STATUS_2 3 "Reserved" 2 "Failure" 1 "Normal" 0 "Initialization" ;
VAL_ 232 VSA_EXTERNAL_PRESSURE_ACTIVE_2 3 "Reserved" 2 "AEB in progress" 1 "Automatic brake in progress" 0 "External brake not under control" ;
VAL_ 232 VSA_VEHICLE_SPEED_STATUS_2 3 "Reserved" 2 "Failure" 1 "Normal" 0 "Initialization" ;
VAL_ 199 VSA_MAX_PRESSURE_STATUS_0C7_2 3 "Reserved" 2 "Failure" 1 "Normal" 0 "initialization" ;
VAL_ 199 VSA_IG_ON_0C7_2 1 "on" 0 "off" ;
VAL_ 199 VSA_DIAG_STATUS_0C7_2 1 "Into diagnosis mode" 0 "Except the above" ;
VAL_ 199 VSA_ABS_CTRL_0C7_2 1 "In ABS control" 0 "Not in ABS control" ;
VAL_ 199 VSA_FAIL_MC_PRESSRE_SENSOR_0C7_2 1 "Sensor is faulty" 0 "Sensor is normal" ;
VAL_ 131 IMG_BRKMODE_HLD_STATUS_2 3 "Reserved" 2 "Reserved" 1 "Switch ISAB" 0 "Switch IMG Not Control" ;
VAL_ 424 BRK_HDC_ACT_1A8_2 1 "HDC Control is Active" 0 "HDC Control is NOT Active" ;
VAL_ 424 BRK_HDC_FAIL_1A8_2 1 "HDC Control Request is Refused" 0 "HDC Control Request is Permitted" ;
VAL_ 424 BRK_HDC_WAIT_1A8_2 1 "HDC Control Request is inhibited" 0 "HDC Control Request is Permitted" ;
VAL_ 262 VSA_HDC_REQ_ACT_2 1 "HDC Control is required" 0 "HDC Control is NOT required" ;
VAL_ 479 IDAS_CRUISE_ACTIVE 1 "active" 0 "Not active

" ;
VAL_ 479 IDASB_INFO_IND_WARNING_2 3 "Reserved" 2 "Reserved" 1 "BRAKE’ is lit

" 0 "No display

" ;
VAL_ 479 IDAS_REQ_EPB_ACT_2 1 "EPB actuation requested

" 0 "Not requested

" ;
VAL_ 479 IDAS_STATUS_FAIL_AEB_2 1 "CMBS status faulty

" 0 "CMBS control normal

" ;
VAL_ 479 IDAS_STATUS_FAIL_ACC_2 1 "ACC/LSF/RDM faulty

" 0 "ACC/LSF/RDM control normal" ;
VAL_ 479 IDAS_REQ_BRAKE_RELEASE_2 1 "Brake release requested

" 0 "Not requested

" ;
VAL_ 479 IDAS_REQ_STOP_BRAKE_2 1 "Stop requested

" 0 "Not requested

" ;
VAL_ 479 IDAS_REQ_ACC_BRAKE_CTRL_2 1 "ACC control requested

" 0 "Not requested

" ;
VAL_ 479 IDAS_REQ_AEB_BRAKE_CTRL_2 1 "CMBS control requested

" 0 "Not requested

" ;
VAL_ 479 IDAS_REQ_PREFILL_2 1 "Prefill control requested

" 0 "Not requested

" ;
VAL_ 423 EAT_FAILURE_FOR_EPB_2 1 "fault affecting EPB" 0 "No failure" ;
VAL_ 423 EAT_ATRVS_SW_STATUS_2 1 "RVS switch ON" 0 "RVS switch OFF" ;
VAL_ 423 EAT_ATFWD_SW_STATUS_2 1 "FWD switch ON" 0 "FWD switch OFF" ;
VAL_ 57 SRS_CDS_REAR_2 1 "Collision ON" 0 "Collision OFF" ;
VAL_ 57 SRS_CDS_SIDE_2 1 "Collision ON" 0 "Collision OFF" ;
VAL_ 57 SRS_CDS_FRONT_2 1 "Collision ON" 0 "Collision OFF" ;
VAL_ 773 SRS_DR_BELT_STATUS_2 3 "Drivr seat belt switch fail

" 2 "Driver seat belt buckled  

" 1 "Driver seat belt not buckled" 0 "Drivr belt cant determined  " ;
VAL_ 773 SRS_DR_BELT_2 1 "Driver-side seat belt warning

" 0 "No driver seat belt warning  

" ;
VAL_ 320 ENG_REQUEST_EPB_ACT_2 1 "EPB operation request ON" 0 "EPB operation request OFF" ;
VAL_ 320 ENG_DEC_NSS_BHOLD_2 1 "shift position is neutral" 0 "shift position is not neutral" ;
VAL_ 1928 VSA_CAL_YAWG_CANCEL_2 1 "Calibration cancel requested" 0 "Calibration cancel not requested" ;
VAL_ 1928 VSA_CAL_YAW_START_2 1 "Calibration is requested" 0 "Calibration not requested" ;
VAL_ 1928 VSA_CAL_YAW_CLEAR_2 1 "Calibration is requested" 0 "Calibration not requested" ;
VAL_ 1928 VSA_CAL_LONG_START_2 1 "Calibration is requested" 0 "Calibration not requested" ;
VAL_ 1928 VSA_CAL_LONG_CLEAR_2 1 "Calibration is requested" 0 "Calibration not requested" ;
VAL_ 1928 VSA_CAL_LATG_START_2 1 "Calibration is requested" 0 "Calibration not requested" ;
VAL_ 1928 VSA_CAL_LATG_CLEAR_2 1 "Calibration is requested" 0 "Calibration not requested" ;
VAL_ 148 SRS_POST_COLLISION_BRK_FAILURE_2 1 "Collision detection func fail" 0 "Collision detection func normal" ;
VAL_ 148 SRS_POST_COLLISION_BRK_2 3 "COLLISION_HI" 2 "COLLISION_MID" 1 "COLLISION_LO" 0 "OFF" ;
VAL_ 148 SRS_SENSOR_STATE_IG_2 1 "volt cant protect func of sensor" 0 "Normal time" ;
VAL_ 148 SRS_SENSOR_START_UP_2 1 "During start check" 0 "start check normal" ;
VAL_ 148 SRS_SENSOR_ERR_MC_2 1 "Fault confirmed by diag" 0 "Normal time" ;
VAL_ 148 SRS_T_ERR_YAW1_2 1 "YAW1 cannot be guaranteed" 0 "Normal Time" ;
VAL_ 148 SRS_T_ERR_LON_G_2 1 "Acceleratn cant be guaranteed" 0 "Normal time" ;
VAL_ 148 SRS_T_ERR_LAT_G_2 1 "Acceleratn cant be guaranteed" 0 "Normal time" ;
VAL_ 148 SRS_T_ERR_DEGC_2 1 "Temp data cant be guaranteed" 0 "Normal time" ;
VAL_ 148 SRS_P_ERR_YAW1_2 1 "failure of yaw rate is fixed" 0 "Normal time" ;
VAL_ 148 SRS_P_ERR_LON_G_2 1 "front/rear G accelratn confirmed" 0 "Normal time" ;
VAL_ 148 SRS_P_ERR_LAT_G_2 1 "lateral G acceleration is fixed" 0 "Normal time" ;
VAL_ 148 SRS_P_ERR_DEGC_2 1 "temp data is fixed" 0 "Normal time" ;
VAL_ 148 SRS_CAL_YAW_2 1 "sensor calib complete." 0 "sensor calib not complete." ;
VAL_ 148 SRS_CAL_LON_G_2 1 "sensor calib complete." 0 "sensor calib not complete." ;
VAL_ 148 SRS_CAL_LAT_G_2 1 "sensor calib complete." 0 "sensor calib not complete." ;
VAL_ 486 RTC_T_FAIL_STATUS_2 1 "No reliability" 0 "Reliable" ;
VAL_ 486 RTC_P_FAIL_STATUS_2 1 "RTC system fault determination" 0 "RTC system normal" ;
VAL_ 486 RTC_STATUS_INVALID_2 1 "RTC fault status invalid" 0 "RTC fault status valid" ;
VAL_ 330 EPS_STR_START_UP_2 1 "During initialization" 0 "Initialization is completed" ;
VAL_ 795 VSA_MID_WARN_STATUS_DWS_INIT_2 1 "DWS/iDWS MID is enabled" 0 "DWS/iDWS MID is disabled" ;
VAL_ 795 VSA_REJECT_OFF_SW_OPTN_MID_2 1 "Reject OFF SW Operation MID is enabled" 0 "Reject OFF SW Operation MID is disabled" ;
VAL_ 795 VSA_DWS_AUTOJUDGE_2 1 "DWS/iDWS function is applied" 0 "DWS/iDWS function is not applied" ;
VAL_ 795 VSA_MID_REQ_HDC_SW_STATUS_2 3 "HDC control state is active" 2 "HDC control state is standby" 1 "HDC control state is OFF" 0 "Non Display" ;
VAL_ 795 VSA_HDC_CONTROL_STATUS_2 2 "HDC control state is active" 1 "HDC control state is standby" 0 "HDC control state is OFf" ;
VAL_ 795 VSA_HDC_SPEED_UNIT_2 1 "km/h" 0 "mph" ;
VAL_ 795 VSA_MID_HDC_OP_GUIDE_2 5 "Reserve" 4 "HDC is standy " 3 "HDC off due to vehicle speed" 2 "HDC can't due to vehicle speed" 1 "HDC can't due to ACC/LFC active" 0 "No Display" ;
VAL_ 795 VSA_MID_REQUEST_IDS_2 5 "Reserved" 4 "TRAIL MID enabled

" 3 "TRACK MID enabled

" 2 "MUD MID enabled

" 1 "SAND MID enabled

" 0 "IDS MID disabled

" ;
VAL_ 795 VSA_MID_REQUEST_VSA_OFF_2 1 "MID Warning Enabled" 0 "MID Warning Disabled" ;
VAL_ 795 VSA_MID_REQUEST_TCS_OFF_2 1 "MID Warning Enabled" 0 "MID Warning Disabled" ;
VAL_ 795 VSA_MID_REQ_EPB_MISOP_GUIDE_2 3 "Reserved" 2 "Brake pedal is NOT pressed" 1 "Seatbelt is NOT fastened" 0 "No display " ;
VAL_ 795 VSA_MID_LMP_STATS_OPRTE_BHOLD_2 1 "MID Warning Enabled" 0 "MID Warning Disabled" ;
VAL_ 795 VSA_MID_LAMP_STATUS_HDC_OFF_2 1 "MID Warning Enabled" 0 "MID Warning Disabled" ;
VAL_ 795 VSA_WARN_STATUS_HDC_2 1 "MID Warning Enabled" 0 "MID Warning Disabled" ;
VAL_ 795 VSA_MID_WARN_STATUS_TSA_2 1 "MID Warning Enabled" 0 "MID Warning Disabled" ;
VAL_ 795 VSA_MID_WARN_STATUS_BRAKESYSTM_2 1 "MID Warning Enabled" 0 "MID Warning Disabled" ;
VAL_ 795 VSA_WARN_STATUS_HSA_31B_2 1 "MID Warning Enabled" 0 "MID Warning Disabled" ;
VAL_ 795 VSA_MID_WARN_STATUS_BRAKE_2 1 "MID Warning Enabled" 0 "MID Warning Disabled" ;
VAL_ 795 VSA_MID_WARN_STATUS_ABS_2 1 "MID Warning Enabled" 0 "MID Warning Disabled" ;
VAL_ 795 VSA_MID_REQUEST_VSA_31B_2 1 "MID Warning Enabled" 0 "MID Warning Disabled" ;
VAL_ 795 VSA_MID_LAMP_STATUS_VSA_OFF_2 1 "MID Warning Enabled" 0 "MID Warning Disabled" ;
VAL_ 795 VSA_MID_REQ_BHOLD_STANDBY_2 1 "Brake hold in standby mode

" 0 "Brake hold NOT in standby mode" ;
VAL_ 795 VSA_MID_REQ_BHOLD_EPB_OP_INFO_2 1 "BHOLD transtn to EPB MID

" 0 "Do not display. " ;
VAL_ 795 VSA_MID_REQ_BHOLD_MISOP_GUIDE_2 3 "Description for the value '3'" 2 "Bhold exit condtn unsatisfied " 1 "Bhold enter condtn unsatisfied " 0 "No Display" ;
VAL_ 795 VSA_MID_REQ_BHOLD_APPLY_BRAKE_2 1 "Brake pedal apply request is ON" 0 "No Display" ;
VAL_ 795 VSA_WARN_STATUS_BHOLD_2 1 "MID Warning Enabled" 0 "MID Warning Disabled" ;
VAL_ 795 VSA_MID_WARN_STATUS_DWS_2 1 "MID Warning Enabled" 0 "MID Warning Disabled" ;
VAL_ 795 VSA_MID_WARN_STATUS_PUNCTURE_2 1 "MID Warning Enabled" 0 "MID Warning Disabled" ;
VAL_ 387 ESB_REQ_BRAKERELAY_ACT_2 1 "Relay operation required" 0 "No Relay operation required" ;
VAL_ 387 AHB_WARN_STATUS_SYSTEM_2 1 "Brk sys warn light frm ESB req" 0 "No Brk warn light frm ESB req" ;
VAL_ 387 AHB_HBC_REQ_2 1 "HBC ctrl for VSA is requested" 0 "No HBC ctrl for VSA is requested" ;
VAL_ 387 AHB_VSACHG_FAIL_2 1 "VSA cooperative ctrl impossible" 0 "VSA cooperative ctrl possible" ;
VAL_ 387 AHB_BPS_FAIL_2 1 "Stroke sensor error" 0 "Stroke sensor Normal" ;
VAL_ 387 AHB_VSA_INCREASE_PRESS_ACT_2 1 "ESB on automatic press ctrl" 0 "ESB not on automatic press ctrl" ;
VAL_ 419 TM_BRAKE_HOLD_REQ_VSA_2 1 "Parking Assist brk required " 0 "Parking Assist brk NOT required " ;
VAL_ 419 TM_SW_STATUS_SMODE_2 1 "SMODE

" 0 "NORMAL MODE" ;
VAL_ 419 TM_FAILURE_FOR_VSA_2 1 "TM failure." 0 "TM normal" ;
VAL_ 419 TM_GEAR_POSITION_TARGET_2 15 "Invalid" 14 "Unknown" 13 "Unknown" 12 "Unknown" 11 "Unknown" 10 "Reverse" 9 "9th" 8 "8th" 7 "7th" 6 "6th" 5 "5th" 4 "4th" 3 "3rd" 2 "2nd" 1 "1st" 0 "Neutral" ;
VAL_ 419 TM_GEAR_POSITION_IND_2 15 "Unknown" 14 "Unknown" 13 "Unknown" 12 "Unknown" 11 "Unknown" 10 "Unknown" 9 "9th" 8 "8th" 7 "7th" 6 "6th" 5 "5th" 4 "4th" 3 "3rd" 2 "2nd" 1 "1st" 0 "Neutral" ;
VAL_ 419 TM_GEAR_POSITION_ACTUAL_2 15 "Invalid" 14 "Unknown" 13 "Unknown" 12 "Unknown" 11 "Shifting" 10 "Reverse" 9 "9th" 8 "8th" 7 "7th" 6 "6th" 5 "5th" 4 "4th" 3 "3rd" 2 "2nd" 1 "1st" 0 "Neutral

" ;
VAL_ 538 VSA_REQ_BRAKERELAY_ACT_2 1 "Brake Lamp Relay Request active" 0 "Brke Lamp Relay Request inactive" ;
VAL_ 538 VSA_ESB_LON_G_FAIL_2 1 "Longitudinal G sensor is failed" 0 "Longitudinal G sensor NOT failed" ;
VAL_ 538 VSA_ESB_LON_G_INH2_2 1 "Long G sensor cant be guaranteed" 0 "Long G sensor can be guaranteed" ;
VAL_ 538 VSA_ESB_LON_G_INH1_2 1 "Long G sensor cant be guaranteed" 0 "Long G sensor can be guaranteed" ;
VAL_ 538 VSA_INHIBIT_BRKRLY_DIAG_ESB_2 1 "Brke Lmp Relay Failsafe inactive" 0 "Brake Lmp Relay Failsafe active" ;
VAL_ 470 ENG_ISAB_REQUEST_1D6_2 1 " ISAB activation required

" 0 "ISAB activation NOT required

" ;
VAL_ 422 METER_SW_STATUS_HIL_CONTRL_1A6_2 3 "Switch ground fault" 2 "Switch disconnection" 1 "Switch ON" 0 "Switch OFF" ;
VAL_ 422 METER_SW_STATUS_BHOLD_1A6_2 3 "Description for the value '0x3'" 2 "Brake hold switch disconnection" 1 "Brake hold switch ON" 0 "Brake hold switch OFF" ;
VAL_ 422 METER_RL_STATUS_1A6_2 1 "Backlight switch ON" 0 "Backlight switch OFF" ;
VAL_ 422 METER_SW_STATUS_VSA_OFF_1A6_2 1 "VSA OFF switch ON" 0 "VSA OFF switch OFF" ;
VAL_ 422 METER_SW_STATUS_PARK_BRAKE_1A6_2 1 "Parking Brake ON" 0 "Parking Brake OFF" ;
VAL_ 422 METER_SW_STATUS_BRKE_FLUID_1A6_2 1 "Brake fluid level ON" 0 "Brake fluid level OFF" ;
VAL_ 1424 VSA_FTB_STATUS_BIT_2 1 " FTB used" 0 "Do not use FTB" ;
VAL_ 1424 VSA_DTC_SYSTEM_DESIGNATOR_BIT_2 1 "Honda DTC" 0 "SAE code" ;
VAL_ 1424 VSA_DTC_STORAGE_STATUS_2 1 "When confirmed DTC is stored" 0 "When confirmed DTC is not stored" ;
VAL_ 661 METER_SW_STATUS_HIL_CONTRL_295_2 3 "Switch ground fault" 2 "Switch disconnection" 1 "Switch ON" 0 "Switch OFF" ;
VAL_ 661 METER_DWS_INIT_REQ_SW_2 1 "DWS init req with init switch" 0 "No DWS init req with init switch" ;
VAL_ 661 METER_DWS_INIT_REQ_2 1 "Req for DWS initializtn" 0 "No Req for DWS initializtn" ;
VAL_ 488 VSA_HDC_REQ_ACT_1E8_2 1 "HDC Control is required" 0 "HDC Control is NOT required" ;
VAL_ 426 VSA_IG_ON_2 1 "VSA IG ON" 0 "VSA IG OFF

" ;
VAL_ 426 VSA_IDS_INHIBIT_DISABLED_STATE_2 1 "VSA function is disabled

" 0 "VSA function is enabled

" ;
VAL_ 426 VSA_IDS_INHIBIT_ACT_2 1 "functions under activation" 0 "other" ;
VAL_ 426 VSA_EBB_FAILURE_FOR_IS_2 1 "EBB CPU failure 

" 0 "Normal" ;
VAL_ 426 VSA_HAC_CUT_REQ_2 1 "AC cut Request 

" 0 "No request

" ;
VAL_ 426 VSA_HBB_IS_REFUSE_REQ_2 1 "Idle Stp Prohibitn Req" 0 "No request" ;
VAL_ 426 VSA_LOW_VAC_IS_SHFT_INHBIT_REQ_2 1 "Idle Stp Prohibitn Req" 0 "No request" ;
VAL_ 426 VSA_HBB_IS_SHIFT_INHIBIT_REQ_2 1 "Idle Stp Prohibitn Req" 0 "No request" ;
VAL_ 426 VSA_MNTMODE_STATUS_2 1 "VSA maintenance mode

" 0 "NOT in  VSA maintenance mode

" ;
VAL_ 426 VSA_REVERSE_SWITCH_FAIL_2 1 "Back light switch fails" 0 "Back light switch does NOT fail" ;
VAL_ 426 VSA_SHFT_IN_REVERSE_2 1 "Back light switch is ON. " 0 "Back light switch is OFF" ;
VAL_ 426 VSA_ECD_ACT_2 1 "EPB fluid pres ctrl ongoing 

" 0 "ctrl not ongoing 

" ;
VAL_ 426 VSA_FAIL_FOR_EPB_2 1 "Abnormal" 0 "Normal" ;
VAL_ 426 VSA_REQUEST_EPB_ACT_2 1 "EPB activation request ON " 0 "EPB activation request OFF " ;
VAL_ 426 VSA_EPB_INHIBIT_BRAKE_2 1 "Temporarily prohibited" 0 "Permitted" ;
VAL_ 426 VSA_EPB_REFUSE_BRAKE_2 1 "Prohibited" 0 "Permitted" ;
VAL_ 426 VSA_TM_SUPPORT_BRKE_REFUSE_1AA_2 1 "TM supprt brk req not accepted

" 0 "TM support brk req is accepted

" ;
VAL_ 426 VSA_IS_RESTART_INHIBIT_REQ_1AA_2 1 "Idle Stp Prohibitn Req" 0 "No request" ;
VAL_ 426 VSA_ISAB_ACT_1AA_2 1 "In ISAB control

" 0 "NOT in ISAB control" ;
VAL_ 426 VSA_BTCS_ACT_1AA_2 1 "Brake-TCS is active

" 0 "Brake-TCS is NOT active

" ;
VAL_ 426 VSA_ISAB_ENABLE_1AA_2 1 "permitted" 0 "prohibited" ;
VAL_ 426 VSA_IS_SHFT_INHBIT_REQUEST_1AA_2 1 "Idle Stp Prohibitn Req" 0 "No request" ;
VAL_ 426 VSA_SHIFT_REQ_1AA_2 3 "Description for the value '0x3'" 2 "Shift up request 

" 1 "Shift hold request

" 0 "No shift ctrl request from VSA " ;
VAL_ 426 VSA_TRQ_DOWN_REQ_FUEL_CUT_1AA_2 3 "Reserved" 2 "All-cylinders F/C + ig retard 

" 1 "Ignition retard 

" 0 "No fuel/ignition control " ;
VAL_ 426 VSA_REQ_MSR_PLUS_TRQ_1AA_2 1 "Plus torque is requested

" 0 "No request" ;
VAL_ 426 VSA_TRQ_CONTROL_MODE_1AA_2 3 "VSA/TCS prohibited " 2 "Acceleration control ongoing 

" 1 "MSR control ongoing " 0 "No VSA/TCS control 

" ;
VAL_ 506 ACC_REQ_BRAKERELAY_ACT_2 1 "Relay operation required" 0 "No relay operation request" ;
VAL_ 506 ACC_LSF_BHOLD_ACT_2 1 "Stop hold control in progress" 0 "Stop hold ctrl not in progress" ;
VAL_ 506 ACC_REWRITE_START_2 1 "ACC_ECU rewrite start" 0 "ACC_ECU not being rewritten" ;
VAL_ 506 ACC_STATUS_FAIL_ACC_2 1 "ACC fail" 0 "ACC operation normal" ;
VAL_ 506 ACC_STATUS_FAIL_CVRS_BRAKE_2 1 "Collision reduction brking fail" 0 "Colision reduction brking normal" ;
VAL_ 506 ACC_TARGET_MOT_LEVEL_2 7 "Reserved" 6 "Req frm rear-end reduction brk" 5 "Reserved" 4 "Reserved" 3 "Reserved" 2 "Request from ACC(B)" 1 "Request from ACC(A)" 0 "No request from ACC" ;
VAL_ 506 ACC_EPB_ACT_REQ_2 1 "Request foe EPB operation" 0 "No request" ;
VAL_ 506 ACC_STATUS_REQ_ACC_BRAKE_2 1 "ACC control requested" 0 "No ACC control request" ;
VAL_ 506 ACC_STATUS_REQ_CVRS_BRAKE_2 1 "Colision reductn brk ctrl req" 0 "No rearend colision brk ctrl req" ;
VAL_ 316 ENG_IG1_10V_STATUS_2 1 "ENG IG1>=10V" 0 "ENG IG1 < 10V" ;
VAL_ 316 ENG_CLUTCH_SW_SIL_2 1 "Clutch pedal is NOT depressed" 0 "Clutch pedal is depressed" ;
VAL_ 316 ENG_BRK_ACCELE_PEDAL_ON_13C_2 1 "accele pedal stepped on." 0 "accele pedal not stepped on." ;
VAL_ 316 ENG_CAS_REQ_13C_2 1 "CAS is requested" 0 "CAS is NOT requested" ;
VAL_ 316 ENG_NEUTRAL_SENSOR_FAIL_13C_2 1 "NEUTRAL SENSOR failure" 0 "NEUTRAL SENSOR normal" ;
VAL_ 316 ENG_SHFT_IN_NEUTRAL_13C_2 1 "Shift lever at the neutral pos." 0 "Shift lever not at neutral pos." ;
VAL_ 316 ENG_SHFT_IN_REVERSE_13C_2 1 "Shift lever at reverse position." 0 "Shift lever not at reverse pos." ;
VAL_ 316 ENG_CLUTCH_SW_CC_13C_2 1 "Clutch pedal is applied." 0 "Clutch pedal is NOT applied." ;
VAL_ 316 ENG_VSA_ACK1_13C_2 15 "Reserved" 14 "Reserved" 13 "Reserved" 12 "Reserved" 11 "Reserved" 10 "Reserved" 9 "Reserved" 8 "Reserved" 7 "Reserved" 6 "Reserved" 5 "Reserved" 4 "Reserved" 3 "Reserved" 2 "All-cylinder F/C" 1 "Ignition retard" 0 "No fuel/ignition control" ;
VAL_ 316 ENG_VSA_PERMIT_PLUS_TRQ_13C_2 1 "MSR+ torq req frm VSA permitted" 0 "MSR+ torq req frm VSA rejected" ;
VAL_ 316 ENG_RECEIVE_ERROR_1AA_2 1 "receiving error" 0 "No receiving error" ;
VAL_ 316 ENG_VSA_INHIBIT_VSA_CONTRL_13C_2 1 "ENG fail-refuse vsa ctrl" 0 "VSA control permitted" ;
VAL_ 316 ENG_VSA_REFUSED_VSA_CONTRL_13C_2 1 "ENG fail-refuse vsa ctrl" 0 "VSA control permitted" ;
VAL_ 985 VSA_ABS_DISABLE_EDR_2 1 "ABS control is prohibited" 0 "Disable ABS control" ;
VAL_ 985 VSA_STABILITY_CTRL1_DSABLE_EDR_2 1 "Atleast 1 ctrl prohibited" 0 "All stability ctrl prohibited " ;
VAL_ 985 VSA_STABILITY_CTRL2_DSABLE_EDR_2 1 "Atleast 1 ctrl prohibited" 0 "All stability ctrl prohibited " ;
VAL_ 985 VSA_VSA_EQUIPPED_EDR_2 1 "Description for the value '1'" 0 "VSA unit is not equipped " ;
VAL_ 985 VSA_ABS_ACT_EDR_2 1 "ABS control is activated" 0 "ABS control not in operation" ;
VAL_ 985 VSA_STABILITY_CTRL_ACT_EDR_2 1 "Atleast one control operating" 0 "All stabilty ctrls not operation" ;
VAL_ 985 VSA_VSA_OFF_STATUS_EDR_2 1 "ESC function is turned off" 0 "ESC function is not turned off" ;
VAL_ 808 ENG_STRNNEND_2 1 "Eng cranking completed" 0 "Except above" ;
VAL_ 804 ENG_SW_STATUS_SCS_2 1 "Description for the value '0x1'" 0 "Normal time" ;
VAL_ 388 ESB_IG_ON_2 1 "ON" 0 "OFF" ;
VAL_ 388 ESB_BHOLD_STATUS_ACT_2 1 "Vehicle hold by ESB is operating" 0 "Vehicle hld by ESB not operating" ;
VAL_ 388 ESB_REQUEST_EPB_ACT_2 1 "EPB activation request ON" 0 "EPB activation request OFF" ;
VAL_ 388 ESB_HBC_REQ_184_2 1 "HBC Control is required" 0 "HBC Control is NOT required" ;
VAL_ 388 ESB_ACT_BRAKERELAY_2 1 "ESB unit driving brk lamp relay" 0 "Except above" ;
VAL_ 388 ESB_INHIBIT_BRAKERELAY_2 1 "Brk lamp relay temp disabled" 0 "Except below" ;
VAL_ 388 ESB_FAIL_BRAKERELAY_2 1 "Brk lamp relay failure confirmed" 0 "Except below" ;
VAL_ 388 ESB_VSA_INCREASE_PRESSURE_ACT2_2 1 "ESB Auto Pressurization Active" 0 "ESB Auto Pressurization Inactive" ;
VAL_ 388 ESB_VSA_CONTROL_LIMIT_2 1 "VSA Control Limit exist" 0 "VSA Control Limit does NOT exist" ;
VAL_ 388 ESB_EPB_INHBIT_BRAKE_2 1 "EPB Press Ctrl Req inh temporily" 0 "EPB Pressure Ctrl Req Permitted" ;
VAL_ 388 ESB_EPB_REFUSE_BRAKE_2 1 "EPB Pressure Ctrl Req Refused" 0 "EPB Pressure Ctrl Req permit" ;
VAL_ 388 ESB_ECD_ACT_2 1 "EPB Pressure Ctrl Active" 0 "EPB Pressure Ctrl not Active" ;
VAL_ 450 VSA_EPB_DAR_DISABLE_2 1 "DAR fucntion is disabled " 0 "Except above" ;
VAL_ 450 EPB_FAIL_2 1 "EPB operation Normal" 0 "EPB Fail" ;
VAL_ 450 VSA_EPB_WARN_LAMP_2 1 "Warn Lamp ON" 0 "Warn Lamp OFF" ;
VAL_ 450 VSA_EPB_PARK_BUSY_2 1 "EPB Operation complete" 0 "EPB operation not complete" ;
VAL_ 450 VSA_EPB_REQ_INFO_WARNING_2 1 "Display ON" 0 "Display OFF" ;
VAL_ 450 VSA_EPB_REQ_INFO_MANREL_2 1 "Display ON" 0 "Display OFF" ;
VAL_ 450 VSA_EPB_REQ_INFO_AUTOREL_2 1 "Display ON" 0 "Display OFF" ;
VAL_ 450 VSA_EPB_INHIBIT_ACT_2 1 "EPB operation temp inhibition" 0 "EPB operation enabled

" ;
VAL_ 450 VSA_EPB_REFUSE_ACT_2 1 "EPB_Operation Enabled" 0 "EPB_Operation Disabled" ;
VAL_ 450 VSA_EPB_STAY_AWAKE_REQ_VSA_2 1 "Stay Awake ON" 0 "Stay Awake OFF" ;
VAL_ 450 VSA_EPB_REQ_BRAKE_CTRL_2 1 "Fluid_Pressure_ctrl_request_ON" 0 "Fluid_Pressure_ctrl_request_OFF" ;
VAL_ 274 VSA_EPB_CLUTCH_PEDAL_FAIL_2 1 "Pedal stroke sensor failure" 0 "Pedal stroke sensor normal" ;
VAL_ 356 METER_SW_STATUS_BHOLD_SENKOSYA_2 1 "Brake hold ON" 0 "Brake hold switch OFF" ;
VAL_ 356 METER_SW_STATUS_PARK_BRAKE_2 1 "Parking Brake ON" 0 "Parking Brake OFF" ;
VAL_ 356 METER_SW_STATUS_BRAKE_FLUID_2 1 "Brake fluid level ON" 0 "Brake fluid level OFF" ;
VAL_ 356 METER_SW_STATUS_VSA_OFF_2 1 "VSA OFF switch ON" 0 "VSA OFF switch OFF" ;
VAL_ 392 EAT_SW_STATUS_SMODE 1 "SMODE" 0 "Normal Mode" ;
VAL_ 392 EAT_FAILURE_FOR_VSA_2 1 "refuse vsa ctrl at outbrk" 0 "vsa ctrl normal time" ;
VAL_ 392 EAT_GEAR_POSITION_TARGET_2 7 "6th" 6 "Reverse" 5 "5th" 4 "4th" 3 "3rd" 2 "2nd" 1 "1st" 0 "Neutral" ;
VAL_ 392 EAT_GEAR_POSITION_ACTUAL_2 15 "Reserved" 14 "Reserved" 13 "Reserved" 12 "Reserved" 11 "Reserved" 10 "Reserved" 9 "Reserved" 8 "6th" 7 "During Speed change" 6 "Reserve" 5 "5th" 4 "4th" 3 "3rd" 2 "2nd" 1 "1st" 0 "Neutral" ;
VAL_ 401 CVT_SW_STATUS_SMODE_2 1 "SMODE" 0 "Normal Mode" ;
VAL_ 401 CVT_REFUSE_VSA_CONTROL_2 1 "refuse vsa ctrl at outbrk" 0 "vsa ctrl normal time" ;
VAL_ 401 CVT_GEAR_POSITION_IND_CVT_2 10 "Reserved" 9 "Reserved" 8 "Reserved" 7 "7th" 6 "6th" 5 "5th" 4 "4th" 3 "3rd" 2 "2nd" 1 "1st" 0 "OFF" ;
VAL_ 380 ENG_ACCELE_FAIL_INFORMATION_2 1 "Acceleration pedal failure" 0 "Acceleration pedal normal" ;
VAL_ 380 ENG_CRUISE_STATUS_CRUISE_INH_2 1 "Cruise control prohibited" 0 "Cruise control permitted" ;
VAL_ 380 ENG_IS_PRE_RESTART_2 1 "Advnce notifictin of re-crankin" 0 "Except above" ;
VAL_ 380 ENG_IS_PROGRESS_2 1 "Idle Stp Ctrl started & ongoing" 0 "Except above" ;
VAL_ 380 ENG_SW_STATUS_BRAKE_NO_2 1 "Brake switch ON" 0 "Brake switch OFF" ;
VAL_ 380 ENG_CRUISE_STATUS_CRUISE_LMP_2 1 "Cruise control lamp ON" 0 "Cruise control lamp OFF" ;
VAL_ 304 ENG_PP_DISABLE_2 1 "Vehicle is not  running" 0 "Vehicle is running" ;
VAL_ 304 ENG_CLUTCH_SW_SIL_2 1 "Clutch pedal is NOT depressed" 0 "Clutch pedal is depressed" ;
VAL_ 304 ENG_EV_DRIVE_STATE_2 1 "EV drive" 0 "ENG drive" ;
VAL_ 304 ENG_BRK_ACCELE_PEDAL_ON_2 1 "accele pedal stepped on." 0 "accele pedal not stepped on." ;
VAL_ 304 ENG_SHFT_IN_REVERSE_2 1 "Shift lever at reverse position." 0 "Shift lever not at reverse pos." ;
VAL_ 304 ENG_NEUTRAL_SENSOR_FAIL_2 1 "NEUTRAL SENSOR failure" 0 "NEUTRAL SENSOR normal" ;
VAL_ 304 ENG_RECEIVE_ERROR_1AC_2 1 "receiving error" 0 "No receiving error" ;
VAL_ 304 ENG_SHFT_IN_NEUTRAL_2 1 "Shift lever at the neutral pos." 0 "Shift lever not at neutral pos." ;
VAL_ 304 ENG_CLUTCH_SW_CC_2 1 "Clutch pedal is applied." 0 "Clutch pedal is NOT applied." ;
VAL_ 304 ENG_VSA_ACK1_2 15 "Reserved" 14 "Reserved" 13 "Reserved" 12 "Reserved" 11 "Reserved" 10 "Reserved" 9 "Reserved" 8 "Reserved" 7 "Reserved" 6 "Reserved" 5 "Reserved" 4 "Reserved" 3 "Reserved" 2 "All-cylinder F/C" 1 "Ignition retard" 0 "No fuel/ignition control" ;
VAL_ 304 ENG_VSA_PERMIT_PLUS_TRQ_2 1 "MSR+ torq req frm VSA permitted" 0 "MSR+ torq req frm VSA rejected" ;
VAL_ 304 ENG_VSA_INHIBIT_VSA_CONTROL_1_2 1 "ENG fail-refuse vsa ctrl" 0 "VSA control permitted" ;
VAL_ 304 ENG_VSA_REFUSED_VSA_CONTROL_1_2 1 "ENG fail-refuse vsa ctrl" 0 "VSA control permitted" ;
VAL_ 545 METER_ECONSW_ON_2 1 "ECON SW ON" 0 "ECON SW OFF" ;
VAL_ 545 METER_SW_STATUS_MODE_2 6 "Reserved" 5 "+R" 4 "SNOW" 3 "ECON" 2 "COMFORT" 1 "SPORT" 0 "NORMAL" ;
VAL_ 578 E4WD_REAR_DISTRIBUTION_242_2 10 "500" 9 "450" 8 "400" 7 "350" 6 "300" 5 "250" 4 "200" 3 "150" 2 "100" 1 "50" 0 "0" ;
VAL_ 476 ENG_IDS_MODE_TARGET_2 15 "Mode 15" 14 "Mode 14" 13 "Mode 13" 12 "Mode 12" 11 "Mode 11" 10 "Mode 10" 9 "Mode 9" 8 "Mode 8" 7 "Mode 7" 6 "Mode 6" 5 "Mode 5" 4 "Mode 4" 3 "Mode 3" 2 "Mode 2" 1 "Mode 1" 0 "Mode 0" ;
VAL_ 476 ENG_IDS_MODE_CONTROL_2 8 "Reserved" 7 "TRUCK" 6 "+R

" 5 "TOW" 4 "SNOW" 3 "ECON" 2 "COMFORT" 1 "SPORT" 0 "NORMAL" ;
VAL_ 334 E4WD_ERROR_STATUS_14E_2 1 "E4WD failure has occurred

" 0 "E4WD is operating normally

" ;
VAL_ 1029 METER_WARN_STATUS_TIRE_PRESS_2 1 "Tire Press lit" 0 "Tire press goes off" ;
VAL_ 1029 METER_WARN_STATUS_TPMS_SYSTEM_2 1 "TPMS lit" 0 "TPMS goes off" ;
VAL_ 819 TPMS_WARN_STATUS_ISO_2 1 "ISO_W / L lighting" 0 "ISO_W / L off" ;
VAL_ 819 TPMS_WARN_STATUS_SYSTEM_2 1 "TPMS_W / L lit" 0 "Description for the value '0x0'" ;
VAL_ 487 VSA_HSA_STATUS_ACT_1E7_2 1 "HSA operating" 0 "HSA inactive" ;
VAL_ 487 VSA_INHBIT_CALIPPER_PRESSRE_FR_2 1 "Cal fluid pres sensor not normal" 0 "Cal fluid pres sensor normal" ;
VAL_ 487 VSA_FAIL_CALIPPER_PRESSURE_FR_2 1 "Calip pressure sensor abnormal" 0 "Caliper pressure sensor normal" ;
VAL_ 487 VSA_INHBIT_CALIPPER_PRESSRE_FL_2 1 "Cal fluid pres sensor not normal" 0 "Cal fluid pres sensor normal" ;
VAL_ 487 VSA_FAIL_CALIPPER_PRESSURE_FL_2 1 "Calip pressure sensor abnormal" 0 "Caliper pressure sensor normal" ;
VAL_ 432 VSA_ABS_BUSY_2 1 "Brk regenratn end reqst 

" 0 "Other" ;
VAL_ 432 VSA_EPT_COMFORT_TRIG_2 1 "E-PT is ON

" 0 "Description for the value '0x0'" ;
VAL_ 432 VSA_EPT_PRECRASH_TRIG_2 1 "E-PT is ON

" 0 "Description for the value '0x0'" ;
VAL_ 432 VSA_ABS_ENB_VW_SENSOR_ACT_2 1 "Normal operation of  wss " 0 "other" ;
VAL_ 432 VSA_INHBIT_LONG_G_SENSOR_2 1 "sensor normalcy not confirmed

" 0 "sensor normalcy confirmed" ;
VAL_ 432 VSA_FAIL_LONG_G_SENSOR_2 1 "Sensor failed" 0 "Sensor normal" ;
VAL_ 432 VSA_ACC_REFUSE_ACC_BRAKE_2 1 "CMBS is prohibited. 

" 0 "CMBS enabled 

" ;
VAL_ 432 VSA_ACC_INHIBIT_ACC_BRAKE_2 1 "CMBS temporarily disabled 

" 0 "CMBS enabled " ;
VAL_ 432 VSA_ABS_VW_SENSOR_START_UP_2 1 "Wheel speed sensor started " 0 "other" ;
VAL_ 432 VSA_INHIBIT_BRAKERELAY_2 1 "Brk lamp relay temporary dsble

" 0 "other" ;
VAL_ 432 VSA_INHBIT_LAT_G_SENSOR_2 1 "sensor normalcy not confirmed

" 0 "sensor normalcy confirmed" ;
VAL_ 432 VSA_FAIL_LAT_G_SENSOR_2 2 "Sensor normal" 1 "Sensor failed" ;
VAL_ 432 VSA_ACT_BRAKERELAY_2 1 "VSA activates the brk lamp relay" 0 "other" ;
VAL_ 432 VSA_REQ_CVT_TCS_2 1 "TCS or MSR oprtn permitted 

" 0 "TCS & MSR oprtn prohibited 

" ;
VAL_ 432 VSA_REQ_CVT_PRS_2 1 "Func at brk OFF are controlled  " 0 "other" ;
VAL_ 432 VSA_CONTROL_MODE_CVT_2 3 "Reserved" 2 "Reserved" 1 "TCS/MSR is operating 

" 0 "Normal" ;
VAL_ 432 VSA_ABS_STATUS_FR_ABS_EBD_ACT_2 1 "Wheel ABS operating" 0 "Wheel ABS not operating" ;
VAL_ 432 VSA_ABS_STATUS_FL_ABS_EBD_ACT_2 1 "Wheel ABS operating" 0 "Wheel ABS not operating" ;
VAL_ 432 VSA_ABS_STATUS_RR_ABS_EBD_ACT_2 1 "Wheel ABS operating" 0 "Wheel ABS not operating" ;
VAL_ 432 VSA_ABS_STATUS_RL_ABS_EBD_ACT_2 1 "Wheel ABS operating" 0 "Wheel ABS not operating" ;
VAL_ 432 VSA_FAIL_STEERING_SENSOR_2 1 "Sensor is faulty 

" 0 "Sensor is normal

" ;
VAL_ 432 VSA_FAIL_YAW_RATE_SENSOR_2 1 "Sensor is faulty 

" 0 "Sensor is normal

" ;
VAL_ 432 VSA_FAIL_MC_PRESSRE_SENSOR_1B0_2 1 "Sensor is faulty 

" 0 "Sensor is normal

" ;
VAL_ 432 VSA_ABS_FAIL_FR_VW_SENSOR_2 1 "Sensor is faulty 

" 0 "Sensor is normal

" ;
VAL_ 432 VSA_ABS_FAIL_FL_VW_SENSOR_2 1 "Sensor is faulty 

" 0 "Sensor is normal

" ;
VAL_ 432 VSA_ABS_FAIL_RR_VW_SENSOR_2 1 "Sensor is faulty 

" 0 "Sensor is normal

" ;
VAL_ 432 VSA_ABS_FAIL_RL_VW_SENSOR_2 1 "Sensor is faulty 

" 0 "Sensor is normal

" ;
VAL_ 432 VSA_ABS_INHBIT_VW_SENSOR_2 1 "sensor normalcy not confirmed

" 0 "sensor normalcy confirmed" ;
VAL_ 432 VSA_ACC_INHIBIT_CVRS_BRAKE_2 1 "CMBS temporarily disabled 

" 0 "CMBS enabled " ;
VAL_ 432 VSA_INHBIT_STEERING_SENSOR_2 1 "sensor normalcy not confirmed

" 0 "sensor normalcy confirmed" ;
VAL_ 432 VSA_ACC_REFUSE_CVRS_BRAKE_2 1 "CMBS is prohibited. 

" 0 "CMBS enabled 

" ;
VAL_ 432 VSA_VW_PULSE_CAPTURED_2 1 "Description for the value '0x1'" 0 "No wheel speed pulse 

" ;
VAL_ 432 VSA_INHBIT_YAW_RATE_SENSOR_2 1 "sensor normalcy not confirmed

" 0 "sensor normalcy confirmed" ;
VAL_ 432 VSA_FAIL_BRAKERELAY_2 1 "Brake lamp relay being failed

" 0 "other" ;
VAL_ 432 VSA_SS30_BRAKE_ACT_2 1 "CTBA uppr limt speed or less

" 0 "CTBA uppr limt speed or more" ;
VAL_ 428 VSA_BTCS_ACT_1AC_2 1 "BTCS is active" 0 "BTCS is not active" ;
VAL_ 428 VSA_IG_ON_2 1 "VSA IG ON" 0 "VSA IG OFF

" ;
VAL_ 428 VSA_EBB_FAILURE_FOR_IS_2 1 "EBB CPU failure 

" 0 "Normal" ;
VAL_ 428 VSA_IDS_INHIBIT_DISABLED_STATE_2 1 "VSA function is disabled

" 0 "VSA function is enabled

" ;
VAL_ 428 VSA_IDS_INHIBIT_ACT_2 1 "functions under activation" 0 "other" ;
VAL_ 428 VSA_HAC_CUT_REQ_2 1 "AC cut Request 

" 0 "No request

" ;
VAL_ 428 VSA_HBB_IS_REFUSE_REQ_2 1 "Idle Stp Prohibitn Req" 0 "No request" ;
VAL_ 428 VSA_LOW_VAC_IS_SHFT_INHBIT_REQ_2 1 "Idle Stp Prohibitn Req" 0 "No request" ;
VAL_ 428 VSA_MNTMODE_STATUS_2 1 "VSA maintenance mode

" 0 "NOT in  VSA maintenance mode

" ;
VAL_ 428 VSA_REVERSE_SWITCH_FAIL_2 1 "Back light switch fails" 0 "Back light switch does NOT fail" ;
VAL_ 428 VSA_SHFT_IN_REVERSE_2 1 "Back light switch is ON. " 0 "Back light switch is OFF" ;
VAL_ 428 VSA_ECD_ACT_2 1 "EPB fluid pres ctrl ongoing 

" 0 "ctrl not ongoing 

" ;
VAL_ 428 VSA_FAIL_FOR_EPB_2 1 "Abnormal" 0 "Normal" ;
VAL_ 428 VSA_REQUEST_EPB_ACT_2 1 "EPB activation request ON " 0 "EPB activation request OFF " ;
VAL_ 428 VSA_EPB_INHIBIT_BRAKE_2 1 "Temporarily prohibited" 0 "Permitted" ;
VAL_ 428 VSA_HBB_IS_SHIFT_INHIBIT_REQ_2 1 "Idle Stp Prohibitn Req" 0 "No request" ;
VAL_ 428 VSA_TSA_ACT_2 1 "TSA Control is Active

" 0 "TSA Control is NOT Active

" ;
VAL_ 428 VSA_ISAB_ACT_2 1 "In ISAB control

" 0 "NOT in ISAB control" ;
VAL_ 428 VSA_IS_RESTART_INHIBIT_REQUEST_2 1 "Idle Stp Prohibitn Req" 0 "No request" ;
VAL_ 428 VSA_ISAB_ENABLE_2 1 "permitted" 0 "prohibited" ;
VAL_ 428 VSA_IS_SHIFT_INHIBIT_REQUEST_1_2 1 "Idle Stp Prohibitn Req" 0 "No request" ;
VAL_ 428 VSA_SHIFT_REQ_1AC_2 3 "Description for the value '0x3'" 2 "Shift up request 

" 1 "Shift hold request

" 0 "No shift ctrl request from VSA " ;
VAL_ 428 VSA_REQ_MSR_PLUS_TRQ_2 1 "Plus torque is requested

" 0 "No request" ;
VAL_ 428 VSA_TRQ_CONTROL_MODE_2 3 "VSA/TCS prohibited " 2 "Acceleration control ongoing 

" 1 "MSR control ongoing " 0 "No VSA/TCS control 

" ;
VAL_ 428 VSA_TRQ_DOWN_REQ_FUEL_CUT_2 3 "Reserved" 2 "All-cylinders F/C + ig retard 

" 1 "Ignition retard 

" 0 "No fuel/ignition control " ;
VAL_ 420 VSA_VSA_OS_CTRL_2 1 "steer suppress ctrl in progress" 0 "steer suppress ctrl not in prog" ;
VAL_ 420 VSA_ESB_INCREASE_PRESS_ACT_2 1 "Req for switch to hold is ON

" 0 " No display 

" ;
VAL_ 420 VSA_WARN_STATUS_BHOLD_2 1 "MID Warning Enabled" 0 "MID Warning Disabled" ;
VAL_ 420 VSA_MID_REQ_BHOLD_STANDBY_2 1 "Brake hold in standby mode

" 0 "Brake hold NOT in standby mode" ;
VAL_ 420 VSA_MID_REQ_BHOLD_MISOP_GUIDE_2 3 "Description for the value '3'" 2 "Bhold exit condtn unsatisfied " 1 "Bhold enter condtn unsatisfied " 0 "No Display" ;
VAL_ 420 VSA_MID_REQ_BHOLD_EPB_OP_INFO_2 1 "BHOLD transtn to EPB MID

" 0 "Do not display. " ;
VAL_ 420 VSA_MID_REQ_BHOLD_APPLY_BRAKE_2 1 "Brake pedal apply request is ON" 0 "No Display" ;
VAL_ 420 VSA_WARN_STATUS_BRAKESYSTEM_2 1 "Lamp is ON

" 0 "Lamp is OFF

" ;
VAL_ 420 VSA_LAMP_BHOLD_APPLY_BRAKE_2 1 "Lamp is ON

" 0 "Lamp is OFF

" ;
VAL_ 420 VSA_BHOLD_STATUS_ACT_2 1 "Brk hold by LSF operating " 0 "Brk hold by LSF not operating " ;
VAL_ 420 VSA_LAMP_STATUS_HDC_2 1 "Lamp is ON

" 0 "Lamp is OFF

" ;
VAL_ 420 VSA_WARN_STATUS_HDC_2 1 "ON request" 0 "OFF request" ;
VAL_ 420 VSA_LAMP_STATUS_OPERATE_BHOLD_2 1 "Lamp is ON

" 0 "Lamp is OFF

" ;
VAL_ 420 VSA_LAMP_STATUS_STANBY_BHOLD_2 1 "Lamp is ON

" 0 "Lamp is OFF

" ;
VAL_ 420 VSA_AHA_CTRL_2 1 "AHA operating " 0 "AHA not operating " ;
VAL_ 420 VSA_ACC_BRAKE_ACT_2 1 "rear end brk /ACC controlled

" 0 "rearend brk/ACC not controlled

" ;
VAL_ 420 VSA_WARN_STATUS_PUNCTURE_2 1 "Lamp is ON

" 0 "Lamp is OFF

" ;
VAL_ 420 VSA_WARN_STATUS_DWS_2 1 "Lamp is ON

" 0 "Lamp is OFF

" ;
VAL_ 420 VSA_ANSWER_DWS_INIT_REQ_2 1 "Received DWS init req

" 0 "--" ;
VAL_ 420 VSA_L_MODE_ABS_EBD_2 1 "ABS/EBD is in L-MODE

" 0 "ABS/EBD is in non-L-MODE

" ;
VAL_ 420 VSA_ABS_CTRL_2 1 "ABS is operating

" 0 "ABS is not operating

" ;
VAL_ 420 VSA_VSA_CTRL_2 1 "VSA is operating

" 0 "VSA is not operating

" ;
VAL_ 420 VSA_WARN_STATUS_HSA_2 1 "HSA warning (MID) enabled" 0 "HSA warning (MID) disabled

" ;
VAL_ 420 VSA_HSA_STATUS_ACT_2 1 "HSA is operating

" 0 "HSA is not operating" ;
VAL_ 420 VSA_ESS_ACT4_2 1 "Continue of ESS operatn enabled" 0 "Continue of ESS operatn disabled" ;
VAL_ 420 VSA_ESS_ACT3_2 1 "Start of ESS operation enabled " 0 "Start of ESS operation disabled " ;
VAL_ 420 VSA_REWRITE_START_2 1 "VSA rewriting start" 0 "Normal" ;
VAL_ 420 VSA_BUZZER_STATUS_2 1 "Lamp is ON

" 0 "Lamp is OFF

" ;
VAL_ 420 VSA_MID_REQUEST_VSA_2 1 "VSA MID warning disp enabled

" 0 "VSA MID warning disp disabled

" ;
VAL_ 420 VSA_LAMP_STATUS_VSA_OFF_2 1 "Lamp is ON

" 0 "Lamp is OFF

" ;
VAL_ 420 VSA_WARN_STATUS_VSA_2 1 "Lamp is ON

" 0 "Lamp is OFF

" ;
VAL_ 420 VSA_WARN_STATUS_ABS_2 1 "Lamp is ON

" 0 "Lamp is OFF

" ;
VAL_ 420 VSA_WARN_STATUS_BRAKE_2 1 "Lamp is ON

" 0 "Lamp is OFF

" ;
VAL_ 420 VSA_VSA_TCS_ACT_2 1 "VSA or TCS is operating

" 0 "VSA and TCS are not operating

" ;
VAL_ 420 VSA_ABS_EBD_ACT_2 1 "ABS or EBD is operating

" 0 "ABS and EBD are not operating

" ;
VAL_ 420 VSA_VSA_TCS_MIL_2 1 "VSA or TCS failure is detected

" 0 "VSA and TCS are normal

" ;
VAL_ 420 VSA_ABS_EBD_MIL_2 1 "Detecting ABS or EBD failure

" 0 "ABS and EBD are normal

" ;
VAL_ 420 VSA_CASEN_2 1 "CAS control is possible

" 0 "CAS control is not possible

" ;
VAL_ 420 VSA_CAS_ACT_2 1 "In CAS control

" 0 "Not In CAS control" ;
VAL_ 420 VSA_BA_ACT_2 1 "BA is being controlled

" 0 "BA is not being controlled" ;
VAL_ 420 VSA_FAIL_MC_PRESSURE_SENSOR_1_2 1 "Sensor is faulty" 0 "Sensor is normal" ;
VAL_ 420 VSA_INHBIT_MC_PRESSURE_SENSOR_2 1 " mc pres sensr norml:not confirm" 0 " mc pres sensr norml:confirm" ;
VAL_ 420 VSA_ESS_ACT2_2 1 "Continue of ESS operatn enabled" 0 "Continue of ESS operatn disabled" ;
VAL_ 420 VSA_ESS_ACT1_2 1 "Start of ESS operation enabled " 0 "Start of ESS operation disabled " ;
VAL_ 145 VSA_SENSOR_START_UP_2 1 "During start check" 0 "start check normal" ;
VAL_ 145 VSA_SENSOR_ERR_MC_2 1 "Fault confirmed by diag" 0 "Normal time" ;
VAL_ 145 VSA_SENSOR_STATE_IG_2 1 "volt cant protect func of sensor" 0 "Normal time" ;
VAL_ 145 VSA_P_ERR_LON_G_2 1 "front/rear G accelratn confirmed" 0 "Normal time" ;
VAL_ 145 VSA_P_ERR_LAT_G_2 1 "lateral G acceleration is fixed" 0 "Normal time" ;
VAL_ 145 VSA_P_ERR_DEGC_2 1 "temp data is fixed" 0 "Normal time" ;
VAL_ 145 VSA_P_ERR_YAW1_2 1 "failure of yaw rate is fixed" 0 "Normal time" ;
VAL_ 145 VSA_T_ERR_LON_G_2 1 "Acceleratn cant be guaranteed" 0 "Normal time" ;
VAL_ 145 VSA_T_ERR_LAT_G_2 1 "Acceleratn cant be guaranteed" 0 "Normal time" ;
VAL_ 145 VSA_T_ERR_DEGC_2 1 "Temp data cant be guaranteed" 0 "Normal time" ;
VAL_ 145 VSA_T_ERR_YAW1_2 1 "YAW1 cannot be guaranteed" 0 "Normal Time" ;
